VERSION ""

NS_ :

BS_:

BU_: FLC2 DACU

BO_ 2671902706 TesterFuncDiagMsg_Vic2: 8 DACU
 SG_ FuncDiagDataTester : 0|64@1+ (1,0) [0|0] ""  FLC2

BO_ 2671833681 PhysDiagRespMsg_F2_51_Vic2: 8 FLC2
 SG_ PhysDiagRespSig_F2_51 : 0|64@1+ (1,0) [0|0] ""  VCM

BO_ 2671792626 PhysDiagReqMsg_51_F2_Vic2: 8 DACU
 SG_ PhysDiagReqSig_51_F2 : 0|64@1+ (1,0) [0|0] ""  FLC2

BO_ 2671902708 IntTesterTGW2FuncDiagMsg_Vic2: 8 DACU
 SG_ FuncDiagDataIntTesterTGW2 : 0|64@1+ (1,0) [0|0] ""  FLC2

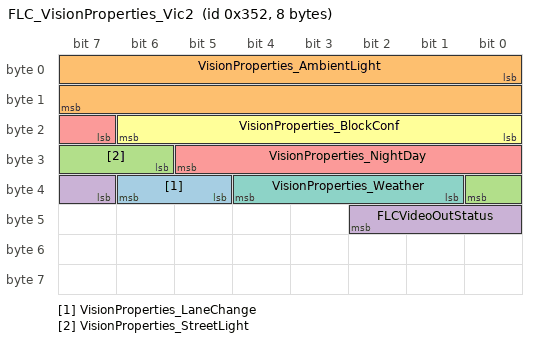
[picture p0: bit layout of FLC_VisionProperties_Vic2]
BO_ 850 FLC_VisionProperties_Vic2: 8 FLC2
 SG_ VisionProperties_LaneChange : 37|2@1+ (1,0) [0|0] ""  VCM
 SG_ VisionProperties_AmbientLight : 0|16@1+ (1,0) [0|65535] "lx"  VCM
 SG_ VisionProperties_StreetLight : 30|3@1+ (1,0) [0|0] ""  VCM
 SG_ FLCVideoOutStatus : 39|4@1+ (1,0) [0|0] ""  VCM
 SG_ VisionProperties_NightDay : 23|7@1+ (0.01,0) [0|1.27] "NotApplicable"  VCM
 SG_ VisionProperties_BlockConf : 16|7@1+ (0.01,0) [0|1.27] "NotApplicable"  VCM
 SG_ VisionProperties_Weather : 33|4@1+ (1,0) [0|0] ""  VCM

BO_ 872 FLC_TrafficSign11_Vic2: 32 FLC2
 SG_ TrafficSign11_SupplSignValue01 : 0|8@1+ (1,0) [0|255] ""  VCM
 SG_ TrafficSign11_SupplSignType02 : 94|7@1+ (1,0) [0|0] ""  VCM
 SG_ TrafficSign11_TrackStatus : 101|3@1+ (1,0) [0|0] ""  VCM
 SG_ TrafficSign11_SupplSignValue02 : 40|8@1+ (1,0) [0|255] ""  VCM
 SG_ TrafficSign11_RestDist : 139|15@1+ (1,0) [0|32767] "m"  VCM
 SG_ TrafficSign11_MainSignValue : 24|8@1+ (1,0) [0|255] ""  VCM
 SG_ TrafficSign11_SupplSignType01 : 87|7@1+ (1,0) [0|0] ""  VCM
 SG_ TrafficSign11_RestHeight : 181|7@1+ (0.1,0) [0|12.7] "m"  VCM
 SG_ TrafficSign11_SupplSign02Conf : 125|7@1+ (0.01,0) [0|1.27] ""  VCM
 SG_ TrafficSign11_MainSignConfidence : 104|7@1+ (0.01,0) [0|1.27] ""  VCM
 SG_ TrafficSign11_RestSection : 154|17@1+ (1,0) [0|131071] "m"  VCM
 SG_ TrafficSign11_RestTime1 : 213|11@1+ (1,0) [0|2047] "min"  VCM
 SG_ TrafficSign11_TimeStamp : 48|16@1+ (0.1,0) [0|6553.5] "ms"  VCM
 SG_ TrafficSign11_RestWeight : 171|10@1+ (0.1,0) [0|102.3] "NotApplicable"  VCM
 SG_ TrafficSign11_RestWidth : 188|7@1+ (0.1,0) [0|12.7] "m"  VCM
 SG_ TrafficSign11_Height : 64|5@1+ (0.2,0) [0|6.2] "m"  VCM
 SG_ TrafficSign11_MainSignType : 73|7@1+ (1,0) [0|0] ""  VCM
 SG_ TrafficSign11_ID : 32|8@1+ (1,0) [0|255] ""  VCM
 SG_ TrafficSign11_RestTime3 : 235|11@1+ (1,0) [0|2047] "min"  VCM
 SG_ TrafficSign11_SupplSignValue00 : 8|8@1+ (1,0) [0|255] ""  VCM
 SG_ TrafficSign11_RestDay : 195|7@1+ (1,0) [0|127] "NotApplicable"  VCM
 SG_ TrafficSign11_LongDist : 16|8@1+ (0.5,-20) [-20|107.5] "m"  VCM
 SG_ TrafficSign11_RestTime2 : 224|11@1+ (1,0) [0|2047] "min"  VCM
 SG_ TrafficSign11_SupplSignType00 : 80|7@1+ (1,0) [0|0] ""  VCM
 SG_ TrafficSign11_SupplSign00Conf : 111|7@1+ (0.01,0) [0|1.27] ""  VCM
 SG_ TrafficSign11_SupplSign01Conf : 118|7@1+ (0.01,0) [0|1.27] ""  VCM
 SG_ TrafficSign11_LatDist : 132|7@1+ (0.5,-31) [-31|32.5] "m"  VCM
 SG_ TrafficSign11_RestTime0 : 202|11@1+ (1,0) [0|2047] "min"  VCM
 SG_ TrafficSign11_SignStability : 72|1@1+ (1,0) [0|0] ""  VCM

BO_ 871 FLC_TrafficSign10_Vic2: 32 FLC2
 SG_ TrafficSign10_SupplSignType02 : 94|7@1+ (1,0) [0|0] ""  VCM
 SG_ TrafficSign10_SignStability : 72|1@1+ (1,0) [0|0] ""  VCM
 SG_ TrafficSign10_ID : 32|8@1+ (1,0) [0|255] ""  VCM
 SG_ TrafficSign10_SupplSignValue00 : 8|8@1+ (1,0) [0|255] ""  VCM
 SG_ TrafficSign10_RestTime2 : 224|11@1+ (1,0) [0|2047] "min"  VCM
 SG_ TrafficSign10_RestSection : 154|17@1+ (1,0) [0|131071] "m"  VCM
 SG_ TrafficSign10_SupplSign00Conf : 111|7@1+ (0.01,0) [0|1.27] ""  VCM
 SG_ TrafficSign10_MainSignType : 73|7@1+ (1,0) [0|0] ""  VCM
 SG_ TrafficSign10_RestTime3 : 235|11@1+ (1,0) [0|2047] "min"  VCM
 SG_ TrafficSign10_RestHeight : 181|7@1+ (0.1,0) [0|12.7] "m"  VCM
 SG_ TrafficSign10_RestTime1 : 213|11@1+ (1,0) [0|2047] "min"  VCM
 SG_ TrafficSign10_SupplSignType01 : 87|7@1+ (1,0) [0|0] ""  VCM
 SG_ TrafficSign10_RestWidth : 188|7@1+ (0.1,0) [0|12.7] "m"  VCM
 SG_ TrafficSign10_SupplSign02Conf : 125|7@1+ (0.01,0) [0|1.27] ""  VCM
 SG_ TrafficSign10_SupplSignValue01 : 0|8@1+ (1,0) [0|255] ""  VCM
 SG_ TrafficSign10_TimeStamp : 48|16@1+ (0.1,0) [0|6553.5] "ms"  VCM
 SG_ TrafficSign10_LongDist : 16|8@1+ (0.5,-20) [-20|107.5] "m"  VCM
 SG_ TrafficSign10_SupplSignValue02 : 40|8@1+ (1,0) [0|255] ""  VCM
 SG_ TrafficSign10_SupplSign01Conf : 118|7@1+ (0.01,0) [0|1.27] ""  VCM
 SG_ TrafficSign10_SupplSignType00 : 80|7@1+ (1,0) [0|0] ""  VCM
 SG_ TrafficSign10_Height : 64|5@1+ (0.2,0) [0|6.2] "m"  VCM
 SG_ TrafficSign10_TrackStatus : 101|3@1+ (1,0) [0|0] ""  VCM
 SG_ TrafficSign10_RestWeight : 171|10@1+ (0.1,0) [0|102.3] "NotApplicable"  VCM
 SG_ TrafficSign10_RestDay : 195|7@1+ (1,0) [0|127] "NotApplicable"  VCM
 SG_ TrafficSign10_MainSignConfidence : 104|7@1+ (0.01,0) [0|1.27] ""  VCM
 SG_ TrafficSign10_RestDist : 139|15@1+ (1,0) [0|32767] "m"  VCM
 SG_ TrafficSign10_RestTime0 : 202|11@1+ (1,0) [0|2047] "min"  VCM
 SG_ TrafficSign10_MainSignValue : 24|8@1+ (1,0) [0|255] ""  VCM
 SG_ TrafficSign10_LatDist : 132|7@1+ (0.5,-31) [-31|32.5] "m"  VCM

BO_ 870 FLC_TrafficSign09_Vic2: 32 FLC2
 SG_ TrafficSign09_MainSignValue : 24|8@1+ (1,0) [0|255] ""  VCM
 SG_ TrafficSign09_RestTime0 : 202|11@1+ (1,0) [0|2047] "min"  VCM
 SG_ TrafficSign09_LongDist : 16|8@1+ (0.5,-20) [-20|107.5] "m"  VCM
 SG_ TrafficSign09_SupplSign00Conf : 111|7@1+ (0.01,0) [0|1.27] ""  VCM
 SG_ TrafficSign09_MainSignConfidence : 104|7@1+ (0.01,0) [0|1.27] ""  VCM
 SG_ TrafficSign09_Height : 64|5@1+ (0.2,0) [0|6.2] "m"  VCM
 SG_ TrafficSign09_RestTime2 : 224|11@1+ (1,0) [0|2047] "min"  VCM
 SG_ TrafficSign09_MainSignType : 73|7@1+ (1,0) [0|0] ""  VCM
 SG_ TrafficSign09_SupplSignType02 : 94|7@1+ (1,0) [0|0] ""  VCM
 SG_ TrafficSign09_SupplSign01Conf : 118|7@1+ (0.01,0) [0|1.27] ""  VCM
 SG_ TrafficSign09_RestSection : 154|17@1+ (1,0) [0|131071] "m"  VCM
 SG_ TrafficSign09_SupplSign02Conf : 125|7@1+ (0.01,0) [0|1.27] ""  VCM
 SG_ TrafficSign09_SupplSignValue01 : 0|8@1+ (1,0) [0|255] ""  VCM
 SG_ TrafficSign09_RestWeight : 171|10@1+ (0.1,0) [0|102.3] "NotApplicable"  VCM
 SG_ TrafficSign09_LatDist : 132|7@1+ (0.5,-31) [-31|32.5] "m"  VCM
 SG_ TrafficSign09_SignStability : 72|1@1+ (1,0) [0|0] ""  VCM
 SG_ TrafficSign09_RestTime1 : 213|11@1+ (1,0) [0|2047] "min"  VCM
 SG_ TrafficSign09_SupplSignType00 : 80|7@1+ (1,0) [0|0] ""  VCM
 SG_ TrafficSign09_RestHeight : 181|7@1+ (0.1,0) [0|12.7] "m"  VCM
 SG_ TrafficSign09_RestDay : 195|7@1+ (1,0) [0|127] "NotApplicable"  VCM
 SG_ TrafficSign09_RestDist : 139|15@1+ (1,0) [0|32767] "m"  VCM
 SG_ TrafficSign09_SupplSignValue00 : 8|8@1+ (1,0) [0|255] ""  VCM
 SG_ TrafficSign09_TrackStatus : 101|3@1+ (1,0) [0|0] ""  VCM
 SG_ TrafficSign09_RestTime3 : 235|11@1+ (1,0) [0|2047] "min"  VCM
 SG_ TrafficSign09_SupplSignType01 : 87|7@1+ (1,0) [0|0] ""  VCM
 SG_ TrafficSign09_ID : 32|8@1+ (1,0) [0|255] ""  VCM
 SG_ TrafficSign09_RestWidth : 188|7@1+ (0.1,0) [0|12.7] "m"  VCM
 SG_ TrafficSign09_SupplSignValue02 : 40|8@1+ (1,0) [0|255] ""  VCM
 SG_ TrafficSign09_TimeStamp : 48|16@1+ (0.1,0) [0|6553.5] "ms"  VCM

BO_ 869 FLC_TrafficSign08_Vic2: 32 FLC2
 SG_ TrafficSign08_SupplSign00Conf : 111|7@1+ (0.01,0) [0|1.27] ""  VCM
 SG_ TrafficSign08_SignStability : 72|1@1+ (1,0) [0|0] ""  VCM
 SG_ TrafficSign08_MainSignType : 73|7@1+ (1,0) [0|0] ""  VCM
 SG_ TrafficSign08_SupplSign02Conf : 125|7@1+ (0.01,0) [0|1.27] ""  VCM
 SG_ TrafficSign08_RestHeight : 181|7@1+ (0.1,0) [0|12.7] "m"  VCM
 SG_ TrafficSign08_LatDist : 132|7@1+ (0.5,-31) [-31|32.5] "m"  VCM
 SG_ TrafficSign08_SupplSignType02 : 94|7@1+ (1,0) [0|0] ""  VCM
 SG_ TrafficSign08_SupplSignType01 : 87|7@1+ (1,0) [0|0] ""  VCM
 SG_ TrafficSign08_SupplSign01Conf : 118|7@1+ (0.01,0) [0|1.27] ""  VCM
 SG_ TrafficSign08_MainSignConfidence : 104|7@1+ (0.01,0) [0|1.27] ""  VCM
 SG_ TrafficSign08_RestSection : 154|17@1+ (1,0) [0|131071] "m"  VCM
 SG_ TrafficSign08_RestTime3 : 235|11@1+ (1,0) [0|2047] "min"  VCM
 SG_ TrafficSign08_TimeStamp : 48|16@1+ (0.1,0) [0|6553.5] "ms"  VCM
 SG_ TrafficSign08_RestDist : 139|15@1+ (1,0) [0|32767] "m"  VCM
 SG_ TrafficSign08_SupplSignType00 : 80|7@1+ (1,0) [0|0] ""  VCM
 SG_ TrafficSign08_RestTime2 : 224|11@1+ (1,0) [0|2047] "min"  VCM
 SG_ TrafficSign08_SupplSignValue02 : 40|8@1+ (1,0) [0|255] ""  VCM
 SG_ TrafficSign08_TrackStatus : 101|3@1+ (1,0) [0|0] ""  VCM
 SG_ TrafficSign08_RestWeight : 171|10@1+ (0.1,0) [0|102.3] "NotApplicable"  VCM
 SG_ TrafficSign08_SupplSignValue01 : 0|8@1+ (1,0) [0|255] ""  VCM
 SG_ TrafficSign08_RestTime0 : 202|11@1+ (1,0) [0|2047] "min"  VCM
 SG_ TrafficSign08_LongDist : 16|8@1+ (0.5,-20) [-20|107.5] "m"  VCM
 SG_ TrafficSign08_MainSignValue : 24|8@1+ (1,0) [0|255] ""  VCM
 SG_ TrafficSign08_RestWidth : 188|7@1+ (0.1,0) [0|12.7] "m"  VCM
 SG_ TrafficSign08_RestDay : 195|7@1+ (1,0) [0|127] "NotApplicable"  VCM
 SG_ TrafficSign08_ID : 32|8@1+ (1,0) [0|255] ""  VCM
 SG_ TrafficSign08_Height : 64|5@1+ (0.2,0) [0|6.2] "m"  VCM
 SG_ TrafficSign08_SupplSignValue00 : 8|8@1+ (1,0) [0|255] ""  VCM
 SG_ TrafficSign08_RestTime1 : 213|11@1+ (1,0) [0|2047] "min"  VCM

BO_ 868 FLC_TrafficSign07_Vic2: 32 FLC2
 SG_ TrafficSign07_MainSignConfidence : 104|7@1+ (0.01,0) [0|1.27] ""  VCM
 SG_ TrafficSign07_SupplSign00Conf : 111|7@1+ (0.01,0) [0|1.27] ""  VCM
 SG_ TrafficSign07_SupplSign01Conf : 118|7@1+ (0.01,0) [0|1.27] ""  VCM
 SG_ TrafficSign07_SupplSignValue00 : 8|8@1+ (1,0) [0|255] ""  VCM
 SG_ TrafficSign07_RestTime3 : 235|11@1+ (1,0) [0|2047] "min"  VCM
 SG_ TrafficSign07_SupplSign02Conf : 125|7@1+ (0.01,0) [0|1.27] ""  VCM
 SG_ TrafficSign07_ID : 32|8@1+ (1,0) [0|255] ""  VCM
 SG_ TrafficSign07_SupplSignType01 : 87|7@1+ (1,0) [0|0] ""  VCM
 SG_ TrafficSign07_TrackStatus : 101|3@1+ (1,0) [0|0] ""  VCM
 SG_ TrafficSign07_RestSection : 154|17@1+ (1,0) [0|131071] "m"  VCM
 SG_ TrafficSign07_SupplSignValue02 : 40|8@1+ (1,0) [0|255] ""  VCM
 SG_ TrafficSign07_SupplSignType00 : 80|7@1+ (1,0) [0|0] ""  VCM
 SG_ TrafficSign07_RestTime2 : 224|11@1+ (1,0) [0|2047] "min"  VCM
 SG_ TrafficSign07_Height : 64|5@1+ (0.2,0) [0|6.2] "m"  VCM
 SG_ TrafficSign07_LatDist : 132|7@1+ (0.5,-31) [-31|32.5] "m"  VCM
 SG_ TrafficSign07_SupplSignType02 : 94|7@1+ (1,0) [0|0] ""  VCM
 SG_ TrafficSign07_SignStability : 72|1@1+ (1,0) [0|0] ""  VCM
 SG_ TrafficSign07_RestDist : 139|15@1+ (1,0) [0|32767] "m"  VCM
 SG_ TrafficSign07_RestDay : 195|7@1+ (1,0) [0|127] "NotApplicable"  VCM
 SG_ TrafficSign07_RestWidth : 188|7@1+ (0.1,0) [0|12.7] "m"  VCM
 SG_ TrafficSign07_TimeStamp : 48|16@1+ (0.1,0) [0|6553.5] "ms"  VCM
 SG_ TrafficSign07_RestTime1 : 213|11@1+ (1,0) [0|2047] "min"  VCM
 SG_ TrafficSign07_RestTime0 : 202|11@1+ (1,0) [0|2047] "min"  VCM
 SG_ TrafficSign07_SupplSignValue01 : 0|8@1+ (1,0) [0|255] ""  VCM
 SG_ TrafficSign07_LongDist : 16|8@1+ (0.5,-20) [-20|107.5] "m"  VCM
 SG_ TrafficSign07_MainSignType : 73|7@1+ (1,0) [0|0] ""  VCM
 SG_ TrafficSign07_MainSignValue : 24|8@1+ (1,0) [0|255] ""  VCM
 SG_ TrafficSign07_RestWeight : 171|10@1+ (0.1,0) [0|102.3] "NotApplicable"  VCM
 SG_ TrafficSign07_RestHeight : 181|7@1+ (0.1,0) [0|12.7] "m"  VCM

BO_ 867 FLC_TrafficSign06_Vic2: 32 FLC2
 SG_ TrafficSign06_RestWeight : 171|10@1+ (0.1,0) [0|102.3] "NotApplicable"  VCM
 SG_ TrafficSign06_SupplSign01Conf : 118|7@1+ (0.01,0) [0|1.27] ""  VCM
 SG_ TrafficSign06_SupplSignValue02 : 40|8@1+ (1,0) [0|255] ""  VCM
 SG_ TrafficSign06_RestTime1 : 213|11@1+ (1,0) [0|2047] "min"  VCM
 SG_ TrafficSign06_SupplSignType02 : 94|7@1+ (1,0) [0|0] ""  VCM
 SG_ TrafficSign06_SignStability : 72|1@1+ (1,0) [0|0] ""  VCM
 SG_ TrafficSign06_SupplSign00Conf : 111|7@1+ (0.01,0) [0|1.27] ""  VCM
 SG_ TrafficSign06_MainSignValue : 24|8@1+ (1,0) [0|255] ""  VCM
 SG_ TrafficSign06_SupplSign02Conf : 125|7@1+ (0.01,0) [0|1.27] ""  VCM
 SG_ TrafficSign06_SupplSignValue01 : 0|8@1+ (1,0) [0|255] ""  VCM
 SG_ TrafficSign06_RestTime2 : 224|11@1+ (1,0) [0|2047] "min"  VCM
 SG_ TrafficSign06_Height : 64|5@1+ (0.2,0) [0|6.2] "m"  VCM
 SG_ TrafficSign06_LatDist : 132|7@1+ (0.5,-31) [-31|32.5] "m"  VCM
 SG_ TrafficSign06_MainSignType : 73|7@1+ (1,0) [0|0] ""  VCM
 SG_ TrafficSign06_LongDist : 16|8@1+ (0.5,-20) [-20|107.5] "m"  VCM
 SG_ TrafficSign06_TimeStamp : 48|16@1+ (0.1,0) [0|6553.5] "ms"  VCM
 SG_ TrafficSign06_RestDist : 139|15@1+ (1,0) [0|32767] "m"  VCM
 SG_ TrafficSign06_RestTime0 : 202|11@1+ (1,0) [0|2047] "min"  VCM
 SG_ TrafficSign06_SupplSignType01 : 87|7@1+ (1,0) [0|0] ""  VCM
 SG_ TrafficSign06_TrackStatus : 101|3@1+ (1,0) [0|0] ""  VCM
 SG_ TrafficSign06_MainSignConfidence : 104|7@1+ (0.01,0) [0|1.27] ""  VCM
 SG_ TrafficSign06_RestHeight : 181|7@1+ (0.1,0) [0|12.7] "m"  VCM
 SG_ TrafficSign06_RestSection : 154|17@1+ (1,0) [0|131071] "m"  VCM
 SG_ TrafficSign06_RestDay : 195|7@1+ (1,0) [0|127] "NotApplicable"  VCM
 SG_ TrafficSign06_SupplSignValue00 : 8|8@1+ (1,0) [0|255] ""  VCM
 SG_ TrafficSign06_ID : 32|8@1+ (1,0) [0|255] ""  VCM
 SG_ TrafficSign06_RestWidth : 188|7@1+ (0.1,0) [0|12.7] "m"  VCM
 SG_ TrafficSign06_RestTime3 : 235|11@1+ (1,0) [0|2047] "min"  VCM
 SG_ TrafficSign06_SupplSignType00 : 80|7@1+ (1,0) [0|0] ""  VCM

BO_ 866 FLC_TrafficSign05_Vic2: 32 FLC2
 SG_ TrafficSign05_SupplSignType00 : 80|7@1+ (1,0) [0|0] ""  VCM
 SG_ TrafficSign05_ID : 32|8@1+ (1,0) [0|255] ""  VCM
 SG_ TrafficSign05_SupplSignValue00 : 8|8@1+ (1,0) [0|255] ""  VCM
 SG_ TrafficSign05_MainSignConfidence : 104|7@1+ (0.01,0) [0|1.27] ""  VCM
 SG_ TrafficSign05_RestDay : 195|7@1+ (1,0) [0|127] "NotApplicable"  VCM
 SG_ TrafficSign05_MainSignType : 73|7@1+ (1,0) [0|0] ""  VCM
 SG_ TrafficSign05_SupplSignType01 : 87|7@1+ (1,0) [0|0] ""  VCM
 SG_ TrafficSign05_LongDist : 16|8@1+ (0.5,-20) [-20|107.5] "m"  VCM
 SG_ TrafficSign05_RestSection : 154|17@1+ (1,0) [0|131071] "m"  VCM
 SG_ TrafficSign05_MainSignValue : 24|8@1+ (1,0) [0|255] ""  VCM
 SG_ TrafficSign05_SupplSignValue01 : 0|8@1+ (1,0) [0|255] ""  VCM
 SG_ TrafficSign05_TimeStamp : 48|16@1+ (0.1,0) [0|6553.5] "ms"  VCM
 SG_ TrafficSign05_Height : 64|5@1+ (0.2,0) [0|6.2] "m"  VCM
 SG_ TrafficSign05_SupplSign02Conf : 125|7@1+ (0.01,0) [0|1.27] ""  VCM
 SG_ TrafficSign05_SignStability : 72|1@1+ (1,0) [0|0] ""  VCM
 SG_ TrafficSign05_SupplSignValue02 : 40|8@1+ (1,0) [0|255] ""  VCM
 SG_ TrafficSign05_TrackStatus : 101|3@1+ (1,0) [0|0] ""  VCM
 SG_ TrafficSign05_LatDist : 132|7@1+ (0.5,-31) [-31|32.5] "m"  VCM
 SG_ TrafficSign05_RestHeight : 181|7@1+ (0.1,0) [0|12.7] "m"  VCM
 SG_ TrafficSign05_RestTime1 : 213|11@1+ (1,0) [0|2047] "min"  VCM
 SG_ TrafficSign05_RestWidth : 188|7@1+ (0.1,0) [0|12.7] "m"  VCM
 SG_ TrafficSign05_RestTime3 : 235|11@1+ (1,0) [0|2047] "min"  VCM
 SG_ TrafficSign05_RestDist : 139|15@1+ (1,0) [0|32767] "m"  VCM
 SG_ TrafficSign05_RestTime2 : 224|11@1+ (1,0) [0|2047] "min"  VCM
 SG_ TrafficSign05_RestTime0 : 202|11@1+ (1,0) [0|2047] "min"  VCM
 SG_ TrafficSign05_SupplSign00Conf : 111|7@1+ (0.01,0) [0|1.27] ""  VCM
 SG_ TrafficSign05_SupplSignType02 : 94|7@1+ (1,0) [0|0] ""  VCM
 SG_ TrafficSign05_SupplSign01Conf : 118|7@1+ (0.01,0) [0|1.27] ""  VCM
 SG_ TrafficSign05_RestWeight : 171|10@1+ (0.1,0) [0|102.3] "NotApplicable"  VCM

BO_ 865 FLC_TrafficSign04_Vic2: 32 FLC2
 SG_ TrafficSign04_TrackStatus : 101|3@1+ (1,0) [0|0] ""  VCM
 SG_ TrafficSign04_MainSignType : 73|7@1+ (1,0) [0|0] ""  VCM
 SG_ TrafficSign04_SupplSignValue00 : 8|8@1+ (1,0) [0|255] ""  VCM
 SG_ TrafficSign04_RestTime1 : 213|11@1+ (1,0) [0|2047] "min"  VCM
 SG_ TrafficSign04_SupplSignValue01 : 0|8@1+ (1,0) [0|255] ""  VCM
 SG_ TrafficSign04_RestTime2 : 224|11@1+ (1,0) [0|2047] "min"  VCM
 SG_ TrafficSign04_Height : 64|5@1+ (0.2,0) [0|6.2] "m"  VCM
 SG_ TrafficSign04_SupplSign00Conf : 111|7@1+ (0.01,0) [0|1.27] ""  VCM
 SG_ TrafficSign04_SupplSign01Conf : 118|7@1+ (0.01,0) [0|1.27] ""  VCM
 SG_ TrafficSign04_SupplSign02Conf : 125|7@1+ (0.01,0) [0|1.27] ""  VCM
 SG_ TrafficSign04_SupplSignType02 : 94|7@1+ (1,0) [0|0] ""  VCM
 SG_ TrafficSign04_LongDist : 16|8@1+ (0.5,-20) [-20|107.5] "m"  VCM
 SG_ TrafficSign04_RestTime0 : 202|11@1+ (1,0) [0|2047] "min"  VCM
 SG_ TrafficSign04_RestWidth : 188|7@1+ (0.1,0) [0|12.7] "m"  VCM
 SG_ TrafficSign04_SupplSignType00 : 80|7@1+ (1,0) [0|0] ""  VCM
 SG_ TrafficSign04_RestDay : 195|7@1+ (1,0) [0|127] "NotApplicable"  VCM
 SG_ TrafficSign04_SupplSignType01 : 87|7@1+ (1,0) [0|0] ""  VCM
 SG_ TrafficSign04_MainSignConfidence : 104|7@1+ (0.01,0) [0|1.27] ""  VCM
 SG_ TrafficSign04_RestHeight : 181|7@1+ (0.1,0) [0|12.7] "m"  VCM
 SG_ TrafficSign04_MainSignValue : 24|8@1+ (1,0) [0|255] ""  VCM
 SG_ TrafficSign04_RestSection : 154|17@1+ (1,0) [0|131071] "m"  VCM
 SG_ TrafficSign04_RestDist : 139|15@1+ (1,0) [0|32767] "m"  VCM
 SG_ TrafficSign04_ID : 32|8@1+ (1,0) [0|255] ""  VCM
 SG_ TrafficSign04_RestTime3 : 235|11@1+ (1,0) [0|2047] "min"  VCM
 SG_ TrafficSign04_SignStability : 72|1@1+ (1,0) [0|0] ""  VCM
 SG_ TrafficSign04_LatDist : 132|7@1+ (0.5,-31) [-31|32.5] "m"  VCM
 SG_ TrafficSign04_TimeStamp : 48|16@1+ (0.1,0) [0|6553.5] "ms"  VCM
 SG_ TrafficSign04_SupplSignValue02 : 40|8@1+ (1,0) [0|255] ""  VCM
 SG_ TrafficSign04_RestWeight : 171|10@1+ (0.1,0) [0|102.3] "NotApplicable"  VCM

BO_ 849 FLC_TrafficSign03_Vic2: 32 FLC2
 SG_ TrafficSign03_Height : 64|5@1+ (0.2,0) [0|6.2] "m"  VCM
 SG_ TrafficSign03_ID : 32|8@1+ (1,0) [0|255] ""  VCM
 SG_ TrafficSign03_TrackStatus : 101|3@1+ (1,0) [0|0] ""  VCM
 SG_ TrafficSign03_RestHeight : 181|7@1+ (0.1,0) [0|12.7] "m"  VCM
 SG_ TrafficSign03_MainSignConfidence : 104|7@1+ (0.01,0) [0|1.27] ""  VCM
 SG_ TrafficSign03_RestDay : 195|7@1+ (1,0) [0|127] "NotApplicable"  VCM
 SG_ TrafficSign03_LongDist : 16|8@1+ (0.5,-20) [-20|107.5] "m"  VCM
 SG_ TrafficSign03_RestTime3 : 235|11@1+ (1,0) [0|2047] "min"  VCM
 SG_ TrafficSign03_SupplSignType00 : 80|7@1+ (1,0) [0|0] ""  VCM
 SG_ TrafficSign03_RestTime1 : 213|11@1+ (1,0) [0|2047] "min"  VCM
 SG_ TrafficSign03_SupplSignValue00 : 8|8@1+ (1,0) [0|255] ""  VCM
 SG_ TrafficSign03_RestTime0 : 202|11@1+ (1,0) [0|2047] "min"  VCM
 SG_ TrafficSign03_SupplSignType02 : 94|7@1+ (1,0) [0|0] ""  VCM
 SG_ TrafficSign03_RestWidth : 188|7@1+ (0.1,0) [0|12.7] "m"  VCM
 SG_ TrafficSign03_MainSignValue : 24|8@1+ (1,0) [0|255] ""  VCM
 SG_ TrafficSign03_RestTime2 : 224|11@1+ (1,0) [0|2047] "min"  VCM
 SG_ TrafficSign03_SupplSign01Conf : 118|7@1+ (0.01,0) [0|1.27] ""  VCM
 SG_ TrafficSign03_LatDist : 132|7@1+ (0.5,-31) [-31|32.5] "m"  VCM
 SG_ TrafficSign03_RestWeight : 171|10@1+ (0.1,0) [0|102.3] "NotApplicable"  VCM
 SG_ TrafficSign03_TimeStamp : 48|16@1+ (0.1,0) [0|6553.5] "ms"  VCM
 SG_ TrafficSign03_RestDist : 139|15@1+ (1,0) [0|32767] "m"  VCM
 SG_ TrafficSign03_SupplSign00Conf : 111|7@1+ (0.01,0) [0|1.27] ""  VCM
 SG_ TrafficSign03_SupplSignType01 : 87|7@1+ (1,0) [0|0] ""  VCM
 SG_ TrafficSign03_SupplSign02Conf : 125|7@1+ (0.01,0) [0|1.27] ""  VCM
 SG_ TrafficSign03_RestSection : 154|17@1+ (1,0) [0|131071] "m"  VCM
 SG_ TrafficSign03_SupplSignValue02 : 40|8@1+ (1,0) [0|255] ""  VCM
 SG_ TrafficSign03_MainSignType : 73|7@1+ (1,0) [0|0] ""  VCM
 SG_ TrafficSign03_SignStability : 72|1@1+ (1,0) [0|0] ""  VCM
 SG_ TrafficSign03_SupplSignValue01 : 0|8@1+ (1,0) [0|255] ""  VCM

BO_ 848 FLC_TrafficSign02_Vic2: 32 FLC2
 SG_ TrafficSign02_RestTime1 : 213|11@1+ (1,0) [0|2047] "min"  VCM
 SG_ TrafficSign02_RestHeight : 181|7@1+ (0.1,0) [0|12.7] "m"  VCM
 SG_ TrafficSign02_Height : 64|5@1+ (0.2,0) [0|6.2] "m"  VCM
 SG_ TrafficSign02_SignStability : 72|1@1+ (1,0) [0|0] ""  VCM
 SG_ TrafficSign02_SupplSignType00 : 80|7@1+ (1,0) [0|0] ""  VCM
 SG_ TrafficSign02_ID : 32|8@1+ (1,0) [0|255] ""  VCM
 SG_ TrafficSign02_LatDist : 132|7@1+ (0.5,-31) [-31|32.5] "m"  VCM
 SG_ TrafficSign02_MainSignType : 73|7@1+ (1,0) [0|0] ""  VCM
 SG_ TrafficSign02_SupplSignValue01 : 0|8@1+ (1,0) [0|255] ""  VCM
 SG_ TrafficSign02_SupplSign00Conf : 111|7@1+ (0.01,0) [0|1.27] ""  VCM
 SG_ TrafficSign02_SupplSignType01 : 87|7@1+ (1,0) [0|0] ""  VCM
 SG_ TrafficSign02_RestTime2 : 224|11@1+ (1,0) [0|2047] "min"  VCM
 SG_ TrafficSign02_MainSignConfidence : 104|7@1+ (0.01,0) [0|1.27] ""  VCM
 SG_ TrafficSign02_SupplSignValue02 : 40|8@1+ (1,0) [0|255] ""  VCM
 SG_ TrafficSign02_TimeStamp : 48|16@1+ (0.1,0) [0|6553.5] "ms"  VCM
 SG_ TrafficSign02_RestSection : 154|17@1+ (1,0) [0|131071] "m"  VCM
 SG_ TrafficSign02_RestDist : 139|15@1+ (1,0) [0|32767] "m"  VCM
 SG_ TrafficSign02_RestDay : 195|7@1+ (1,0) [0|127] "NotApplicable"  VCM
 SG_ TrafficSign02_SupplSign02Conf : 125|7@1+ (0.01,0) [0|1.27] ""  VCM
 SG_ TrafficSign02_SupplSign01Conf : 118|7@1+ (0.01,0) [0|1.27] ""  VCM
 SG_ TrafficSign02_LongDist : 16|8@1+ (0.5,-20) [-20|107.5] "m"  VCM
 SG_ TrafficSign02_MainSignValue : 24|8@1+ (1,0) [0|255] ""  VCM
 SG_ TrafficSign02_TrackStatus : 101|3@1+ (1,0) [0|0] ""  VCM
 SG_ TrafficSign02_SupplSignType02 : 94|7@1+ (1,0) [0|0] ""  VCM
 SG_ TrafficSign02_RestWeight : 171|10@1+ (0.1,0) [0|102.3] "NotApplicable"  VCM
 SG_ TrafficSign02_RestTime0 : 202|11@1+ (1,0) [0|2047] "min"  VCM
 SG_ TrafficSign02_SupplSignValue00 : 8|8@1+ (1,0) [0|255] ""  VCM
 SG_ TrafficSign02_RestWidth : 188|7@1+ (0.1,0) [0|12.7] "m"  VCM
 SG_ TrafficSign02_RestTime3 : 235|11@1+ (1,0) [0|2047] "min"  VCM

BO_ 841 FLC_TrafficSign01_Vic2: 32 FLC2
 SG_ TrafficSign01_SupplSign02Conf : 125|7@1+ (0.01,0) [0|1.27] ""  VCM
 SG_ TrafficSign01_RestTime0 : 202|11@1+ (1,0) [0|2047] "min"  VCM
 SG_ TrafficSign01_RestTime1 : 213|11@1+ (1,0) [0|2047] "min"  VCM
 SG_ TrafficSign01_RestTime3 : 235|11@1+ (1,0) [0|2047] "min"  VCM
 SG_ TrafficSign01_RestDay : 195|7@1+ (1,0) [0|127] "NotApplicable"  VCM
 SG_ TrafficSign01_ID : 32|8@1+ (1,0) [0|255] ""  VCM
 SG_ TrafficSign01_MainSignValue : 24|8@1+ (1,0) [0|255] ""  VCM
 SG_ TrafficSign01_MainSignType : 73|7@1+ (1,0) [0|0] ""  VCM
 SG_ TrafficSign01_LatDist : 132|7@1+ (0.5,-31) [-31|32.5] "m"  VCM
 SG_ TrafficSign01_RestWidth : 188|7@1+ (0.1,0) [0|12.7] "m"  VCM
 SG_ TrafficSign01_RestWeight : 171|10@1+ (0.1,0) [0|102.3] "NotApplicable"  VCM
 SG_ TrafficSign01_SupplSignType01 : 87|7@1+ (1,0) [0|0] ""  VCM
 SG_ TrafficSign01_SupplSignValue02 : 40|8@1+ (1,0) [0|255] ""  VCM
 SG_ TrafficSign01_SupplSignValue00 : 8|8@1+ (1,0) [0|255] ""  VCM
 SG_ TrafficSign01_TimeStamp : 48|16@1+ (0.1,0) [0|6553.5] "ms"  VCM
 SG_ TrafficSign01_SignStability : 72|1@1+ (1,0) [0|0] ""  VCM
 SG_ TrafficSign01_RestTime2 : 224|11@1+ (1,0) [0|2047] "min"  VCM
 SG_ TrafficSign01_SupplSign00Conf : 111|7@1+ (0.01,0) [0|1.27] ""  VCM
 SG_ TrafficSign01_SupplSignType02 : 94|7@1+ (1,0) [0|0] ""  VCM
 SG_ TrafficSign01_TrackStatus : 101|3@1+ (1,0) [0|0] ""  VCM
 SG_ TrafficSign01_SupplSign01Conf : 118|7@1+ (0.01,0) [0|1.27] ""  VCM
 SG_ TrafficSign01_LongDist : 16|8@1+ (0.5,-20) [-20|107.5] "m"  VCM
 SG_ TrafficSign01_Height : 64|5@1+ (0.2,0) [0|6.2] "m"  VCM
 SG_ TrafficSign01_SupplSignType00 : 80|7@1+ (1,0) [0|0] ""  VCM
 SG_ TrafficSign01_RestSection : 154|17@1+ (1,0) [0|131071] "m"  VCM
 SG_ TrafficSign01_MainSignConfidence : 104|7@1+ (0.01,0) [0|1.27] ""  VCM
 SG_ TrafficSign01_RestDist : 139|15@1+ (1,0) [0|32767] "m"  VCM
 SG_ TrafficSign01_RestHeight : 181|7@1+ (0.1,0) [0|12.7] "m"  VCM
 SG_ TrafficSign01_SupplSignValue01 : 0|8@1+ (1,0) [0|255] ""  VCM

BO_ 840 FLC_TrafficSign00_Vic2: 32 FLC2
 SG_ TrafficSign00_RestWidth : 188|7@1+ (0.1,0) [0|12.7] "m"  VCM
 SG_ TrafficSign00_RestTime3 : 235|11@1+ (1,0) [0|2047] "min"  VCM
 SG_ TrafficSign00_RestSection : 154|17@1+ (1,0) [0|131071] "m"  VCM
 SG_ TrafficSign00_SupplSignValue01 : 0|8@1+ (1,0) [0|255] ""  VCM
 SG_ TrafficSign00_SupplSignValue00 : 8|8@1+ (1,0) [0|255] ""  VCM
 SG_ TrafficSign00_SupplSign02Conf : 125|7@1+ (0.01,0) [0|1.27] ""  VCM
 SG_ TrafficSign00_ID : 32|8@1+ (1,0) [0|255] ""  VCM
 SG_ TrafficSign00_SupplSign01Conf : 118|7@1+ (0.01,0) [0|1.27] ""  VCM
 SG_ TrafficSign00_SupplSignType01 : 87|7@1+ (1,0) [0|0] ""  VCM
 SG_ TrafficSign00_SupplSignType00 : 80|7@1+ (1,0) [0|0] ""  VCM
 SG_ TrafficSign00_LongDist : 16|8@1+ (0.5,-20) [-20|107.5] "m"  VCM
 SG_ TrafficSign00_RestDay : 195|7@1+ (1,0) [0|127] "NotApplicable"  VCM
 SG_ TrafficSign00_MainSignConfidence : 104|7@1+ (0.01,0) [0|1.27] ""  VCM
 SG_ TrafficSign00_MainSignValue : 24|8@1+ (1,0) [0|255] ""  VCM
 SG_ TrafficSign00_Height : 64|5@1+ (0.2,0) [0|6.2] "m"  VCM
 SG_ TrafficSign00_SupplSignType02 : 94|7@1+ (1,0) [0|0] ""  VCM
 SG_ TrafficSign00_RestTime1 : 213|11@1+ (1,0) [0|2047] "min"  VCM
 SG_ TrafficSign00_RestHeight : 181|7@1+ (0.1,0) [0|12.7] "m"  VCM
 SG_ TrafficSign00_RestTime2 : 224|11@1+ (1,0) [0|2047] "min"  VCM
 SG_ TrafficSign00_RestTime0 : 202|11@1+ (1,0) [0|2047] "min"  VCM
 SG_ TrafficSign00_TrackStatus : 101|3@1+ (1,0) [0|0] ""  VCM
 SG_ TrafficSign00_RestDist : 139|15@1+ (1,0) [0|32767] "m"  VCM
 SG_ TrafficSign00_MainSignType : 73|7@1+ (1,0) [0|0] ""  VCM
 SG_ TrafficSign00_SignStability : 72|1@1+ (1,0) [0|0] ""  VCM
 SG_ TrafficSign00_SupplSignValue02 : 40|8@1+ (1,0) [0|255] ""  VCM
 SG_ TrafficSign00_LatDist : 132|7@1+ (0.5,-31) [-31|32.5] "m"  VCM
 SG_ TrafficSign00_TimeStamp : 48|16@1+ (0.1,0) [0|6553.5] "ms"  VCM
 SG_ TrafficSign00_SupplSign00Conf : 111|7@1+ (0.01,0) [0|1.27] ""  VCM
 SG_ TrafficSign00_RestWeight : 171|10@1+ (0.1,0) [0|102.3] "NotApplicable"  VCM

BO_ 858 FLC_EgoAssumptiont_Vic2: 12 FLC2
 SG_ FLCEgoAssumption_DynRoll : 0|8@1+ (0.0013,-0.12) [-0.12|0.2115] "rad"  VCM
 SG_ FLCEgoAssumption_EgoLongAcc : 56|16@1+ (0.00048828125,-15.6875) [-15.6875|16.31201171875] "m_per_s_squared"  VCM
 SG_ FLCEgoAssumption_CalibPitch : 16|8@1+ (0.0013,-0.12) [-0.12|0.2115] "rad"  VCM
 SG_ FLCEgoAssumption_EgoLongVel : 72|16@1+ (0.00108507,0) [0|71.11006245] "m_per_s"  VCM
 SG_ FLCEgoAssumption_CalibRoll : 48|8@1+ (0.0013,-0.12) [-0.12|0.2115] "rad"  VCM
 SG_ FLCEgoAssumption_TimeStamp : 32|16@1+ (0.1,0) [0|6553.5] "ms"  VCM
 SG_ FLCEgoAssumption_CalibYaw : 24|8@1+ (0.0013,-0.12) [-0.12|0.2115] "rad"  VCM
 SG_ FLCEgoAssumption_DynPitch : 8|8@1+ (0.0013,-0.12) [-0.12|0.2115] "rad"  VCM

CM_ "COM_MATRIX_T2_1.27.0";
CM_ BU_ FLC2 "Forward Looking Camera";
CM_ BU_ DACU "Driver Assistance Control Unit";
BA_DEF_ BO_  "GenMsgStartDelayTime" INT 0 0;
BA_DEF_ BO_  "GenMsgDelayTime" INT 0 0;
BA_DEF_ BO_  "GenMsgCycleTime" INT 0 0;
BA_DEF_ BO_  "GenMsgSendType" ENUM  "Cyclic","NotUsed","NotUsed","NotUsed","NotUsed","NotUsed","NotUsed","IfActive","NoMsgSendType","NotUsed";
BA_DEF_ SG_  "GenSigStartValue" INT 0 0;
BA_DEF_ SG_  "GenSigCycleTimeActive" INT 0 0;
BA_DEF_ SG_  "GenSigCycleTime" INT 0 0;
BA_DEF_ SG_  "GenSigSendType" ENUM  "Cyclic","OnWrite","OnWriteWithRepetition","OnChange","OnChangeWithRepetition","IfActive","IfActiveWithRepetition","NoSigSendType","NotUsed","NotUsed","NotUsed","NotUsed","NotUsed";
BA_DEF_  "Baudrate" INT 0 1000000;
BA_DEF_  "NmType" STRING ;
BA_DEF_  "Manufacturer" STRING ;
BA_DEF_  "VersionYear" INT 0 99;
BA_DEF_  "VersionNumber" INT 0 99;
BA_DEF_  "VersionMonth" INT 1 12;
BA_DEF_  "VersionDay" INT 1 31;
BA_DEF_ BO_  "VFrameFormat" ENUM  "StandardCAN","ExtendedCAN","reserved","J1939PG","reserved","reserved","reserved","reserved","reserved","reserved","reserved","reserved","reserved","reserved","StandardCAN_FD","ExtendedCAN_FD";
BA_DEF_ BU_  "TpOwnSystemEcuNumber" HEX 0 255;
BA_DEF_ SG_  "SigType" ENUM  "Default","Range","RangeSigned","ASCII","Discrete","Control","ReferencePGN","DTC","StringDelimiter","StringLength","StringLengthControl";
BA_DEF_ SG_  "SeToolVersion_SIGNAL" STRING ;
BA_DEF_ SG_  "SeToolUniqueID_SIGNAL" STRING ;
BA_DEF_ SG_  "SeToolName_SIGNAL" STRING ;
BA_DEF_ SG_  "SeToolItemID_SIGNAL" STRING ;
BA_DEF_ SG_  "SeToolAncestorID_SIGNAL" STRING ;
BA_DEF_  "ProtocolType" STRING ;
BA_DEF_ BU_  "NmStationAddress" INT 0 255;
BA_DEF_  "NmAsrWaitBusSleepTime" INT 0 65535;
BA_DEF_  "NmAsrTimeoutTime" INT 0 65535;
BA_DEF_  "NmAsrRepeatMessageTime" INT 0 65535;
BA_DEF_ BU_  "NmAsrNodeIdentifier" HEX 0 253;
BA_DEF_ BU_  "NmAsrNode" ENUM  "No","Yes";
BA_DEF_  "NmAsrMessageCount" INT 1 256;
BA_DEF_  "NmAsrCanMsgCycleTime" INT 0 65535;
BA_DEF_  "NmAsrBaseAddress" HEX 0 536870911;
BA_DEF_ SG_  "NeedsUpdateBit" ENUM  "No","Yes";
BA_DEF_ SG_  "GenSigILSupport" ENUM  "Yes","No";
BA_DEF_ BO_  "GenMsgILSupport" ENUM  "No","Yes";
BA_DEF_ SG_  "E2EProfile" STRING ;
BA_DEF_  "E2EP05WindowSize" INT 0 65535;
BA_DEF_  "E2EP05ProfileName" STRING ;
BA_DEF_  "E2EP05MinOkStateValid" INT 0 65535;
BA_DEF_  "E2EP05MinOkStateInvalid" INT 0 65535;
BA_DEF_  "E2EP05MinOkStateInit" INT 0 65535;
BA_DEF_  "E2EP05MaxErrorStateValid" INT 0 65535;
BA_DEF_  "E2EP05MaxErrorStateInvalid" INT 0 65535;
BA_DEF_  "E2EP05MaxErrorStateInit" INT 0 65535;
BA_DEF_  "E2EP05MaxDeltaCounter" INT 0 65535;
BA_DEF_  "E2EP01WindowSize" INT 0 65535;
BA_DEF_  "E2EP01SyncCounterInit" INT 0 65535;
BA_DEF_  "E2EP01ProfileName" STRING ;
BA_DEF_  "E2EP01MinOkStateValid" INT 0 65535;
BA_DEF_  "E2EP01MinOkStateInvalid" INT 0 65535;
BA_DEF_  "E2EP01MinOkStateInit" INT 0 65535;
BA_DEF_  "E2EP01MaxNoNewOrRepeatedData" INT 0 65535;
BA_DEF_  "E2EP01MaxErrorStateValid" INT 0 65535;
BA_DEF_  "E2EP01MaxErrorStateInvalid" INT 0 65535;
BA_DEF_  "E2EP01MaxErrorStateInit" INT 0 65535;
BA_DEF_  "E2EP01MaxDeltaCounter" INT 0 65535;
BA_DEF_  "E2EP01DataIdMode" ENUM  "all16Bit","alternating8Bit","lower12Bit","lower8Bit";
BA_DEF_  "E2EP01CounterOffset" INT 0 65535;
BA_DEF_ SG_  "E2EDataLength" INT 0 65535;
BA_DEF_ SG_  "E2EDataId" INT 0 65535;
BA_DEF_ BO_  "DiagUUDTResponse" ENUM  "No","Yes";
BA_DEF_ BO_  "DiagState" ENUM  "No","Yes";
BA_DEF_ BO_  "DiagResponse" ENUM  "No","Yes";
BA_DEF_ BO_  "DiagRequest" ENUM  "No","Yes";
BA_DEF_ BO_  "DiagConnection" HEX 0 65535;
BA_DEF_  "DBName" STRING ;
BA_DEF_ BO_  "CanTpFcFrameId" HEX 0 2147483647;
BA_DEF_ BO_  "CanTpBs" INT 0 255;
BA_DEF_ BO_  "CANFD_BRS" ENUM  "0","1";
BA_DEF_  "BusType" STRING ;
BA_DEF_  "BaudrateCANFD" INT 0 5000000;
BA_DEF_REL_ BU_SG_REL_  "GenSigTimeoutTime" INT 0 65535;
BA_DEF_REL_ BU_SG_REL_  "GenSigFirstTimeoutTime" INT 0 65535;
BA_DEF_DEF_  "GenMsgStartDelayTime" 0;
BA_DEF_DEF_  "GenMsgDelayTime" 0;
BA_DEF_DEF_  "GenMsgCycleTime" 0;
BA_DEF_DEF_  "GenMsgSendType" "Cyclic";
BA_DEF_DEF_  "GenSigStartValue" 0;
BA_DEF_DEF_  "GenSigCycleTimeActive" 0;
BA_DEF_DEF_  "GenSigCycleTime" 0;
BA_DEF_DEF_  "GenSigSendType" "Cyclic";
BA_DEF_DEF_  "Baudrate" 500000;
BA_DEF_DEF_  "NmType" "";
BA_DEF_DEF_  "Manufacturer" "VOLVO_AB";
BA_DEF_DEF_  "VersionYear" 0;
BA_DEF_DEF_  "VersionNumber" 0;
BA_DEF_DEF_  "VersionMonth" 1;
BA_DEF_DEF_  "VersionDay" 1;
BA_DEF_DEF_  "VFrameFormat" "ExtendedCAN";
BA_DEF_DEF_  "TpOwnSystemEcuNumber" 0;
BA_DEF_DEF_  "SigType" "Default";
BA_DEF_DEF_  "SeToolVersion_SIGNAL" "";
BA_DEF_DEF_  "SeToolUniqueID_SIGNAL" "";
BA_DEF_DEF_  "SeToolName_SIGNAL" "";
BA_DEF_DEF_  "SeToolItemID_SIGNAL" "";
BA_DEF_DEF_  "SeToolAncestorID_SIGNAL" "";
BA_DEF_DEF_  "ProtocolType" "";
BA_DEF_DEF_  "NmStationAddress" 254;
BA_DEF_DEF_  "NmAsrWaitBusSleepTime" 750;
BA_DEF_DEF_  "NmAsrTimeoutTime" 5000;
BA_DEF_DEF_  "NmAsrRepeatMessageTime" 300;
BA_DEF_DEF_  "NmAsrNodeIdentifier" 0;
BA_DEF_DEF_  "NmAsrNode" "Yes";
BA_DEF_DEF_  "NmAsrMessageCount" 256;
BA_DEF_DEF_  "NmAsrCanMsgCycleTime" 200;
BA_DEF_DEF_  "NmAsrBaseAddress" 486506496;
BA_DEF_DEF_  "NeedsUpdateBit" "No";
BA_DEF_DEF_  "GenSigILSupport" "Yes";
BA_DEF_DEF_  "GenMsgILSupport" "Yes";
BA_DEF_DEF_  "E2EProfile" "none";
BA_DEF_DEF_  "E2EP05WindowSize" 5;
BA_DEF_DEF_  "E2EP05ProfileName" "PROFILE_05";
BA_DEF_DEF_  "E2EP05MinOkStateValid" 1;
BA_DEF_DEF_  "E2EP05MinOkStateInvalid" 3;
BA_DEF_DEF_  "E2EP05MinOkStateInit" 1;
BA_DEF_DEF_  "E2EP05MaxErrorStateValid" 3;
BA_DEF_DEF_  "E2EP05MaxErrorStateInvalid" 1;
BA_DEF_DEF_  "E2EP05MaxErrorStateInit" 2;
BA_DEF_DEF_  "E2EP05MaxDeltaCounter" 1;
BA_DEF_DEF_  "E2EP01WindowSize" 5;
BA_DEF_DEF_  "E2EP01SyncCounterInit" 1;
BA_DEF_DEF_  "E2EP01ProfileName" "PROFILE_01";
BA_DEF_DEF_  "E2EP01MinOkStateValid" 1;
BA_DEF_DEF_  "E2EP01MinOkStateInvalid" 3;
BA_DEF_DEF_  "E2EP01MinOkStateInit" 1;
BA_DEF_DEF_  "E2EP01MaxNoNewOrRepeatedData" 5;
BA_DEF_DEF_  "E2EP01MaxErrorStateValid" 3;
BA_DEF_DEF_  "E2EP01MaxErrorStateInvalid" 1;
BA_DEF_DEF_  "E2EP01MaxErrorStateInit" 2;
BA_DEF_DEF_  "E2EP01MaxDeltaCounter" 1;
BA_DEF_DEF_  "E2EP01DataIdMode" "all16Bit";
BA_DEF_DEF_  "E2EP01CounterOffset" 8;
BA_DEF_DEF_  "E2EDataLength" 0;
BA_DEF_DEF_  "E2EDataId" 0;
BA_DEF_DEF_  "DiagUUDTResponse" "No";
BA_DEF_DEF_  "DiagState" "No";
BA_DEF_DEF_  "DiagResponse" "No";
BA_DEF_DEF_  "DiagRequest" "No";
BA_DEF_DEF_  "DiagConnection" 0;
BA_DEF_DEF_  "DBName" "";
BA_DEF_DEF_  "CanTpFcFrameId" 2147483647;
BA_DEF_DEF_  "CanTpBs" 255;
BA_DEF_DEF_  "CANFD_BRS" "0";
BA_DEF_DEF_  "BusType" "";
BA_DEF_DEF_  "BaudrateCANFD" 0;
BA_DEF_DEF_REL_ "GenSigTimeoutTime" 0;
BA_DEF_DEF_REL_ "GenSigFirstTimeoutTime" 0;
BA_ "BusType" "CAN FD";
BA_ "BaudrateCANFD" 2000000;
BA_ "ProtocolType" "CAN";
BA_ "VersionDay" 12;
BA_ "VersionMonth" 5;
BA_ "VersionNumber" 1;
BA_ "VersionYear" 22;
BA_ "DBName" "VicinityNet2";
BA_ "TpOwnSystemEcuNumber" BU_ FLC2 81;
BA_ "NmAsrNode" BU_ FLC2 0;
BA_ "NmAsrNodeIdentifier" BU_ FLC2 81;
BA_ "TpOwnSystemEcuNumber" BU_ DACU 80;
BA_ "NmAsrNode" BU_ DACU 0;
BA_ "NmAsrNodeIdentifier" BU_ DACU 80;
BA_ "DiagConnection" BO_ 2671902706 62033;
BA_ "DiagState" BO_ 2671902706 1;
BA_ "GenMsgILSupport" BO_ 2671902706 0;
BA_ "GenMsgSendType" BO_ 2671902706 8;
BA_ "DiagConnection" BO_ 2671833681 62033;
BA_ "DiagResponse" BO_ 2671833681 1;
BA_ "GenMsgILSupport" BO_ 2671833681 0;
BA_ "GenMsgSendType" BO_ 2671833681 8;
BA_ "DiagConnection" BO_ 2671792626 62033;
BA_ "DiagRequest" BO_ 2671792626 1;
BA_ "GenMsgILSupport" BO_ 2671792626 0;
BA_ "GenMsgSendType" BO_ 2671792626 8;
BA_ "DiagConnection" BO_ 2671902708 62545;
BA_ "DiagState" BO_ 2671902708 1;
BA_ "GenMsgILSupport" BO_ 2671902708 0;
BA_ "GenMsgSendType" BO_ 2671902708 8;
BA_ "CANFD_BRS" BO_ 850 1;
BA_ "GenMsgCycleTime" BO_ 850 100;
BA_ "VFrameFormat" BO_ 850 14;
BA_ "CANFD_BRS" BO_ 872 1;
BA_ "GenMsgSendType" BO_ 872 8;
BA_ "VFrameFormat" BO_ 872 14;
BA_ "CANFD_BRS" BO_ 871 1;
BA_ "GenMsgSendType" BO_ 871 8;
BA_ "VFrameFormat" BO_ 871 14;
BA_ "CANFD_BRS" BO_ 870 1;
BA_ "GenMsgSendType" BO_ 870 8;
BA_ "VFrameFormat" BO_ 870 14;
BA_ "CANFD_BRS" BO_ 869 1;
BA_ "GenMsgSendType" BO_ 869 8;
BA_ "VFrameFormat" BO_ 869 14;
BA_ "CANFD_BRS" BO_ 868 1;
BA_ "GenMsgSendType" BO_ 868 8;
BA_ "VFrameFormat" BO_ 868 14;
BA_ "CANFD_BRS" BO_ 867 1;
BA_ "GenMsgSendType" BO_ 867 8;
BA_ "VFrameFormat" BO_ 867 14;
BA_ "CANFD_BRS" BO_ 866 1;
BA_ "GenMsgSendType" BO_ 866 8;
BA_ "VFrameFormat" BO_ 866 14;
BA_ "CANFD_BRS" BO_ 865 1;
BA_ "GenMsgSendType" BO_ 865 8;
BA_ "VFrameFormat" BO_ 865 14;
BA_ "CANFD_BRS" BO_ 849 1;
BA_ "GenMsgSendType" BO_ 849 8;
BA_ "VFrameFormat" BO_ 849 14;
BA_ "CANFD_BRS" BO_ 848 1;
BA_ "GenMsgSendType" BO_ 848 8;
BA_ "VFrameFormat" BO_ 848 14;
BA_ "CANFD_BRS" BO_ 841 1;
BA_ "GenMsgSendType" BO_ 841 8;
BA_ "VFrameFormat" BO_ 841 14;
BA_ "CANFD_BRS" BO_ 840 1;
BA_ "GenMsgSendType" BO_ 840 8;
BA_ "VFrameFormat" BO_ 840 14;
BA_ "CANFD_BRS" BO_ 858 1;
BA_ "GenMsgSendType" BO_ 858 8;
BA_ "VFrameFormat" BO_ 858 14;
BA_ "GenSigSendType" SG_ 2671902706 FuncDiagDataTester 7;
BA_ "GenSigSendType" SG_ 2671833681 PhysDiagRespSig_F2_51 7;
BA_ "GenSigSendType" SG_ 2671792626 PhysDiagReqSig_51_F2 7;
BA_ "GenSigSendType" SG_ 2671902708 FuncDiagDataIntTesterTGW2 7;
BA_ "GenSigSendType" SG_ 850 VisionProperties_LaneChange 1;
BA_ "GenSigStartValue" SG_ 850 VisionProperties_LaneChange 3;
BA_ "GenSigSendType" SG_ 850 VisionProperties_AmbientLight 1;
BA_ "GenSigStartValue" SG_ 850 VisionProperties_AmbientLight 65535;
BA_ "GenSigSendType" SG_ 850 VisionProperties_StreetLight 1;
BA_ "GenSigStartValue" SG_ 850 VisionProperties_StreetLight 7;
BA_ "GenSigCycleTime" SG_ 850 FLCVideoOutStatus 100;
BA_ "GenSigCycleTimeActive" SG_ 850 FLCVideoOutStatus 100;
BA_ "GenSigStartValue" SG_ 850 FLCVideoOutStatus 15;
BA_ "GenSigSendType" SG_ 850 VisionProperties_NightDay 1;
BA_ "GenSigStartValue" SG_ 850 VisionProperties_NightDay 127;
BA_ "GenSigSendType" SG_ 850 VisionProperties_BlockConf 1;
BA_ "GenSigStartValue" SG_ 850 VisionProperties_BlockConf 127;
BA_ "GenSigSendType" SG_ 850 VisionProperties_Weather 1;
BA_ "GenSigStartValue" SG_ 850 VisionProperties_Weather 15;
BA_ "GenSigSendType" SG_ 872 TrafficSign11_SupplSignValue01 1;
BA_ "GenSigStartValue" SG_ 872 TrafficSign11_SupplSignValue01 255;
BA_ "GenSigSendType" SG_ 872 TrafficSign11_SupplSignType02 1;
BA_ "GenSigStartValue" SG_ 872 TrafficSign11_SupplSignType02 127;
BA_ "GenSigSendType" SG_ 872 TrafficSign11_TrackStatus 1;
BA_ "GenSigStartValue" SG_ 872 TrafficSign11_TrackStatus 7;
BA_ "GenSigSendType" SG_ 872 TrafficSign11_SupplSignValue02 1;
BA_ "GenSigStartValue" SG_ 872 TrafficSign11_SupplSignValue02 255;
BA_ "GenSigSendType" SG_ 872 TrafficSign11_RestDist 1;
BA_ "GenSigStartValue" SG_ 872 TrafficSign11_RestDist 32767;
BA_ "GenSigSendType" SG_ 872 TrafficSign11_MainSignValue 1;
BA_ "GenSigStartValue" SG_ 872 TrafficSign11_MainSignValue 255;
BA_ "GenSigSendType" SG_ 872 TrafficSign11_SupplSignType01 1;
BA_ "GenSigStartValue" SG_ 872 TrafficSign11_SupplSignType01 127;
BA_ "GenSigSendType" SG_ 872 TrafficSign11_RestHeight 1;
BA_ "GenSigStartValue" SG_ 872 TrafficSign11_RestHeight 127;
BA_ "GenSigSendType" SG_ 872 TrafficSign11_SupplSign02Conf 1;
BA_ "GenSigStartValue" SG_ 872 TrafficSign11_SupplSign02Conf 127;
BA_ "GenSigSendType" SG_ 872 TrafficSign11_MainSignConfidence 1;
BA_ "GenSigStartValue" SG_ 872 TrafficSign11_MainSignConfidence 127;
BA_ "GenSigSendType" SG_ 872 TrafficSign11_RestSection 1;
BA_ "GenSigStartValue" SG_ 872 TrafficSign11_RestSection 131071;
BA_ "GenSigSendType" SG_ 872 TrafficSign11_RestTime1 1;
BA_ "GenSigStartValue" SG_ 872 TrafficSign11_RestTime1 2047;
BA_ "GenSigSendType" SG_ 872 TrafficSign11_TimeStamp 1;
BA_ "GenSigStartValue" SG_ 872 TrafficSign11_TimeStamp 65535;
BA_ "GenSigSendType" SG_ 872 TrafficSign11_RestWeight 1;
BA_ "GenSigStartValue" SG_ 872 TrafficSign11_RestWeight 1023;
BA_ "GenSigSendType" SG_ 872 TrafficSign11_RestWidth 1;
BA_ "GenSigStartValue" SG_ 872 TrafficSign11_RestWidth 127;
BA_ "GenSigSendType" SG_ 872 TrafficSign11_Height 1;
BA_ "GenSigStartValue" SG_ 872 TrafficSign11_Height 31;
BA_ "GenSigSendType" SG_ 872 TrafficSign11_MainSignType 1;
BA_ "GenSigStartValue" SG_ 872 TrafficSign11_MainSignType 127;
BA_ "GenSigSendType" SG_ 872 TrafficSign11_ID 1;
BA_ "GenSigStartValue" SG_ 872 TrafficSign11_ID 255;
BA_ "GenSigSendType" SG_ 872 TrafficSign11_RestTime3 1;
BA_ "GenSigStartValue" SG_ 872 TrafficSign11_RestTime3 2047;
BA_ "GenSigSendType" SG_ 872 TrafficSign11_SupplSignValue00 1;
BA_ "GenSigStartValue" SG_ 872 TrafficSign11_SupplSignValue00 255;
BA_ "GenSigSendType" SG_ 872 TrafficSign11_RestDay 1;
BA_ "GenSigStartValue" SG_ 872 TrafficSign11_RestDay 127;
BA_ "GenSigSendType" SG_ 872 TrafficSign11_LongDist 1;
BA_ "GenSigStartValue" SG_ 872 TrafficSign11_LongDist 255;
BA_ "GenSigSendType" SG_ 872 TrafficSign11_RestTime2 1;
BA_ "GenSigStartValue" SG_ 872 TrafficSign11_RestTime2 2047;
BA_ "GenSigSendType" SG_ 872 TrafficSign11_SupplSignType00 1;
BA_ "GenSigStartValue" SG_ 872 TrafficSign11_SupplSignType00 127;
BA_ "GenSigSendType" SG_ 872 TrafficSign11_SupplSign00Conf 1;
BA_ "GenSigStartValue" SG_ 872 TrafficSign11_SupplSign00Conf 127;
BA_ "GenSigSendType" SG_ 872 TrafficSign11_SupplSign01Conf 1;
BA_ "GenSigStartValue" SG_ 872 TrafficSign11_SupplSign01Conf 127;
BA_ "GenSigSendType" SG_ 872 TrafficSign11_LatDist 1;
BA_ "GenSigStartValue" SG_ 872 TrafficSign11_LatDist 127;
BA_ "GenSigSendType" SG_ 872 TrafficSign11_RestTime0 1;
BA_ "GenSigStartValue" SG_ 872 TrafficSign11_RestTime0 2047;
BA_ "GenSigSendType" SG_ 872 TrafficSign11_SignStability 1;
BA_ "GenSigSendType" SG_ 871 TrafficSign10_SupplSignType02 1;
BA_ "GenSigStartValue" SG_ 871 TrafficSign10_SupplSignType02 127;
BA_ "GenSigSendType" SG_ 871 TrafficSign10_SignStability 1;
BA_ "GenSigSendType" SG_ 871 TrafficSign10_ID 1;
BA_ "GenSigStartValue" SG_ 871 TrafficSign10_ID 255;
BA_ "GenSigSendType" SG_ 871 TrafficSign10_SupplSignValue00 1;
BA_ "GenSigStartValue" SG_ 871 TrafficSign10_SupplSignValue00 255;
BA_ "GenSigSendType" SG_ 871 TrafficSign10_RestTime2 1;
BA_ "GenSigStartValue" SG_ 871 TrafficSign10_RestTime2 2047;
BA_ "GenSigSendType" SG_ 871 TrafficSign10_RestSection 1;
BA_ "GenSigStartValue" SG_ 871 TrafficSign10_RestSection 131071;
BA_ "GenSigSendType" SG_ 871 TrafficSign10_SupplSign00Conf 1;
BA_ "GenSigStartValue" SG_ 871 TrafficSign10_SupplSign00Conf 127;
BA_ "GenSigSendType" SG_ 871 TrafficSign10_MainSignType 1;
BA_ "GenSigStartValue" SG_ 871 TrafficSign10_MainSignType 127;
BA_ "GenSigSendType" SG_ 871 TrafficSign10_RestTime3 1;
BA_ "GenSigStartValue" SG_ 871 TrafficSign10_RestTime3 2047;
BA_ "GenSigSendType" SG_ 871 TrafficSign10_RestHeight 1;
BA_ "GenSigStartValue" SG_ 871 TrafficSign10_RestHeight 127;
BA_ "GenSigSendType" SG_ 871 TrafficSign10_RestTime1 1;
BA_ "GenSigStartValue" SG_ 871 TrafficSign10_RestTime1 2047;
BA_ "GenSigSendType" SG_ 871 TrafficSign10_SupplSignType01 1;
BA_ "GenSigStartValue" SG_ 871 TrafficSign10_SupplSignType01 127;
BA_ "GenSigSendType" SG_ 871 TrafficSign10_RestWidth 1;
BA_ "GenSigStartValue" SG_ 871 TrafficSign10_RestWidth 127;
BA_ "GenSigSendType" SG_ 871 TrafficSign10_SupplSign02Conf 1;
BA_ "GenSigStartValue" SG_ 871 TrafficSign10_SupplSign02Conf 127;
BA_ "GenSigSendType" SG_ 871 TrafficSign10_SupplSignValue01 1;
BA_ "GenSigStartValue" SG_ 871 TrafficSign10_SupplSignValue01 255;
BA_ "GenSigSendType" SG_ 871 TrafficSign10_TimeStamp 1;
BA_ "GenSigStartValue" SG_ 871 TrafficSign10_TimeStamp 65535;
BA_ "GenSigSendType" SG_ 871 TrafficSign10_LongDist 1;
BA_ "GenSigStartValue" SG_ 871 TrafficSign10_LongDist 255;
BA_ "GenSigSendType" SG_ 871 TrafficSign10_SupplSignValue02 1;
BA_ "GenSigStartValue" SG_ 871 TrafficSign10_SupplSignValue02 255;
BA_ "GenSigSendType" SG_ 871 TrafficSign10_SupplSign01Conf 1;
BA_ "GenSigStartValue" SG_ 871 TrafficSign10_SupplSign01Conf 127;
BA_ "GenSigSendType" SG_ 871 TrafficSign10_SupplSignType00 1;
BA_ "GenSigStartValue" SG_ 871 TrafficSign10_SupplSignType00 127;
BA_ "GenSigSendType" SG_ 871 TrafficSign10_Height 1;
BA_ "GenSigStartValue" SG_ 871 TrafficSign10_Height 31;
BA_ "GenSigSendType" SG_ 871 TrafficSign10_TrackStatus 1;
BA_ "GenSigStartValue" SG_ 871 TrafficSign10_TrackStatus 7;
BA_ "GenSigSendType" SG_ 871 TrafficSign10_RestWeight 1;
BA_ "GenSigStartValue" SG_ 871 TrafficSign10_RestWeight 1023;
BA_ "GenSigSendType" SG_ 871 TrafficSign10_RestDay 1;
BA_ "GenSigStartValue" SG_ 871 TrafficSign10_RestDay 127;
BA_ "GenSigSendType" SG_ 871 TrafficSign10_MainSignConfidence 1;
BA_ "GenSigStartValue" SG_ 871 TrafficSign10_MainSignConfidence 127;
BA_ "GenSigSendType" SG_ 871 TrafficSign10_RestDist 1;
BA_ "GenSigStartValue" SG_ 871 TrafficSign10_RestDist 32767;
BA_ "GenSigSendType" SG_ 871 TrafficSign10_RestTime0 1;
BA_ "GenSigStartValue" SG_ 871 TrafficSign10_RestTime0 2047;
BA_ "GenSigSendType" SG_ 871 TrafficSign10_MainSignValue 1;
BA_ "GenSigStartValue" SG_ 871 TrafficSign10_MainSignValue 255;
BA_ "GenSigSendType" SG_ 871 TrafficSign10_LatDist 1;
BA_ "GenSigStartValue" SG_ 871 TrafficSign10_LatDist 127;
BA_ "GenSigSendType" SG_ 870 TrafficSign09_MainSignValue 1;
BA_ "GenSigStartValue" SG_ 870 TrafficSign09_MainSignValue 255;
BA_ "GenSigSendType" SG_ 870 TrafficSign09_RestTime0 1;
BA_ "GenSigStartValue" SG_ 870 TrafficSign09_RestTime0 2047;
BA_ "GenSigSendType" SG_ 870 TrafficSign09_LongDist 1;
BA_ "GenSigStartValue" SG_ 870 TrafficSign09_LongDist 255;
BA_ "GenSigSendType" SG_ 870 TrafficSign09_SupplSign00Conf 1;
BA_ "GenSigStartValue" SG_ 870 TrafficSign09_SupplSign00Conf 127;
BA_ "GenSigSendType" SG_ 870 TrafficSign09_MainSignConfidence 1;
BA_ "GenSigStartValue" SG_ 870 TrafficSign09_MainSignConfidence 127;
BA_ "GenSigSendType" SG_ 870 TrafficSign09_Height 1;
BA_ "GenSigStartValue" SG_ 870 TrafficSign09_Height 31;
BA_ "GenSigSendType" SG_ 870 TrafficSign09_RestTime2 1;
BA_ "GenSigStartValue" SG_ 870 TrafficSign09_RestTime2 2047;
BA_ "GenSigSendType" SG_ 870 TrafficSign09_MainSignType 1;
BA_ "GenSigStartValue" SG_ 870 TrafficSign09_MainSignType 127;
BA_ "GenSigSendType" SG_ 870 TrafficSign09_SupplSignType02 1;
BA_ "GenSigStartValue" SG_ 870 TrafficSign09_SupplSignType02 127;
BA_ "GenSigSendType" SG_ 870 TrafficSign09_SupplSign01Conf 1;
BA_ "GenSigStartValue" SG_ 870 TrafficSign09_SupplSign01Conf 127;
BA_ "GenSigSendType" SG_ 870 TrafficSign09_RestSection 1;
BA_ "GenSigStartValue" SG_ 870 TrafficSign09_RestSection 131071;
BA_ "GenSigSendType" SG_ 870 TrafficSign09_SupplSign02Conf 1;
BA_ "GenSigStartValue" SG_ 870 TrafficSign09_SupplSign02Conf 127;
BA_ "GenSigSendType" SG_ 870 TrafficSign09_SupplSignValue01 1;
BA_ "GenSigStartValue" SG_ 870 TrafficSign09_SupplSignValue01 255;
BA_ "GenSigSendType" SG_ 870 TrafficSign09_RestWeight 1;
BA_ "GenSigStartValue" SG_ 870 TrafficSign09_RestWeight 1023;
BA_ "GenSigSendType" SG_ 870 TrafficSign09_LatDist 1;
BA_ "GenSigStartValue" SG_ 870 TrafficSign09_LatDist 127;
BA_ "GenSigSendType" SG_ 870 TrafficSign09_SignStability 1;
BA_ "GenSigSendType" SG_ 870 TrafficSign09_RestTime1 1;
BA_ "GenSigStartValue" SG_ 870 TrafficSign09_RestTime1 2047;
BA_ "GenSigSendType" SG_ 870 TrafficSign09_SupplSignType00 1;
BA_ "GenSigStartValue" SG_ 870 TrafficSign09_SupplSignType00 127;
BA_ "GenSigSendType" SG_ 870 TrafficSign09_RestHeight 1;
BA_ "GenSigStartValue" SG_ 870 TrafficSign09_RestHeight 127;
BA_ "GenSigSendType" SG_ 870 TrafficSign09_RestDay 1;
BA_ "GenSigStartValue" SG_ 870 TrafficSign09_RestDay 127;
BA_ "GenSigSendType" SG_ 870 TrafficSign09_RestDist 1;
BA_ "GenSigStartValue" SG_ 870 TrafficSign09_RestDist 32767;
BA_ "GenSigSendType" SG_ 870 TrafficSign09_SupplSignValue00 1;
BA_ "GenSigStartValue" SG_ 870 TrafficSign09_SupplSignValue00 255;
BA_ "GenSigSendType" SG_ 870 TrafficSign09_TrackStatus 1;
BA_ "GenSigStartValue" SG_ 870 TrafficSign09_TrackStatus 7;
BA_ "GenSigSendType" SG_ 870 TrafficSign09_RestTime3 1;
BA_ "GenSigStartValue" SG_ 870 TrafficSign09_RestTime3 2047;
BA_ "GenSigSendType" SG_ 870 TrafficSign09_SupplSignType01 1;
BA_ "GenSigStartValue" SG_ 870 TrafficSign09_SupplSignType01 127;
BA_ "GenSigSendType" SG_ 870 TrafficSign09_ID 1;
BA_ "GenSigStartValue" SG_ 870 TrafficSign09_ID 255;
BA_ "GenSigSendType" SG_ 870 TrafficSign09_RestWidth 1;
BA_ "GenSigStartValue" SG_ 870 TrafficSign09_RestWidth 127;
BA_ "GenSigSendType" SG_ 870 TrafficSign09_SupplSignValue02 1;
BA_ "GenSigStartValue" SG_ 870 TrafficSign09_SupplSignValue02 255;
BA_ "GenSigSendType" SG_ 870 TrafficSign09_TimeStamp 1;
BA_ "GenSigStartValue" SG_ 870 TrafficSign09_TimeStamp 65535;
BA_ "GenSigSendType" SG_ 869 TrafficSign08_SupplSign00Conf 1;
BA_ "GenSigStartValue" SG_ 869 TrafficSign08_SupplSign00Conf 127;
BA_ "GenSigSendType" SG_ 869 TrafficSign08_SignStability 1;
BA_ "GenSigSendType" SG_ 869 TrafficSign08_MainSignType 1;
BA_ "GenSigStartValue" SG_ 869 TrafficSign08_MainSignType 127;
BA_ "GenSigSendType" SG_ 869 TrafficSign08_SupplSign02Conf 1;
BA_ "GenSigStartValue" SG_ 869 TrafficSign08_SupplSign02Conf 127;
BA_ "GenSigSendType" SG_ 869 TrafficSign08_RestHeight 1;
BA_ "GenSigStartValue" SG_ 869 TrafficSign08_RestHeight 127;
BA_ "GenSigSendType" SG_ 869 TrafficSign08_LatDist 1;
BA_ "GenSigStartValue" SG_ 869 TrafficSign08_LatDist 127;
BA_ "GenSigSendType" SG_ 869 TrafficSign08_SupplSignType02 1;
BA_ "GenSigStartValue" SG_ 869 TrafficSign08_SupplSignType02 127;
BA_ "GenSigSendType" SG_ 869 TrafficSign08_SupplSignType01 1;
BA_ "GenSigStartValue" SG_ 869 TrafficSign08_SupplSignType01 127;
BA_ "GenSigSendType" SG_ 869 TrafficSign08_SupplSign01Conf 1;
BA_ "GenSigStartValue" SG_ 869 TrafficSign08_SupplSign01Conf 127;
BA_ "GenSigSendType" SG_ 869 TrafficSign08_MainSignConfidence 1;
BA_ "GenSigStartValue" SG_ 869 TrafficSign08_MainSignConfidence 127;
BA_ "GenSigSendType" SG_ 869 TrafficSign08_RestSection 1;
BA_ "GenSigStartValue" SG_ 869 TrafficSign08_RestSection 131071;
BA_ "GenSigSendType" SG_ 869 TrafficSign08_RestTime3 1;
BA_ "GenSigStartValue" SG_ 869 TrafficSign08_RestTime3 2047;
BA_ "GenSigSendType" SG_ 869 TrafficSign08_TimeStamp 1;
BA_ "GenSigStartValue" SG_ 869 TrafficSign08_TimeStamp 65535;
BA_ "GenSigSendType" SG_ 869 TrafficSign08_RestDist 1;
BA_ "GenSigStartValue" SG_ 869 TrafficSign08_RestDist 32767;
BA_ "GenSigSendType" SG_ 869 TrafficSign08_SupplSignType00 1;
BA_ "GenSigStartValue" SG_ 869 TrafficSign08_SupplSignType00 127;
BA_ "GenSigSendType" SG_ 869 TrafficSign08_RestTime2 1;
BA_ "GenSigStartValue" SG_ 869 TrafficSign08_RestTime2 2047;
BA_ "GenSigSendType" SG_ 869 TrafficSign08_SupplSignValue02 1;
BA_ "GenSigStartValue" SG_ 869 TrafficSign08_SupplSignValue02 255;
BA_ "GenSigSendType" SG_ 869 TrafficSign08_TrackStatus 1;
BA_ "GenSigStartValue" SG_ 869 TrafficSign08_TrackStatus 7;
BA_ "GenSigSendType" SG_ 869 TrafficSign08_RestWeight 1;
BA_ "GenSigStartValue" SG_ 869 TrafficSign08_RestWeight 1023;
BA_ "GenSigSendType" SG_ 869 TrafficSign08_SupplSignValue01 1;
BA_ "GenSigStartValue" SG_ 869 TrafficSign08_SupplSignValue01 255;
BA_ "GenSigSendType" SG_ 869 TrafficSign08_RestTime0 1;
BA_ "GenSigStartValue" SG_ 869 TrafficSign08_RestTime0 2047;
BA_ "GenSigSendType" SG_ 869 TrafficSign08_LongDist 1;
BA_ "GenSigStartValue" SG_ 869 TrafficSign08_LongDist 255;
BA_ "GenSigSendType" SG_ 869 TrafficSign08_MainSignValue 1;
BA_ "GenSigStartValue" SG_ 869 TrafficSign08_MainSignValue 255;
BA_ "GenSigSendType" SG_ 869 TrafficSign08_RestWidth 1;
BA_ "GenSigStartValue" SG_ 869 TrafficSign08_RestWidth 127;
BA_ "GenSigSendType" SG_ 869 TrafficSign08_RestDay 1;
BA_ "GenSigStartValue" SG_ 869 TrafficSign08_RestDay 127;
BA_ "GenSigSendType" SG_ 869 TrafficSign08_ID 1;
BA_ "GenSigStartValue" SG_ 869 TrafficSign08_ID 255;
BA_ "GenSigSendType" SG_ 869 TrafficSign08_Height 1;
BA_ "GenSigStartValue" SG_ 869 TrafficSign08_Height 31;
BA_ "GenSigSendType" SG_ 869 TrafficSign08_SupplSignValue00 1;
BA_ "GenSigStartValue" SG_ 869 TrafficSign08_SupplSignValue00 255;
BA_ "GenSigSendType" SG_ 869 TrafficSign08_RestTime1 1;
BA_ "GenSigStartValue" SG_ 869 TrafficSign08_RestTime1 2047;
BA_ "GenSigSendType" SG_ 868 TrafficSign07_MainSignConfidence 1;
BA_ "GenSigStartValue" SG_ 868 TrafficSign07_MainSignConfidence 127;
BA_ "GenSigSendType" SG_ 868 TrafficSign07_SupplSign00Conf 1;
BA_ "GenSigStartValue" SG_ 868 TrafficSign07_SupplSign00Conf 127;
BA_ "GenSigSendType" SG_ 868 TrafficSign07_SupplSign01Conf 1;
BA_ "GenSigStartValue" SG_ 868 TrafficSign07_SupplSign01Conf 127;
BA_ "GenSigSendType" SG_ 868 TrafficSign07_SupplSignValue00 1;
BA_ "GenSigStartValue" SG_ 868 TrafficSign07_SupplSignValue00 255;
BA_ "GenSigSendType" SG_ 868 TrafficSign07_RestTime3 1;
BA_ "GenSigStartValue" SG_ 868 TrafficSign07_RestTime3 2047;
BA_ "GenSigSendType" SG_ 868 TrafficSign07_SupplSign02Conf 1;
BA_ "GenSigStartValue" SG_ 868 TrafficSign07_SupplSign02Conf 127;
BA_ "GenSigSendType" SG_ 868 TrafficSign07_ID 1;
BA_ "GenSigStartValue" SG_ 868 TrafficSign07_ID 255;
BA_ "GenSigSendType" SG_ 868 TrafficSign07_SupplSignType01 1;
BA_ "GenSigStartValue" SG_ 868 TrafficSign07_SupplSignType01 127;
BA_ "GenSigSendType" SG_ 868 TrafficSign07_TrackStatus 1;
BA_ "GenSigStartValue" SG_ 868 TrafficSign07_TrackStatus 7;
BA_ "GenSigSendType" SG_ 868 TrafficSign07_RestSection 1;
BA_ "GenSigStartValue" SG_ 868 TrafficSign07_RestSection 131071;
BA_ "GenSigSendType" SG_ 868 TrafficSign07_SupplSignValue02 1;
BA_ "GenSigStartValue" SG_ 868 TrafficSign07_SupplSignValue02 255;
BA_ "GenSigSendType" SG_ 868 TrafficSign07_SupplSignType00 1;
BA_ "GenSigStartValue" SG_ 868 TrafficSign07_SupplSignType00 127;
BA_ "GenSigSendType" SG_ 868 TrafficSign07_RestTime2 1;
BA_ "GenSigStartValue" SG_ 868 TrafficSign07_RestTime2 2047;
BA_ "GenSigSendType" SG_ 868 TrafficSign07_Height 1;
BA_ "GenSigStartValue" SG_ 868 TrafficSign07_Height 31;
BA_ "GenSigSendType" SG_ 868 TrafficSign07_LatDist 1;
BA_ "GenSigStartValue" SG_ 868 TrafficSign07_LatDist 127;
BA_ "GenSigSendType" SG_ 868 TrafficSign07_SupplSignType02 1;
BA_ "GenSigStartValue" SG_ 868 TrafficSign07_SupplSignType02 127;
BA_ "GenSigSendType" SG_ 868 TrafficSign07_SignStability 1;
BA_ "GenSigSendType" SG_ 868 TrafficSign07_RestDist 1;
BA_ "GenSigStartValue" SG_ 868 TrafficSign07_RestDist 32767;
BA_ "GenSigSendType" SG_ 868 TrafficSign07_RestDay 1;
BA_ "GenSigStartValue" SG_ 868 TrafficSign07_RestDay 127;
BA_ "GenSigSendType" SG_ 868 TrafficSign07_RestWidth 1;
BA_ "GenSigStartValue" SG_ 868 TrafficSign07_RestWidth 127;
BA_ "GenSigSendType" SG_ 868 TrafficSign07_TimeStamp 1;
BA_ "GenSigStartValue" SG_ 868 TrafficSign07_TimeStamp 65535;
BA_ "GenSigSendType" SG_ 868 TrafficSign07_RestTime1 1;
BA_ "GenSigStartValue" SG_ 868 TrafficSign07_RestTime1 2047;
BA_ "GenSigSendType" SG_ 868 TrafficSign07_RestTime0 1;
BA_ "GenSigStartValue" SG_ 868 TrafficSign07_RestTime0 2047;
BA_ "GenSigSendType" SG_ 868 TrafficSign07_SupplSignValue01 1;
BA_ "GenSigStartValue" SG_ 868 TrafficSign07_SupplSignValue01 255;
BA_ "GenSigSendType" SG_ 868 TrafficSign07_LongDist 1;
BA_ "GenSigStartValue" SG_ 868 TrafficSign07_LongDist 255;
BA_ "GenSigSendType" SG_ 868 TrafficSign07_MainSignType 1;
BA_ "GenSigStartValue" SG_ 868 TrafficSign07_MainSignType 127;
BA_ "GenSigSendType" SG_ 868 TrafficSign07_MainSignValue 1;
BA_ "GenSigStartValue" SG_ 868 TrafficSign07_MainSignValue 255;
BA_ "GenSigSendType" SG_ 868 TrafficSign07_RestWeight 1;
BA_ "GenSigStartValue" SG_ 868 TrafficSign07_RestWeight 1023;
BA_ "GenSigSendType" SG_ 868 TrafficSign07_RestHeight 1;
BA_ "GenSigStartValue" SG_ 868 TrafficSign07_RestHeight 127;
BA_ "GenSigSendType" SG_ 867 TrafficSign06_RestWeight 1;
BA_ "GenSigStartValue" SG_ 867 TrafficSign06_RestWeight 1023;
BA_ "GenSigSendType" SG_ 867 TrafficSign06_SupplSign01Conf 1;
BA_ "GenSigStartValue" SG_ 867 TrafficSign06_SupplSign01Conf 127;
BA_ "GenSigSendType" SG_ 867 TrafficSign06_SupplSignValue02 1;
BA_ "GenSigStartValue" SG_ 867 TrafficSign06_SupplSignValue02 255;
BA_ "GenSigSendType" SG_ 867 TrafficSign06_RestTime1 1;
BA_ "GenSigStartValue" SG_ 867 TrafficSign06_RestTime1 2047;
BA_ "GenSigSendType" SG_ 867 TrafficSign06_SupplSignType02 1;
BA_ "GenSigStartValue" SG_ 867 TrafficSign06_SupplSignType02 127;
BA_ "GenSigSendType" SG_ 867 TrafficSign06_SignStability 1;
BA_ "GenSigSendType" SG_ 867 TrafficSign06_SupplSign00Conf 1;
BA_ "GenSigStartValue" SG_ 867 TrafficSign06_SupplSign00Conf 127;
BA_ "GenSigSendType" SG_ 867 TrafficSign06_MainSignValue 1;
BA_ "GenSigStartValue" SG_ 867 TrafficSign06_MainSignValue 255;
BA_ "GenSigSendType" SG_ 867 TrafficSign06_SupplSign02Conf 1;
BA_ "GenSigStartValue" SG_ 867 TrafficSign06_SupplSign02Conf 127;
BA_ "GenSigSendType" SG_ 867 TrafficSign06_SupplSignValue01 1;
BA_ "GenSigStartValue" SG_ 867 TrafficSign06_SupplSignValue01 255;
BA_ "GenSigSendType" SG_ 867 TrafficSign06_RestTime2 1;
BA_ "GenSigStartValue" SG_ 867 TrafficSign06_RestTime2 2047;
BA_ "GenSigSendType" SG_ 867 TrafficSign06_Height 1;
BA_ "GenSigStartValue" SG_ 867 TrafficSign06_Height 31;
BA_ "GenSigSendType" SG_ 867 TrafficSign06_LatDist 1;
BA_ "GenSigStartValue" SG_ 867 TrafficSign06_LatDist 127;
BA_ "GenSigSendType" SG_ 867 TrafficSign06_MainSignType 1;
BA_ "GenSigStartValue" SG_ 867 TrafficSign06_MainSignType 127;
BA_ "GenSigSendType" SG_ 867 TrafficSign06_LongDist 1;
BA_ "GenSigStartValue" SG_ 867 TrafficSign06_LongDist 255;
BA_ "GenSigSendType" SG_ 867 TrafficSign06_TimeStamp 1;
BA_ "GenSigStartValue" SG_ 867 TrafficSign06_TimeStamp 65535;
BA_ "GenSigSendType" SG_ 867 TrafficSign06_RestDist 1;
BA_ "GenSigStartValue" SG_ 867 TrafficSign06_RestDist 32767;
BA_ "GenSigSendType" SG_ 867 TrafficSign06_RestTime0 1;
BA_ "GenSigStartValue" SG_ 867 TrafficSign06_RestTime0 2047;
BA_ "GenSigSendType" SG_ 867 TrafficSign06_SupplSignType01 1;
BA_ "GenSigStartValue" SG_ 867 TrafficSign06_SupplSignType01 127;
BA_ "GenSigSendType" SG_ 867 TrafficSign06_TrackStatus 1;
BA_ "GenSigStartValue" SG_ 867 TrafficSign06_TrackStatus 7;
BA_ "GenSigSendType" SG_ 867 TrafficSign06_MainSignConfidence 1;
BA_ "GenSigStartValue" SG_ 867 TrafficSign06_MainSignConfidence 127;
BA_ "GenSigSendType" SG_ 867 TrafficSign06_RestHeight 1;
BA_ "GenSigStartValue" SG_ 867 TrafficSign06_RestHeight 127;
BA_ "GenSigSendType" SG_ 867 TrafficSign06_RestSection 1;
BA_ "GenSigStartValue" SG_ 867 TrafficSign06_RestSection 131071;
BA_ "GenSigSendType" SG_ 867 TrafficSign06_RestDay 1;
BA_ "GenSigStartValue" SG_ 867 TrafficSign06_RestDay 127;
BA_ "GenSigSendType" SG_ 867 TrafficSign06_SupplSignValue00 1;
BA_ "GenSigStartValue" SG_ 867 TrafficSign06_SupplSignValue00 255;
BA_ "GenSigSendType" SG_ 867 TrafficSign06_ID 1;
BA_ "GenSigStartValue" SG_ 867 TrafficSign06_ID 255;
BA_ "GenSigSendType" SG_ 867 TrafficSign06_RestWidth 1;
BA_ "GenSigStartValue" SG_ 867 TrafficSign06_RestWidth 127;
BA_ "GenSigSendType" SG_ 867 TrafficSign06_RestTime3 1;
BA_ "GenSigStartValue" SG_ 867 TrafficSign06_RestTime3 2047;
BA_ "GenSigSendType" SG_ 867 TrafficSign06_SupplSignType00 1;
BA_ "GenSigStartValue" SG_ 867 TrafficSign06_SupplSignType00 127;
BA_ "GenSigSendType" SG_ 866 TrafficSign05_SupplSignType00 1;
BA_ "GenSigStartValue" SG_ 866 TrafficSign05_SupplSignType00 127;
BA_ "GenSigSendType" SG_ 866 TrafficSign05_ID 1;
BA_ "GenSigStartValue" SG_ 866 TrafficSign05_ID 255;
BA_ "GenSigSendType" SG_ 866 TrafficSign05_SupplSignValue00 1;
BA_ "GenSigStartValue" SG_ 866 TrafficSign05_SupplSignValue00 255;
BA_ "GenSigSendType" SG_ 866 TrafficSign05_MainSignConfidence 1;
BA_ "GenSigStartValue" SG_ 866 TrafficSign05_MainSignConfidence 127;
BA_ "GenSigSendType" SG_ 866 TrafficSign05_RestDay 1;
BA_ "GenSigStartValue" SG_ 866 TrafficSign05_RestDay 127;
BA_ "GenSigSendType" SG_ 866 TrafficSign05_MainSignType 1;
BA_ "GenSigStartValue" SG_ 866 TrafficSign05_MainSignType 127;
BA_ "GenSigSendType" SG_ 866 TrafficSign05_SupplSignType01 1;
BA_ "GenSigStartValue" SG_ 866 TrafficSign05_SupplSignType01 127;
BA_ "GenSigSendType" SG_ 866 TrafficSign05_LongDist 1;
BA_ "GenSigStartValue" SG_ 866 TrafficSign05_LongDist 255;
BA_ "GenSigSendType" SG_ 866 TrafficSign05_RestSection 1;
BA_ "GenSigStartValue" SG_ 866 TrafficSign05_RestSection 131071;
BA_ "GenSigSendType" SG_ 866 TrafficSign05_MainSignValue 1;
BA_ "GenSigStartValue" SG_ 866 TrafficSign05_MainSignValue 255;
BA_ "GenSigSendType" SG_ 866 TrafficSign05_SupplSignValue01 1;
BA_ "GenSigStartValue" SG_ 866 TrafficSign05_SupplSignValue01 255;
BA_ "GenSigSendType" SG_ 866 TrafficSign05_TimeStamp 1;
BA_ "GenSigStartValue" SG_ 866 TrafficSign05_TimeStamp 65535;
BA_ "GenSigSendType" SG_ 866 TrafficSign05_Height 1;
BA_ "GenSigStartValue" SG_ 866 TrafficSign05_Height 31;
BA_ "GenSigSendType" SG_ 866 TrafficSign05_SupplSign02Conf 1;
BA_ "GenSigStartValue" SG_ 866 TrafficSign05_SupplSign02Conf 127;
BA_ "GenSigSendType" SG_ 866 TrafficSign05_SignStability 1;
BA_ "GenSigSendType" SG_ 866 TrafficSign05_SupplSignValue02 1;
BA_ "GenSigStartValue" SG_ 866 TrafficSign05_SupplSignValue02 255;
BA_ "GenSigSendType" SG_ 866 TrafficSign05_TrackStatus 1;
BA_ "GenSigStartValue" SG_ 866 TrafficSign05_TrackStatus 7;
BA_ "GenSigSendType" SG_ 866 TrafficSign05_LatDist 1;
BA_ "GenSigStartValue" SG_ 866 TrafficSign05_LatDist 127;
BA_ "GenSigSendType" SG_ 866 TrafficSign05_RestHeight 1;
BA_ "GenSigStartValue" SG_ 866 TrafficSign05_RestHeight 127;
BA_ "GenSigSendType" SG_ 866 TrafficSign05_RestTime1 1;
BA_ "GenSigStartValue" SG_ 866 TrafficSign05_RestTime1 2047;
BA_ "GenSigSendType" SG_ 866 TrafficSign05_RestWidth 1;
BA_ "GenSigStartValue" SG_ 866 TrafficSign05_RestWidth 127;
BA_ "GenSigSendType" SG_ 866 TrafficSign05_RestTime3 1;
BA_ "GenSigStartValue" SG_ 866 TrafficSign05_RestTime3 2047;
BA_ "GenSigSendType" SG_ 866 TrafficSign05_RestDist 1;
BA_ "GenSigStartValue" SG_ 866 TrafficSign05_RestDist 32767;
BA_ "GenSigSendType" SG_ 866 TrafficSign05_RestTime2 1;
BA_ "GenSigStartValue" SG_ 866 TrafficSign05_RestTime2 2047;
BA_ "GenSigSendType" SG_ 866 TrafficSign05_RestTime0 1;
BA_ "GenSigStartValue" SG_ 866 TrafficSign05_RestTime0 2047;
BA_ "GenSigSendType" SG_ 866 TrafficSign05_SupplSign00Conf 1;
BA_ "GenSigStartValue" SG_ 866 TrafficSign05_SupplSign00Conf 127;
BA_ "GenSigSendType" SG_ 866 TrafficSign05_SupplSignType02 1;
BA_ "GenSigStartValue" SG_ 866 TrafficSign05_SupplSignType02 127;
BA_ "GenSigSendType" SG_ 866 TrafficSign05_SupplSign01Conf 1;
BA_ "GenSigStartValue" SG_ 866 TrafficSign05_SupplSign01Conf 127;
BA_ "GenSigSendType" SG_ 866 TrafficSign05_RestWeight 1;
BA_ "GenSigStartValue" SG_ 866 TrafficSign05_RestWeight 1023;
BA_ "GenSigSendType" SG_ 865 TrafficSign04_TrackStatus 1;
BA_ "GenSigStartValue" SG_ 865 TrafficSign04_TrackStatus 7;
BA_ "GenSigSendType" SG_ 865 TrafficSign04_MainSignType 1;
BA_ "GenSigStartValue" SG_ 865 TrafficSign04_MainSignType 127;
BA_ "GenSigSendType" SG_ 865 TrafficSign04_SupplSignValue00 1;
BA_ "GenSigStartValue" SG_ 865 TrafficSign04_SupplSignValue00 255;
BA_ "GenSigSendType" SG_ 865 TrafficSign04_RestTime1 1;
BA_ "GenSigStartValue" SG_ 865 TrafficSign04_RestTime1 2047;
BA_ "GenSigSendType" SG_ 865 TrafficSign04_SupplSignValue01 1;
BA_ "GenSigStartValue" SG_ 865 TrafficSign04_SupplSignValue01 255;
BA_ "GenSigSendType" SG_ 865 TrafficSign04_RestTime2 1;
BA_ "GenSigStartValue" SG_ 865 TrafficSign04_RestTime2 2047;
BA_ "GenSigSendType" SG_ 865 TrafficSign04_Height 1;
BA_ "GenSigStartValue" SG_ 865 TrafficSign04_Height 31;
BA_ "GenSigSendType" SG_ 865 TrafficSign04_SupplSign00Conf 1;
BA_ "GenSigStartValue" SG_ 865 TrafficSign04_SupplSign00Conf 127;
BA_ "GenSigSendType" SG_ 865 TrafficSign04_SupplSign01Conf 1;
BA_ "GenSigStartValue" SG_ 865 TrafficSign04_SupplSign01Conf 127;
BA_ "GenSigSendType" SG_ 865 TrafficSign04_SupplSign02Conf 1;
BA_ "GenSigStartValue" SG_ 865 TrafficSign04_SupplSign02Conf 127;
BA_ "GenSigSendType" SG_ 865 TrafficSign04_SupplSignType02 1;
BA_ "GenSigStartValue" SG_ 865 TrafficSign04_SupplSignType02 127;
BA_ "GenSigSendType" SG_ 865 TrafficSign04_LongDist 1;
BA_ "GenSigStartValue" SG_ 865 TrafficSign04_LongDist 255;
BA_ "GenSigSendType" SG_ 865 TrafficSign04_RestTime0 1;
BA_ "GenSigStartValue" SG_ 865 TrafficSign04_RestTime0 2047;
BA_ "GenSigSendType" SG_ 865 TrafficSign04_RestWidth 1;
BA_ "GenSigStartValue" SG_ 865 TrafficSign04_RestWidth 127;
BA_ "GenSigSendType" SG_ 865 TrafficSign04_SupplSignType00 1;
BA_ "GenSigStartValue" SG_ 865 TrafficSign04_SupplSignType00 127;
BA_ "GenSigSendType" SG_ 865 TrafficSign04_RestDay 1;
BA_ "GenSigStartValue" SG_ 865 TrafficSign04_RestDay 127;
BA_ "GenSigSendType" SG_ 865 TrafficSign04_SupplSignType01 1;
BA_ "GenSigStartValue" SG_ 865 TrafficSign04_SupplSignType01 127;
BA_ "GenSigSendType" SG_ 865 TrafficSign04_MainSignConfidence 1;
BA_ "GenSigStartValue" SG_ 865 TrafficSign04_MainSignConfidence 127;
BA_ "GenSigSendType" SG_ 865 TrafficSign04_RestHeight 1;
BA_ "GenSigStartValue" SG_ 865 TrafficSign04_RestHeight 127;
BA_ "GenSigSendType" SG_ 865 TrafficSign04_MainSignValue 1;
BA_ "GenSigStartValue" SG_ 865 TrafficSign04_MainSignValue 255;
BA_ "GenSigSendType" SG_ 865 TrafficSign04_RestSection 1;
BA_ "GenSigStartValue" SG_ 865 TrafficSign04_RestSection 131071;
BA_ "GenSigSendType" SG_ 865 TrafficSign04_RestDist 1;
BA_ "GenSigStartValue" SG_ 865 TrafficSign04_RestDist 32767;
BA_ "GenSigSendType" SG_ 865 TrafficSign04_ID 1;
BA_ "GenSigStartValue" SG_ 865 TrafficSign04_ID 255;
BA_ "GenSigSendType" SG_ 865 TrafficSign04_RestTime3 1;
BA_ "GenSigStartValue" SG_ 865 TrafficSign04_RestTime3 2047;
BA_ "GenSigSendType" SG_ 865 TrafficSign04_SignStability 1;
BA_ "GenSigSendType" SG_ 865 TrafficSign04_LatDist 1;
BA_ "GenSigStartValue" SG_ 865 TrafficSign04_LatDist 127;
BA_ "GenSigSendType" SG_ 865 TrafficSign04_TimeStamp 1;
BA_ "GenSigStartValue" SG_ 865 TrafficSign04_TimeStamp 65535;
BA_ "GenSigSendType" SG_ 865 TrafficSign04_SupplSignValue02 1;
BA_ "GenSigStartValue" SG_ 865 TrafficSign04_SupplSignValue02 255;
BA_ "GenSigSendType" SG_ 865 TrafficSign04_RestWeight 1;
BA_ "GenSigStartValue" SG_ 865 TrafficSign04_RestWeight 1023;
BA_ "GenSigSendType" SG_ 849 TrafficSign03_Height 1;
BA_ "GenSigStartValue" SG_ 849 TrafficSign03_Height 31;
BA_ "GenSigSendType" SG_ 849 TrafficSign03_ID 1;
BA_ "GenSigStartValue" SG_ 849 TrafficSign03_ID 255;
BA_ "GenSigSendType" SG_ 849 TrafficSign03_TrackStatus 1;
BA_ "GenSigStartValue" SG_ 849 TrafficSign03_TrackStatus 7;
BA_ "GenSigSendType" SG_ 849 TrafficSign03_RestHeight 1;
BA_ "GenSigStartValue" SG_ 849 TrafficSign03_RestHeight 127;
BA_ "GenSigSendType" SG_ 849 TrafficSign03_MainSignConfidence 1;
BA_ "GenSigStartValue" SG_ 849 TrafficSign03_MainSignConfidence 127;
BA_ "GenSigSendType" SG_ 849 TrafficSign03_RestDay 1;
BA_ "GenSigStartValue" SG_ 849 TrafficSign03_RestDay 127;
BA_ "GenSigSendType" SG_ 849 TrafficSign03_LongDist 1;
BA_ "GenSigStartValue" SG_ 849 TrafficSign03_LongDist 255;
BA_ "GenSigSendType" SG_ 849 TrafficSign03_RestTime3 1;
BA_ "GenSigStartValue" SG_ 849 TrafficSign03_RestTime3 2047;
BA_ "GenSigSendType" SG_ 849 TrafficSign03_SupplSignType00 1;
BA_ "GenSigStartValue" SG_ 849 TrafficSign03_SupplSignType00 127;
BA_ "GenSigSendType" SG_ 849 TrafficSign03_RestTime1 1;
BA_ "GenSigStartValue" SG_ 849 TrafficSign03_RestTime1 2047;
BA_ "GenSigSendType" SG_ 849 TrafficSign03_SupplSignValue00 1;
BA_ "GenSigStartValue" SG_ 849 TrafficSign03_SupplSignValue00 255;
BA_ "GenSigSendType" SG_ 849 TrafficSign03_RestTime0 1;
BA_ "GenSigStartValue" SG_ 849 TrafficSign03_RestTime0 2047;
BA_ "GenSigSendType" SG_ 849 TrafficSign03_SupplSignType02 1;
BA_ "GenSigStartValue" SG_ 849 TrafficSign03_SupplSignType02 127;
BA_ "GenSigSendType" SG_ 849 TrafficSign03_RestWidth 1;
BA_ "GenSigStartValue" SG_ 849 TrafficSign03_RestWidth 127;
BA_ "GenSigSendType" SG_ 849 TrafficSign03_MainSignValue 1;
BA_ "GenSigStartValue" SG_ 849 TrafficSign03_MainSignValue 255;
BA_ "GenSigSendType" SG_ 849 TrafficSign03_RestTime2 1;
BA_ "GenSigStartValue" SG_ 849 TrafficSign03_RestTime2 2047;
BA_ "GenSigSendType" SG_ 849 TrafficSign03_SupplSign01Conf 1;
BA_ "GenSigStartValue" SG_ 849 TrafficSign03_SupplSign01Conf 127;
BA_ "GenSigSendType" SG_ 849 TrafficSign03_LatDist 1;
BA_ "GenSigStartValue" SG_ 849 TrafficSign03_LatDist 127;
BA_ "GenSigSendType" SG_ 849 TrafficSign03_RestWeight 1;
BA_ "GenSigStartValue" SG_ 849 TrafficSign03_RestWeight 1023;
BA_ "GenSigSendType" SG_ 849 TrafficSign03_TimeStamp 1;
BA_ "GenSigStartValue" SG_ 849 TrafficSign03_TimeStamp 65535;
BA_ "GenSigSendType" SG_ 849 TrafficSign03_RestDist 1;
BA_ "GenSigStartValue" SG_ 849 TrafficSign03_RestDist 32767;
BA_ "GenSigSendType" SG_ 849 TrafficSign03_SupplSign00Conf 1;
BA_ "GenSigStartValue" SG_ 849 TrafficSign03_SupplSign00Conf 127;
BA_ "GenSigSendType" SG_ 849 TrafficSign03_SupplSignType01 1;
BA_ "GenSigStartValue" SG_ 849 TrafficSign03_SupplSignType01 127;
BA_ "GenSigSendType" SG_ 849 TrafficSign03_SupplSign02Conf 1;
BA_ "GenSigStartValue" SG_ 849 TrafficSign03_SupplSign02Conf 127;
BA_ "GenSigSendType" SG_ 849 TrafficSign03_RestSection 1;
BA_ "GenSigStartValue" SG_ 849 TrafficSign03_RestSection 131071;
BA_ "GenSigSendType" SG_ 849 TrafficSign03_SupplSignValue02 1;
BA_ "GenSigStartValue" SG_ 849 TrafficSign03_SupplSignValue02 255;
BA_ "GenSigSendType" SG_ 849 TrafficSign03_MainSignType 1;
BA_ "GenSigStartValue" SG_ 849 TrafficSign03_MainSignType 127;
BA_ "GenSigSendType" SG_ 849 TrafficSign03_SignStability 1;
BA_ "GenSigSendType" SG_ 849 TrafficSign03_SupplSignValue01 1;
BA_ "GenSigStartValue" SG_ 849 TrafficSign03_SupplSignValue01 255;
BA_ "GenSigSendType" SG_ 848 TrafficSign02_RestTime1 1;
BA_ "GenSigStartValue" SG_ 848 TrafficSign02_RestTime1 2047;
BA_ "GenSigSendType" SG_ 848 TrafficSign02_RestHeight 1;
BA_ "GenSigStartValue" SG_ 848 TrafficSign02_RestHeight 127;
BA_ "GenSigSendType" SG_ 848 TrafficSign02_Height 1;
BA_ "GenSigStartValue" SG_ 848 TrafficSign02_Height 31;
BA_ "GenSigSendType" SG_ 848 TrafficSign02_SignStability 1;
BA_ "GenSigSendType" SG_ 848 TrafficSign02_SupplSignType00 1;
BA_ "GenSigStartValue" SG_ 848 TrafficSign02_SupplSignType00 127;
BA_ "GenSigSendType" SG_ 848 TrafficSign02_ID 1;
BA_ "GenSigStartValue" SG_ 848 TrafficSign02_ID 255;
BA_ "GenSigSendType" SG_ 848 TrafficSign02_LatDist 1;
BA_ "GenSigStartValue" SG_ 848 TrafficSign02_LatDist 127;
BA_ "GenSigSendType" SG_ 848 TrafficSign02_MainSignType 1;
BA_ "GenSigStartValue" SG_ 848 TrafficSign02_MainSignType 127;
BA_ "GenSigSendType" SG_ 848 TrafficSign02_SupplSignValue01 1;
BA_ "GenSigStartValue" SG_ 848 TrafficSign02_SupplSignValue01 255;
BA_ "GenSigSendType" SG_ 848 TrafficSign02_SupplSign00Conf 1;
BA_ "GenSigStartValue" SG_ 848 TrafficSign02_SupplSign00Conf 127;
BA_ "GenSigSendType" SG_ 848 TrafficSign02_SupplSignType01 1;
BA_ "GenSigStartValue" SG_ 848 TrafficSign02_SupplSignType01 127;
BA_ "GenSigSendType" SG_ 848 TrafficSign02_RestTime2 1;
BA_ "GenSigStartValue" SG_ 848 TrafficSign02_RestTime2 2047;
BA_ "GenSigSendType" SG_ 848 TrafficSign02_MainSignConfidence 1;
BA_ "GenSigStartValue" SG_ 848 TrafficSign02_MainSignConfidence 127;
BA_ "GenSigSendType" SG_ 848 TrafficSign02_SupplSignValue02 1;
BA_ "GenSigStartValue" SG_ 848 TrafficSign02_SupplSignValue02 255;
BA_ "GenSigSendType" SG_ 848 TrafficSign02_TimeStamp 1;
BA_ "GenSigStartValue" SG_ 848 TrafficSign02_TimeStamp 65535;
BA_ "GenSigSendType" SG_ 848 TrafficSign02_RestSection 1;
BA_ "GenSigStartValue" SG_ 848 TrafficSign02_RestSection 131071;
BA_ "GenSigSendType" SG_ 848 TrafficSign02_RestDist 1;
BA_ "GenSigStartValue" SG_ 848 TrafficSign02_RestDist 32767;
BA_ "GenSigSendType" SG_ 848 TrafficSign02_RestDay 1;
BA_ "GenSigStartValue" SG_ 848 TrafficSign02_RestDay 127;
BA_ "GenSigSendType" SG_ 848 TrafficSign02_SupplSign02Conf 1;
BA_ "GenSigStartValue" SG_ 848 TrafficSign02_SupplSign02Conf 127;
BA_ "GenSigSendType" SG_ 848 TrafficSign02_SupplSign01Conf 1;
BA_ "GenSigStartValue" SG_ 848 TrafficSign02_SupplSign01Conf 127;
BA_ "GenSigSendType" SG_ 848 TrafficSign02_LongDist 1;
BA_ "GenSigStartValue" SG_ 848 TrafficSign02_LongDist 255;
BA_ "GenSigSendType" SG_ 848 TrafficSign02_MainSignValue 1;
BA_ "GenSigStartValue" SG_ 848 TrafficSign02_MainSignValue 255;
BA_ "GenSigSendType" SG_ 848 TrafficSign02_TrackStatus 1;
BA_ "GenSigStartValue" SG_ 848 TrafficSign02_TrackStatus 7;
BA_ "GenSigSendType" SG_ 848 TrafficSign02_SupplSignType02 1;
BA_ "GenSigStartValue" SG_ 848 TrafficSign02_SupplSignType02 127;
BA_ "GenSigSendType" SG_ 848 TrafficSign02_RestWeight 1;
BA_ "GenSigStartValue" SG_ 848 TrafficSign02_RestWeight 1023;
BA_ "GenSigSendType" SG_ 848 TrafficSign02_RestTime0 1;
BA_ "GenSigStartValue" SG_ 848 TrafficSign02_RestTime0 2047;
BA_ "GenSigSendType" SG_ 848 TrafficSign02_SupplSignValue00 1;
BA_ "GenSigStartValue" SG_ 848 TrafficSign02_SupplSignValue00 255;
BA_ "GenSigSendType" SG_ 848 TrafficSign02_RestWidth 1;
BA_ "GenSigStartValue" SG_ 848 TrafficSign02_RestWidth 127;
BA_ "GenSigSendType" SG_ 848 TrafficSign02_RestTime3 1;
BA_ "GenSigStartValue" SG_ 848 TrafficSign02_RestTime3 2047;
BA_ "GenSigSendType" SG_ 841 TrafficSign01_SupplSign02Conf 1;
BA_ "GenSigStartValue" SG_ 841 TrafficSign01_SupplSign02Conf 127;
BA_ "GenSigSendType" SG_ 841 TrafficSign01_RestTime0 1;
BA_ "GenSigStartValue" SG_ 841 TrafficSign01_RestTime0 2047;
BA_ "GenSigSendType" SG_ 841 TrafficSign01_RestTime1 1;
BA_ "GenSigStartValue" SG_ 841 TrafficSign01_RestTime1 2047;
BA_ "GenSigSendType" SG_ 841 TrafficSign01_RestTime3 1;
BA_ "GenSigStartValue" SG_ 841 TrafficSign01_RestTime3 2047;
BA_ "GenSigSendType" SG_ 841 TrafficSign01_RestDay 1;
BA_ "GenSigStartValue" SG_ 841 TrafficSign01_RestDay 127;
BA_ "GenSigSendType" SG_ 841 TrafficSign01_ID 1;
BA_ "GenSigStartValue" SG_ 841 TrafficSign01_ID 255;
BA_ "GenSigSendType" SG_ 841 TrafficSign01_MainSignValue 1;
BA_ "GenSigStartValue" SG_ 841 TrafficSign01_MainSignValue 255;
BA_ "GenSigSendType" SG_ 841 TrafficSign01_MainSignType 1;
BA_ "GenSigStartValue" SG_ 841 TrafficSign01_MainSignType 127;
BA_ "GenSigSendType" SG_ 841 TrafficSign01_LatDist 1;
BA_ "GenSigStartValue" SG_ 841 TrafficSign01_LatDist 127;
BA_ "GenSigSendType" SG_ 841 TrafficSign01_RestWidth 1;
BA_ "GenSigStartValue" SG_ 841 TrafficSign01_RestWidth 127;
BA_ "GenSigSendType" SG_ 841 TrafficSign01_RestWeight 1;
BA_ "GenSigStartValue" SG_ 841 TrafficSign01_RestWeight 1023;
BA_ "GenSigSendType" SG_ 841 TrafficSign01_SupplSignType01 1;
BA_ "GenSigStartValue" SG_ 841 TrafficSign01_SupplSignType01 127;
BA_ "GenSigSendType" SG_ 841 TrafficSign01_SupplSignValue02 1;
BA_ "GenSigStartValue" SG_ 841 TrafficSign01_SupplSignValue02 255;
BA_ "GenSigSendType" SG_ 841 TrafficSign01_SupplSignValue00 1;
BA_ "GenSigStartValue" SG_ 841 TrafficSign01_SupplSignValue00 255;
BA_ "GenSigSendType" SG_ 841 TrafficSign01_TimeStamp 1;
BA_ "GenSigStartValue" SG_ 841 TrafficSign01_TimeStamp 65535;
BA_ "GenSigSendType" SG_ 841 TrafficSign01_SignStability 1;
BA_ "GenSigSendType" SG_ 841 TrafficSign01_RestTime2 1;
BA_ "GenSigStartValue" SG_ 841 TrafficSign01_RestTime2 2047;
BA_ "GenSigSendType" SG_ 841 TrafficSign01_SupplSign00Conf 1;
BA_ "GenSigStartValue" SG_ 841 TrafficSign01_SupplSign00Conf 127;
BA_ "GenSigSendType" SG_ 841 TrafficSign01_SupplSignType02 1;
BA_ "GenSigStartValue" SG_ 841 TrafficSign01_SupplSignType02 127;
BA_ "GenSigSendType" SG_ 841 TrafficSign01_TrackStatus 1;
BA_ "GenSigStartValue" SG_ 841 TrafficSign01_TrackStatus 7;
BA_ "GenSigSendType" SG_ 841 TrafficSign01_SupplSign01Conf 1;
BA_ "GenSigStartValue" SG_ 841 TrafficSign01_SupplSign01Conf 127;
BA_ "GenSigSendType" SG_ 841 TrafficSign01_LongDist 1;
BA_ "GenSigStartValue" SG_ 841 TrafficSign01_LongDist 255;
BA_ "GenSigSendType" SG_ 841 TrafficSign01_Height 1;
BA_ "GenSigStartValue" SG_ 841 TrafficSign01_Height 31;
BA_ "GenSigSendType" SG_ 841 TrafficSign01_SupplSignType00 1;
BA_ "GenSigStartValue" SG_ 841 TrafficSign01_SupplSignType00 127;
BA_ "GenSigSendType" SG_ 841 TrafficSign01_RestSection 1;
BA_ "GenSigStartValue" SG_ 841 TrafficSign01_RestSection 131071;
BA_ "GenSigSendType" SG_ 841 TrafficSign01_MainSignConfidence 1;
BA_ "GenSigStartValue" SG_ 841 TrafficSign01_MainSignConfidence 127;
BA_ "GenSigSendType" SG_ 841 TrafficSign01_RestDist 1;
BA_ "GenSigStartValue" SG_ 841 TrafficSign01_RestDist 32767;
BA_ "GenSigSendType" SG_ 841 TrafficSign01_RestHeight 1;
BA_ "GenSigStartValue" SG_ 841 TrafficSign01_RestHeight 127;
BA_ "GenSigSendType" SG_ 841 TrafficSign01_SupplSignValue01 1;
BA_ "GenSigStartValue" SG_ 841 TrafficSign01_SupplSignValue01 255;
BA_ "GenSigSendType" SG_ 840 TrafficSign00_RestWidth 1;
BA_ "GenSigStartValue" SG_ 840 TrafficSign00_RestWidth 127;
BA_ "GenSigSendType" SG_ 840 TrafficSign00_RestTime3 1;
BA_ "GenSigStartValue" SG_ 840 TrafficSign00_RestTime3 2047;
BA_ "GenSigSendType" SG_ 840 TrafficSign00_RestSection 1;
BA_ "GenSigStartValue" SG_ 840 TrafficSign00_RestSection 131071;
BA_ "GenSigSendType" SG_ 840 TrafficSign00_SupplSignValue01 1;
BA_ "GenSigStartValue" SG_ 840 TrafficSign00_SupplSignValue01 255;
BA_ "GenSigSendType" SG_ 840 TrafficSign00_SupplSignValue00 1;
BA_ "GenSigStartValue" SG_ 840 TrafficSign00_SupplSignValue00 255;
BA_ "GenSigSendType" SG_ 840 TrafficSign00_SupplSign02Conf 1;
BA_ "GenSigStartValue" SG_ 840 TrafficSign00_SupplSign02Conf 127;
BA_ "GenSigSendType" SG_ 840 TrafficSign00_ID 1;
BA_ "GenSigStartValue" SG_ 840 TrafficSign00_ID 255;
BA_ "GenSigSendType" SG_ 840 TrafficSign00_SupplSign01Conf 1;
BA_ "GenSigStartValue" SG_ 840 TrafficSign00_SupplSign01Conf 127;
BA_ "GenSigSendType" SG_ 840 TrafficSign00_SupplSignType01 1;
BA_ "GenSigStartValue" SG_ 840 TrafficSign00_SupplSignType01 127;
BA_ "GenSigSendType" SG_ 840 TrafficSign00_SupplSignType00 1;
BA_ "GenSigStartValue" SG_ 840 TrafficSign00_SupplSignType00 127;
BA_ "GenSigSendType" SG_ 840 TrafficSign00_LongDist 1;
BA_ "GenSigStartValue" SG_ 840 TrafficSign00_LongDist 255;
BA_ "GenSigSendType" SG_ 840 TrafficSign00_RestDay 1;
BA_ "GenSigStartValue" SG_ 840 TrafficSign00_RestDay 127;
BA_ "GenSigSendType" SG_ 840 TrafficSign00_MainSignConfidence 1;
BA_ "GenSigStartValue" SG_ 840 TrafficSign00_MainSignConfidence 127;
BA_ "GenSigSendType" SG_ 840 TrafficSign00_MainSignValue 1;
BA_ "GenSigStartValue" SG_ 840 TrafficSign00_MainSignValue 255;
BA_ "GenSigSendType" SG_ 840 TrafficSign00_Height 1;
BA_ "GenSigStartValue" SG_ 840 TrafficSign00_Height 31;
BA_ "GenSigSendType" SG_ 840 TrafficSign00_SupplSignType02 1;
BA_ "GenSigStartValue" SG_ 840 TrafficSign00_SupplSignType02 127;
BA_ "GenSigSendType" SG_ 840 TrafficSign00_RestTime1 1;
BA_ "GenSigStartValue" SG_ 840 TrafficSign00_RestTime1 2047;
BA_ "GenSigSendType" SG_ 840 TrafficSign00_RestHeight 1;
BA_ "GenSigStartValue" SG_ 840 TrafficSign00_RestHeight 127;
BA_ "GenSigSendType" SG_ 840 TrafficSign00_RestTime2 1;
BA_ "GenSigStartValue" SG_ 840 TrafficSign00_RestTime2 2047;
BA_ "GenSigSendType" SG_ 840 TrafficSign00_RestTime0 1;
BA_ "GenSigStartValue" SG_ 840 TrafficSign00_RestTime0 2047;
BA_ "GenSigSendType" SG_ 840 TrafficSign00_TrackStatus 1;
BA_ "GenSigStartValue" SG_ 840 TrafficSign00_TrackStatus 7;
BA_ "GenSigSendType" SG_ 840 TrafficSign00_RestDist 1;
BA_ "GenSigStartValue" SG_ 840 TrafficSign00_RestDist 32767;
BA_ "GenSigSendType" SG_ 840 TrafficSign00_MainSignType 1;
BA_ "GenSigStartValue" SG_ 840 TrafficSign00_MainSignType 127;
BA_ "GenSigSendType" SG_ 840 TrafficSign00_SignStability 1;
BA_ "GenSigSendType" SG_ 840 TrafficSign00_SupplSignValue02 1;
BA_ "GenSigStartValue" SG_ 840 TrafficSign00_SupplSignValue02 255;
BA_ "GenSigSendType" SG_ 840 TrafficSign00_LatDist 1;
BA_ "GenSigStartValue" SG_ 840 TrafficSign00_LatDist 127;
BA_ "GenSigSendType" SG_ 840 TrafficSign00_TimeStamp 1;
BA_ "GenSigStartValue" SG_ 840 TrafficSign00_TimeStamp 65535;
BA_ "GenSigSendType" SG_ 840 TrafficSign00_SupplSign00Conf 1;
BA_ "GenSigStartValue" SG_ 840 TrafficSign00_SupplSign00Conf 127;
BA_ "GenSigSendType" SG_ 840 TrafficSign00_RestWeight 1;
BA_ "GenSigStartValue" SG_ 840 TrafficSign00_RestWeight 1023;
BA_ "GenSigSendType" SG_ 858 FLCEgoAssumption_DynRoll 1;
BA_ "GenSigStartValue" SG_ 858 FLCEgoAssumption_DynRoll 255;
BA_ "GenSigSendType" SG_ 858 FLCEgoAssumption_EgoLongAcc 1;
BA_ "GenSigStartValue" SG_ 858 FLCEgoAssumption_EgoLongAcc 65535;
BA_ "GenSigSendType" SG_ 858 FLCEgoAssumption_CalibPitch 1;
BA_ "GenSigStartValue" SG_ 858 FLCEgoAssumption_CalibPitch 255;
BA_ "GenSigSendType" SG_ 858 FLCEgoAssumption_EgoLongVel 1;
BA_ "GenSigStartValue" SG_ 858 FLCEgoAssumption_EgoLongVel 65535;
BA_ "GenSigSendType" SG_ 858 FLCEgoAssumption_CalibRoll 1;
BA_ "GenSigStartValue" SG_ 858 FLCEgoAssumption_CalibRoll 255;
BA_ "GenSigSendType" SG_ 858 FLCEgoAssumption_TimeStamp 1;
BA_ "GenSigStartValue" SG_ 858 FLCEgoAssumption_TimeStamp 65535;
BA_ "GenSigSendType" SG_ 858 FLCEgoAssumption_CalibYaw 1;
BA_ "GenSigStartValue" SG_ 858 FLCEgoAssumption_CalibYaw 255;
BA_ "GenSigSendType" SG_ 858 FLCEgoAssumption_DynPitch 1;
BA_ "GenSigStartValue" SG_ 858 FLCEgoAssumption_DynPitch 255;
BA_REL_ "GenSigFirstTimeoutTime" BU_SG_REL_ DACU SG_ 850 VisionProperties_LaneChange 3000;
BA_REL_ "GenSigTimeoutTime" BU_SG_REL_ DACU SG_ 850 VisionProperties_LaneChange 120;
BA_REL_ "GenSigFirstTimeoutTime" BU_SG_REL_ DACU SG_ 850 VisionProperties_AmbientLight 3000;
BA_REL_ "GenSigTimeoutTime" BU_SG_REL_ DACU SG_ 850 VisionProperties_AmbientLight 120;
BA_REL_ "GenSigFirstTimeoutTime" BU_SG_REL_ DACU SG_ 850 VisionProperties_StreetLight 3000;
BA_REL_ "GenSigTimeoutTime" BU_SG_REL_ DACU SG_ 850 VisionProperties_StreetLight 120;
BA_REL_ "GenSigFirstTimeoutTime" BU_SG_REL_ DACU SG_ 850 FLCVideoOutStatus 3000;
BA_REL_ "GenSigTimeoutTime" BU_SG_REL_ DACU SG_ 850 FLCVideoOutStatus 600;
BA_REL_ "GenSigFirstTimeoutTime" BU_SG_REL_ DACU SG_ 850 VisionProperties_NightDay 3000;
BA_REL_ "GenSigTimeoutTime" BU_SG_REL_ DACU SG_ 850 VisionProperties_NightDay 120;
BA_REL_ "GenSigFirstTimeoutTime" BU_SG_REL_ DACU SG_ 850 VisionProperties_BlockConf 3000;
BA_REL_ "GenSigTimeoutTime" BU_SG_REL_ DACU SG_ 850 VisionProperties_BlockConf 120;
BA_REL_ "GenSigFirstTimeoutTime" BU_SG_REL_ DACU SG_ 850 VisionProperties_Weather 3000;
BA_REL_ "GenSigTimeoutTime" BU_SG_REL_ DACU SG_ 850 VisionProperties_Weather 120;
BA_REL_ "GenSigFirstTimeoutTime" BU_SG_REL_ DACU SG_ 872 TrafficSign11_SupplSignValue01 3000;
BA_REL_ "GenSigTimeoutTime" BU_SG_REL_ DACU SG_ 872 TrafficSign11_SupplSignValue01 120;
BA_REL_ "GenSigFirstTimeoutTime" BU_SG_REL_ DACU SG_ 872 TrafficSign11_SupplSignType02 3000;
BA_REL_ "GenSigTimeoutTime" BU_SG_REL_ DACU SG_ 872 TrafficSign11_SupplSignType02 120;
BA_REL_ "GenSigFirstTimeoutTime" BU_SG_REL_ DACU SG_ 872 TrafficSign11_TrackStatus 3000;
BA_REL_ "GenSigTimeoutTime" BU_SG_REL_ DACU SG_ 872 TrafficSign11_TrackStatus 120;
BA_REL_ "GenSigFirstTimeoutTime" BU_SG_REL_ DACU SG_ 872 TrafficSign11_SupplSignValue02 3000;
BA_REL_ "GenSigTimeoutTime" BU_SG_REL_ DACU SG_ 872 TrafficSign11_SupplSignValue02 120;
BA_REL_ "GenSigFirstTimeoutTime" BU_SG_REL_ DACU SG_ 872 TrafficSign11_RestDist 3000;
BA_REL_ "GenSigTimeoutTime" BU_SG_REL_ DACU SG_ 872 TrafficSign11_RestDist 120;
BA_REL_ "GenSigFirstTimeoutTime" BU_SG_REL_ DACU SG_ 872 TrafficSign11_MainSignValue 3000;
BA_REL_ "GenSigTimeoutTime" BU_SG_REL_ DACU SG_ 872 TrafficSign11_MainSignValue 120;
BA_REL_ "GenSigFirstTimeoutTime" BU_SG_REL_ DACU SG_ 872 TrafficSign11_SupplSignType01 3000;
BA_REL_ "GenSigTimeoutTime" BU_SG_REL_ DACU SG_ 872 TrafficSign11_SupplSignType01 120;
BA_REL_ "GenSigFirstTimeoutTime" BU_SG_REL_ DACU SG_ 872 TrafficSign11_RestHeight 3000;
BA_REL_ "GenSigTimeoutTime" BU_SG_REL_ DACU SG_ 872 TrafficSign11_RestHeight 120;
BA_REL_ "GenSigFirstTimeoutTime" BU_SG_REL_ DACU SG_ 872 TrafficSign11_SupplSign02Conf 3000;
BA_REL_ "GenSigTimeoutTime" BU_SG_REL_ DACU SG_ 872 TrafficSign11_SupplSign02Conf 120;
BA_REL_ "GenSigFirstTimeoutTime" BU_SG_REL_ DACU SG_ 872 TrafficSign11_MainSignConfidence 3000;
BA_REL_ "GenSigTimeoutTime" BU_SG_REL_ DACU SG_ 872 TrafficSign11_MainSignConfidence 120;
BA_REL_ "GenSigFirstTimeoutTime" BU_SG_REL_ DACU SG_ 872 TrafficSign11_RestSection 3000;
BA_REL_ "GenSigTimeoutTime" BU_SG_REL_ DACU SG_ 872 TrafficSign11_RestSection 120;
BA_REL_ "GenSigFirstTimeoutTime" BU_SG_REL_ DACU SG_ 872 TrafficSign11_RestTime1 3000;
BA_REL_ "GenSigTimeoutTime" BU_SG_REL_ DACU SG_ 872 TrafficSign11_RestTime1 120;
BA_REL_ "GenSigFirstTimeoutTime" BU_SG_REL_ DACU SG_ 872 TrafficSign11_TimeStamp 3000;
BA_REL_ "GenSigTimeoutTime" BU_SG_REL_ DACU SG_ 872 TrafficSign11_TimeStamp 120;
BA_REL_ "GenSigFirstTimeoutTime" BU_SG_REL_ DACU SG_ 872 TrafficSign11_RestWeight 3000;
BA_REL_ "GenSigTimeoutTime" BU_SG_REL_ DACU SG_ 872 TrafficSign11_RestWeight 120;
BA_REL_ "GenSigFirstTimeoutTime" BU_SG_REL_ DACU SG_ 872 TrafficSign11_RestWidth 3000;
BA_REL_ "GenSigTimeoutTime" BU_SG_REL_ DACU SG_ 872 TrafficSign11_RestWidth 120;
BA_REL_ "GenSigFirstTimeoutTime" BU_SG_REL_ DACU SG_ 872 TrafficSign11_Height 3000;
BA_REL_ "GenSigTimeoutTime" BU_SG_REL_ DACU SG_ 872 TrafficSign11_Height 120;
BA_REL_ "GenSigFirstTimeoutTime" BU_SG_REL_ DACU SG_ 872 TrafficSign11_MainSignType 3000;
BA_REL_ "GenSigTimeoutTime" BU_SG_REL_ DACU SG_ 872 TrafficSign11_MainSignType 120;
BA_REL_ "GenSigFirstTimeoutTime" BU_SG_REL_ DACU SG_ 872 TrafficSign11_ID 3000;
BA_REL_ "GenSigTimeoutTime" BU_SG_REL_ DACU SG_ 872 TrafficSign11_ID 120;
BA_REL_ "GenSigFirstTimeoutTime" BU_SG_REL_ DACU SG_ 872 TrafficSign11_RestTime3 3000;
BA_REL_ "GenSigTimeoutTime" BU_SG_REL_ DACU SG_ 872 TrafficSign11_RestTime3 120;
BA_REL_ "GenSigFirstTimeoutTime" BU_SG_REL_ DACU SG_ 872 TrafficSign11_SupplSignValue00 3000;
BA_REL_ "GenSigTimeoutTime" BU_SG_REL_ DACU SG_ 872 TrafficSign11_SupplSignValue00 120;
BA_REL_ "GenSigFirstTimeoutTime" BU_SG_REL_ DACU SG_ 872 TrafficSign11_RestDay 3000;
BA_REL_ "GenSigTimeoutTime" BU_SG_REL_ DACU SG_ 872 TrafficSign11_RestDay 120;
BA_REL_ "GenSigFirstTimeoutTime" BU_SG_REL_ DACU SG_ 872 TrafficSign11_LongDist 3000;
BA_REL_ "GenSigTimeoutTime" BU_SG_REL_ DACU SG_ 872 TrafficSign11_LongDist 120;
BA_REL_ "GenSigFirstTimeoutTime" BU_SG_REL_ DACU SG_ 872 TrafficSign11_RestTime2 3000;
BA_REL_ "GenSigTimeoutTime" BU_SG_REL_ DACU SG_ 872 TrafficSign11_RestTime2 120;
BA_REL_ "GenSigFirstTimeoutTime" BU_SG_REL_ DACU SG_ 872 TrafficSign11_SupplSignType00 3000;
BA_REL_ "GenSigTimeoutTime" BU_SG_REL_ DACU SG_ 872 TrafficSign11_SupplSignType00 120;
BA_REL_ "GenSigFirstTimeoutTime" BU_SG_REL_ DACU SG_ 872 TrafficSign11_SupplSign00Conf 3000;
BA_REL_ "GenSigTimeoutTime" BU_SG_REL_ DACU SG_ 872 TrafficSign11_SupplSign00Conf 120;
BA_REL_ "GenSigFirstTimeoutTime" BU_SG_REL_ DACU SG_ 872 TrafficSign11_SupplSign01Conf 3000;
BA_REL_ "GenSigTimeoutTime" BU_SG_REL_ DACU SG_ 872 TrafficSign11_SupplSign01Conf 120;
BA_REL_ "GenSigFirstTimeoutTime" BU_SG_REL_ DACU SG_ 872 TrafficSign11_LatDist 3000;
BA_REL_ "GenSigTimeoutTime" BU_SG_REL_ DACU SG_ 872 TrafficSign11_LatDist 120;
BA_REL_ "GenSigFirstTimeoutTime" BU_SG_REL_ DACU SG_ 872 TrafficSign11_RestTime0 3000;
BA_REL_ "GenSigTimeoutTime" BU_SG_REL_ DACU SG_ 872 TrafficSign11_RestTime0 120;
BA_REL_ "GenSigFirstTimeoutTime" BU_SG_REL_ DACU SG_ 872 TrafficSign11_SignStability 3000;
BA_REL_ "GenSigTimeoutTime" BU_SG_REL_ DACU SG_ 872 TrafficSign11_SignStability 120;
BA_REL_ "GenSigFirstTimeoutTime" BU_SG_REL_ DACU SG_ 871 TrafficSign10_SupplSignType02 3000;
BA_REL_ "GenSigTimeoutTime" BU_SG_REL_ DACU SG_ 871 TrafficSign10_SupplSignType02 120;
BA_REL_ "GenSigFirstTimeoutTime" BU_SG_REL_ DACU SG_ 871 TrafficSign10_SignStability 3000;
BA_REL_ "GenSigTimeoutTime" BU_SG_REL_ DACU SG_ 871 TrafficSign10_SignStability 120;
BA_REL_ "GenSigFirstTimeoutTime" BU_SG_REL_ DACU SG_ 871 TrafficSign10_ID 3000;
BA_REL_ "GenSigTimeoutTime" BU_SG_REL_ DACU SG_ 871 TrafficSign10_ID 120;
BA_REL_ "GenSigFirstTimeoutTime" BU_SG_REL_ DACU SG_ 871 TrafficSign10_SupplSignValue00 3000;
BA_REL_ "GenSigTimeoutTime" BU_SG_REL_ DACU SG_ 871 TrafficSign10_SupplSignValue00 120;
BA_REL_ "GenSigFirstTimeoutTime" BU_SG_REL_ DACU SG_ 871 TrafficSign10_RestTime2 3000;
BA_REL_ "GenSigTimeoutTime" BU_SG_REL_ DACU SG_ 871 TrafficSign10_RestTime2 120;
BA_REL_ "GenSigFirstTimeoutTime" BU_SG_REL_ DACU SG_ 871 TrafficSign10_RestSection 3000;
BA_REL_ "GenSigTimeoutTime" BU_SG_REL_ DACU SG_ 871 TrafficSign10_RestSection 120;
BA_REL_ "GenSigFirstTimeoutTime" BU_SG_REL_ DACU SG_ 871 TrafficSign10_SupplSign00Conf 3000;
BA_REL_ "GenSigTimeoutTime" BU_SG_REL_ DACU SG_ 871 TrafficSign10_SupplSign00Conf 120;
BA_REL_ "GenSigFirstTimeoutTime" BU_SG_REL_ DACU SG_ 871 TrafficSign10_MainSignType 3000;
BA_REL_ "GenSigTimeoutTime" BU_SG_REL_ DACU SG_ 871 TrafficSign10_MainSignType 120;
BA_REL_ "GenSigFirstTimeoutTime" BU_SG_REL_ DACU SG_ 871 TrafficSign10_RestTime3 3000;
BA_REL_ "GenSigTimeoutTime" BU_SG_REL_ DACU SG_ 871 TrafficSign10_RestTime3 120;
BA_REL_ "GenSigFirstTimeoutTime" BU_SG_REL_ DACU SG_ 871 TrafficSign10_RestHeight 3000;
BA_REL_ "GenSigTimeoutTime" BU_SG_REL_ DACU SG_ 871 TrafficSign10_RestHeight 120;
BA_REL_ "GenSigFirstTimeoutTime" BU_SG_REL_ DACU SG_ 871 TrafficSign10_RestTime1 3000;
BA_REL_ "GenSigTimeoutTime" BU_SG_REL_ DACU SG_ 871 TrafficSign10_RestTime1 120;
BA_REL_ "GenSigFirstTimeoutTime" BU_SG_REL_ DACU SG_ 871 TrafficSign10_SupplSignType01 3000;
BA_REL_ "GenSigTimeoutTime" BU_SG_REL_ DACU SG_ 871 TrafficSign10_SupplSignType01 120;
BA_REL_ "GenSigFirstTimeoutTime" BU_SG_REL_ DACU SG_ 871 TrafficSign10_RestWidth 3000;
BA_REL_ "GenSigTimeoutTime" BU_SG_REL_ DACU SG_ 871 TrafficSign10_RestWidth 120;
BA_REL_ "GenSigFirstTimeoutTime" BU_SG_REL_ DACU SG_ 871 TrafficSign10_SupplSign02Conf 3000;
BA_REL_ "GenSigTimeoutTime" BU_SG_REL_ DACU SG_ 871 TrafficSign10_SupplSign02Conf 120;
BA_REL_ "GenSigFirstTimeoutTime" BU_SG_REL_ DACU SG_ 871 TrafficSign10_SupplSignValue01 3000;
BA_REL_ "GenSigTimeoutTime" BU_SG_REL_ DACU SG_ 871 TrafficSign10_SupplSignValue01 120;
BA_REL_ "GenSigFirstTimeoutTime" BU_SG_REL_ DACU SG_ 871 TrafficSign10_TimeStamp 3000;
BA_REL_ "GenSigTimeoutTime" BU_SG_REL_ DACU SG_ 871 TrafficSign10_TimeStamp 120;
BA_REL_ "GenSigFirstTimeoutTime" BU_SG_REL_ DACU SG_ 871 TrafficSign10_LongDist 3000;
BA_REL_ "GenSigTimeoutTime" BU_SG_REL_ DACU SG_ 871 TrafficSign10_LongDist 120;
BA_REL_ "GenSigFirstTimeoutTime" BU_SG_REL_ DACU SG_ 871 TrafficSign10_SupplSignValue02 3000;
BA_REL_ "GenSigTimeoutTime" BU_SG_REL_ DACU SG_ 871 TrafficSign10_SupplSignValue02 120;
BA_REL_ "GenSigFirstTimeoutTime" BU_SG_REL_ DACU SG_ 871 TrafficSign10_SupplSign01Conf 3000;
BA_REL_ "GenSigTimeoutTime" BU_SG_REL_ DACU SG_ 871 TrafficSign10_SupplSign01Conf 120;
BA_REL_ "GenSigFirstTimeoutTime" BU_SG_REL_ DACU SG_ 871 TrafficSign10_SupplSignType00 3000;
BA_REL_ "GenSigTimeoutTime" BU_SG_REL_ DACU SG_ 871 TrafficSign10_SupplSignType00 120;
BA_REL_ "GenSigFirstTimeoutTime" BU_SG_REL_ DACU SG_ 871 TrafficSign10_Height 3000;
BA_REL_ "GenSigTimeoutTime" BU_SG_REL_ DACU SG_ 871 TrafficSign10_Height 120;
BA_REL_ "GenSigFirstTimeoutTime" BU_SG_REL_ DACU SG_ 871 TrafficSign10_TrackStatus 3000;
BA_REL_ "GenSigTimeoutTime" BU_SG_REL_ DACU SG_ 871 TrafficSign10_TrackStatus 120;
BA_REL_ "GenSigFirstTimeoutTime" BU_SG_REL_ DACU SG_ 871 TrafficSign10_RestWeight 3000;
BA_REL_ "GenSigTimeoutTime" BU_SG_REL_ DACU SG_ 871 TrafficSign10_RestWeight 120;
BA_REL_ "GenSigFirstTimeoutTime" BU_SG_REL_ DACU SG_ 871 TrafficSign10_RestDay 3000;
BA_REL_ "GenSigTimeoutTime" BU_SG_REL_ DACU SG_ 871 TrafficSign10_RestDay 120;
BA_REL_ "GenSigFirstTimeoutTime" BU_SG_REL_ DACU SG_ 871 TrafficSign10_MainSignConfidence 3000;
BA_REL_ "GenSigTimeoutTime" BU_SG_REL_ DACU SG_ 871 TrafficSign10_MainSignConfidence 120;
BA_REL_ "GenSigFirstTimeoutTime" BU_SG_REL_ DACU SG_ 871 TrafficSign10_RestDist 3000;
BA_REL_ "GenSigTimeoutTime" BU_SG_REL_ DACU SG_ 871 TrafficSign10_RestDist 120;
BA_REL_ "GenSigFirstTimeoutTime" BU_SG_REL_ DACU SG_ 871 TrafficSign10_RestTime0 3000;
BA_REL_ "GenSigTimeoutTime" BU_SG_REL_ DACU SG_ 871 TrafficSign10_RestTime0 120;
BA_REL_ "GenSigFirstTimeoutTime" BU_SG_REL_ DACU SG_ 871 TrafficSign10_MainSignValue 3000;
BA_REL_ "GenSigTimeoutTime" BU_SG_REL_ DACU SG_ 871 TrafficSign10_MainSignValue 120;
BA_REL_ "GenSigFirstTimeoutTime" BU_SG_REL_ DACU SG_ 871 TrafficSign10_LatDist 3000;
BA_REL_ "GenSigTimeoutTime" BU_SG_REL_ DACU SG_ 871 TrafficSign10_LatDist 120;
BA_REL_ "GenSigFirstTimeoutTime" BU_SG_REL_ DACU SG_ 870 TrafficSign09_MainSignValue 3000;
BA_REL_ "GenSigTimeoutTime" BU_SG_REL_ DACU SG_ 870 TrafficSign09_MainSignValue 120;
BA_REL_ "GenSigFirstTimeoutTime" BU_SG_REL_ DACU SG_ 870 TrafficSign09_RestTime0 3000;
BA_REL_ "GenSigTimeoutTime" BU_SG_REL_ DACU SG_ 870 TrafficSign09_RestTime0 120;
BA_REL_ "GenSigFirstTimeoutTime" BU_SG_REL_ DACU SG_ 870 TrafficSign09_LongDist 3000;
BA_REL_ "GenSigTimeoutTime" BU_SG_REL_ DACU SG_ 870 TrafficSign09_LongDist 120;
BA_REL_ "GenSigFirstTimeoutTime" BU_SG_REL_ DACU SG_ 870 TrafficSign09_SupplSign00Conf 3000;
BA_REL_ "GenSigTimeoutTime" BU_SG_REL_ DACU SG_ 870 TrafficSign09_SupplSign00Conf 120;
BA_REL_ "GenSigFirstTimeoutTime" BU_SG_REL_ DACU SG_ 870 TrafficSign09_MainSignConfidence 3000;
BA_REL_ "GenSigTimeoutTime" BU_SG_REL_ DACU SG_ 870 TrafficSign09_MainSignConfidence 120;
BA_REL_ "GenSigFirstTimeoutTime" BU_SG_REL_ DACU SG_ 870 TrafficSign09_Height 3000;
BA_REL_ "GenSigTimeoutTime" BU_SG_REL_ DACU SG_ 870 TrafficSign09_Height 120;
BA_REL_ "GenSigFirstTimeoutTime" BU_SG_REL_ DACU SG_ 870 TrafficSign09_RestTime2 3000;
BA_REL_ "GenSigTimeoutTime" BU_SG_REL_ DACU SG_ 870 TrafficSign09_RestTime2 120;
BA_REL_ "GenSigFirstTimeoutTime" BU_SG_REL_ DACU SG_ 870 TrafficSign09_MainSignType 3000;
BA_REL_ "GenSigTimeoutTime" BU_SG_REL_ DACU SG_ 870 TrafficSign09_MainSignType 120;
BA_REL_ "GenSigFirstTimeoutTime" BU_SG_REL_ DACU SG_ 870 TrafficSign09_SupplSignType02 3000;
BA_REL_ "GenSigTimeoutTime" BU_SG_REL_ DACU SG_ 870 TrafficSign09_SupplSignType02 120;
BA_REL_ "GenSigFirstTimeoutTime" BU_SG_REL_ DACU SG_ 870 TrafficSign09_SupplSign01Conf 3000;
BA_REL_ "GenSigTimeoutTime" BU_SG_REL_ DACU SG_ 870 TrafficSign09_SupplSign01Conf 120;
BA_REL_ "GenSigFirstTimeoutTime" BU_SG_REL_ DACU SG_ 870 TrafficSign09_RestSection 3000;
BA_REL_ "GenSigTimeoutTime" BU_SG_REL_ DACU SG_ 870 TrafficSign09_RestSection 120;
BA_REL_ "GenSigFirstTimeoutTime" BU_SG_REL_ DACU SG_ 870 TrafficSign09_SupplSign02Conf 3000;
BA_REL_ "GenSigTimeoutTime" BU_SG_REL_ DACU SG_ 870 TrafficSign09_SupplSign02Conf 120;
BA_REL_ "GenSigFirstTimeoutTime" BU_SG_REL_ DACU SG_ 870 TrafficSign09_SupplSignValue01 3000;
BA_REL_ "GenSigTimeoutTime" BU_SG_REL_ DACU SG_ 870 TrafficSign09_SupplSignValue01 120;
BA_REL_ "GenSigFirstTimeoutTime" BU_SG_REL_ DACU SG_ 870 TrafficSign09_RestWeight 3000;
BA_REL_ "GenSigTimeoutTime" BU_SG_REL_ DACU SG_ 870 TrafficSign09_RestWeight 120;
BA_REL_ "GenSigFirstTimeoutTime" BU_SG_REL_ DACU SG_ 870 TrafficSign09_LatDist 3000;
BA_REL_ "GenSigTimeoutTime" BU_SG_REL_ DACU SG_ 870 TrafficSign09_LatDist 120;
BA_REL_ "GenSigFirstTimeoutTime" BU_SG_REL_ DACU SG_ 870 TrafficSign09_SignStability 3000;
BA_REL_ "GenSigTimeoutTime" BU_SG_REL_ DACU SG_ 870 TrafficSign09_SignStability 120;
BA_REL_ "GenSigFirstTimeoutTime" BU_SG_REL_ DACU SG_ 870 TrafficSign09_RestTime1 3000;
BA_REL_ "GenSigTimeoutTime" BU_SG_REL_ DACU SG_ 870 TrafficSign09_RestTime1 120;
BA_REL_ "GenSigFirstTimeoutTime" BU_SG_REL_ DACU SG_ 870 TrafficSign09_SupplSignType00 3000;
BA_REL_ "GenSigTimeoutTime" BU_SG_REL_ DACU SG_ 870 TrafficSign09_SupplSignType00 120;
BA_REL_ "GenSigFirstTimeoutTime" BU_SG_REL_ DACU SG_ 870 TrafficSign09_RestHeight 3000;
BA_REL_ "GenSigTimeoutTime" BU_SG_REL_ DACU SG_ 870 TrafficSign09_RestHeight 120;
BA_REL_ "GenSigFirstTimeoutTime" BU_SG_REL_ DACU SG_ 870 TrafficSign09_RestDay 3000;
BA_REL_ "GenSigTimeoutTime" BU_SG_REL_ DACU SG_ 870 TrafficSign09_RestDay 120;
BA_REL_ "GenSigFirstTimeoutTime" BU_SG_REL_ DACU SG_ 870 TrafficSign09_RestDist 3000;
BA_REL_ "GenSigTimeoutTime" BU_SG_REL_ DACU SG_ 870 TrafficSign09_RestDist 120;
BA_REL_ "GenSigFirstTimeoutTime" BU_SG_REL_ DACU SG_ 870 TrafficSign09_SupplSignValue00 3000;
BA_REL_ "GenSigTimeoutTime" BU_SG_REL_ DACU SG_ 870 TrafficSign09_SupplSignValue00 120;
BA_REL_ "GenSigFirstTimeoutTime" BU_SG_REL_ DACU SG_ 870 TrafficSign09_TrackStatus 3000;
BA_REL_ "GenSigTimeoutTime" BU_SG_REL_ DACU SG_ 870 TrafficSign09_TrackStatus 120;
BA_REL_ "GenSigFirstTimeoutTime" BU_SG_REL_ DACU SG_ 870 TrafficSign09_RestTime3 3000;
BA_REL_ "GenSigTimeoutTime" BU_SG_REL_ DACU SG_ 870 TrafficSign09_RestTime3 120;
BA_REL_ "GenSigFirstTimeoutTime" BU_SG_REL_ DACU SG_ 870 TrafficSign09_SupplSignType01 3000;
BA_REL_ "GenSigTimeoutTime" BU_SG_REL_ DACU SG_ 870 TrafficSign09_SupplSignType01 120;
BA_REL_ "GenSigFirstTimeoutTime" BU_SG_REL_ DACU SG_ 870 TrafficSign09_ID 3000;
BA_REL_ "GenSigTimeoutTime" BU_SG_REL_ DACU SG_ 870 TrafficSign09_ID 120;
BA_REL_ "GenSigFirstTimeoutTime" BU_SG_REL_ DACU SG_ 870 TrafficSign09_RestWidth 3000;
BA_REL_ "GenSigTimeoutTime" BU_SG_REL_ DACU SG_ 870 TrafficSign09_RestWidth 120;
BA_REL_ "GenSigFirstTimeoutTime" BU_SG_REL_ DACU SG_ 870 TrafficSign09_SupplSignValue02 3000;
BA_REL_ "GenSigTimeoutTime" BU_SG_REL_ DACU SG_ 870 TrafficSign09_SupplSignValue02 120;
BA_REL_ "GenSigFirstTimeoutTime" BU_SG_REL_ DACU SG_ 870 TrafficSign09_TimeStamp 3000;
BA_REL_ "GenSigTimeoutTime" BU_SG_REL_ DACU SG_ 870 TrafficSign09_TimeStamp 120;
BA_REL_ "GenSigFirstTimeoutTime" BU_SG_REL_ DACU SG_ 869 TrafficSign08_SupplSign00Conf 3000;
BA_REL_ "GenSigTimeoutTime" BU_SG_REL_ DACU SG_ 869 TrafficSign08_SupplSign00Conf 120;
BA_REL_ "GenSigFirstTimeoutTime" BU_SG_REL_ DACU SG_ 869 TrafficSign08_SignStability 3000;
BA_REL_ "GenSigTimeoutTime" BU_SG_REL_ DACU SG_ 869 TrafficSign08_SignStability 120;
BA_REL_ "GenSigFirstTimeoutTime" BU_SG_REL_ DACU SG_ 869 TrafficSign08_MainSignType 3000;
BA_REL_ "GenSigTimeoutTime" BU_SG_REL_ DACU SG_ 869 TrafficSign08_MainSignType 120;
BA_REL_ "GenSigFirstTimeoutTime" BU_SG_REL_ DACU SG_ 869 TrafficSign08_SupplSign02Conf 3000;
BA_REL_ "GenSigTimeoutTime" BU_SG_REL_ DACU SG_ 869 TrafficSign08_SupplSign02Conf 120;
BA_REL_ "GenSigFirstTimeoutTime" BU_SG_REL_ DACU SG_ 869 TrafficSign08_RestHeight 3000;
BA_REL_ "GenSigTimeoutTime" BU_SG_REL_ DACU SG_ 869 TrafficSign08_RestHeight 120;
BA_REL_ "GenSigFirstTimeoutTime" BU_SG_REL_ DACU SG_ 869 TrafficSign08_LatDist 3000;
BA_REL_ "GenSigTimeoutTime" BU_SG_REL_ DACU SG_ 869 TrafficSign08_LatDist 120;
BA_REL_ "GenSigFirstTimeoutTime" BU_SG_REL_ DACU SG_ 869 TrafficSign08_SupplSignType02 3000;
BA_REL_ "GenSigTimeoutTime" BU_SG_REL_ DACU SG_ 869 TrafficSign08_SupplSignType02 120;
BA_REL_ "GenSigFirstTimeoutTime" BU_SG_REL_ DACU SG_ 869 TrafficSign08_SupplSignType01 3000;
BA_REL_ "GenSigTimeoutTime" BU_SG_REL_ DACU SG_ 869 TrafficSign08_SupplSignType01 120;
BA_REL_ "GenSigFirstTimeoutTime" BU_SG_REL_ DACU SG_ 869 TrafficSign08_SupplSign01Conf 3000;
BA_REL_ "GenSigTimeoutTime" BU_SG_REL_ DACU SG_ 869 TrafficSign08_SupplSign01Conf 120;
BA_REL_ "GenSigFirstTimeoutTime" BU_SG_REL_ DACU SG_ 869 TrafficSign08_MainSignConfidence 3000;
BA_REL_ "GenSigTimeoutTime" BU_SG_REL_ DACU SG_ 869 TrafficSign08_MainSignConfidence 120;
BA_REL_ "GenSigFirstTimeoutTime" BU_SG_REL_ DACU SG_ 869 TrafficSign08_RestSection 3000;
BA_REL_ "GenSigTimeoutTime" BU_SG_REL_ DACU SG_ 869 TrafficSign08_RestSection 120;
BA_REL_ "GenSigFirstTimeoutTime" BU_SG_REL_ DACU SG_ 869 TrafficSign08_RestTime3 3000;
BA_REL_ "GenSigTimeoutTime" BU_SG_REL_ DACU SG_ 869 TrafficSign08_RestTime3 120;
BA_REL_ "GenSigFirstTimeoutTime" BU_SG_REL_ DACU SG_ 869 TrafficSign08_TimeStamp 3000;
BA_REL_ "GenSigTimeoutTime" BU_SG_REL_ DACU SG_ 869 TrafficSign08_TimeStamp 120;
BA_REL_ "GenSigFirstTimeoutTime" BU_SG_REL_ DACU SG_ 869 TrafficSign08_RestDist 3000;
BA_REL_ "GenSigTimeoutTime" BU_SG_REL_ DACU SG_ 869 TrafficSign08_RestDist 120;
BA_REL_ "GenSigFirstTimeoutTime" BU_SG_REL_ DACU SG_ 869 TrafficSign08_SupplSignType00 3000;
BA_REL_ "GenSigTimeoutTime" BU_SG_REL_ DACU SG_ 869 TrafficSign08_SupplSignType00 120;
BA_REL_ "GenSigFirstTimeoutTime" BU_SG_REL_ DACU SG_ 869 TrafficSign08_RestTime2 3000;
BA_REL_ "GenSigTimeoutTime" BU_SG_REL_ DACU SG_ 869 TrafficSign08_RestTime2 120;
BA_REL_ "GenSigFirstTimeoutTime" BU_SG_REL_ DACU SG_ 869 TrafficSign08_SupplSignValue02 3000;
BA_REL_ "GenSigTimeoutTime" BU_SG_REL_ DACU SG_ 869 TrafficSign08_SupplSignValue02 120;
BA_REL_ "GenSigFirstTimeoutTime" BU_SG_REL_ DACU SG_ 869 TrafficSign08_TrackStatus 3000;
BA_REL_ "GenSigTimeoutTime" BU_SG_REL_ DACU SG_ 869 TrafficSign08_TrackStatus 120;
BA_REL_ "GenSigFirstTimeoutTime" BU_SG_REL_ DACU SG_ 869 TrafficSign08_RestWeight 3000;
BA_REL_ "GenSigTimeoutTime" BU_SG_REL_ DACU SG_ 869 TrafficSign08_RestWeight 120;
BA_REL_ "GenSigFirstTimeoutTime" BU_SG_REL_ DACU SG_ 869 TrafficSign08_SupplSignValue01 3000;
BA_REL_ "GenSigTimeoutTime" BU_SG_REL_ DACU SG_ 869 TrafficSign08_SupplSignValue01 120;
BA_REL_ "GenSigFirstTimeoutTime" BU_SG_REL_ DACU SG_ 869 TrafficSign08_RestTime0 3000;
BA_REL_ "GenSigTimeoutTime" BU_SG_REL_ DACU SG_ 869 TrafficSign08_RestTime0 120;
BA_REL_ "GenSigFirstTimeoutTime" BU_SG_REL_ DACU SG_ 869 TrafficSign08_LongDist 3000;
BA_REL_ "GenSigTimeoutTime" BU_SG_REL_ DACU SG_ 869 TrafficSign08_LongDist 120;
BA_REL_ "GenSigFirstTimeoutTime" BU_SG_REL_ DACU SG_ 869 TrafficSign08_MainSignValue 3000;
BA_REL_ "GenSigTimeoutTime" BU_SG_REL_ DACU SG_ 869 TrafficSign08_MainSignValue 120;
BA_REL_ "GenSigFirstTimeoutTime" BU_SG_REL_ DACU SG_ 869 TrafficSign08_RestWidth 3000;
BA_REL_ "GenSigTimeoutTime" BU_SG_REL_ DACU SG_ 869 TrafficSign08_RestWidth 120;
BA_REL_ "GenSigFirstTimeoutTime" BU_SG_REL_ DACU SG_ 869 TrafficSign08_RestDay 3000;
BA_REL_ "GenSigTimeoutTime" BU_SG_REL_ DACU SG_ 869 TrafficSign08_RestDay 120;
BA_REL_ "GenSigFirstTimeoutTime" BU_SG_REL_ DACU SG_ 869 TrafficSign08_ID 3000;
BA_REL_ "GenSigTimeoutTime" BU_SG_REL_ DACU SG_ 869 TrafficSign08_ID 120;
BA_REL_ "GenSigFirstTimeoutTime" BU_SG_REL_ DACU SG_ 869 TrafficSign08_Height 3000;
BA_REL_ "GenSigTimeoutTime" BU_SG_REL_ DACU SG_ 869 TrafficSign08_Height 120;
BA_REL_ "GenSigFirstTimeoutTime" BU_SG_REL_ DACU SG_ 869 TrafficSign08_SupplSignValue00 3000;
BA_REL_ "GenSigTimeoutTime" BU_SG_REL_ DACU SG_ 869 TrafficSign08_SupplSignValue00 120;
BA_REL_ "GenSigFirstTimeoutTime" BU_SG_REL_ DACU SG_ 869 TrafficSign08_RestTime1 3000;
BA_REL_ "GenSigTimeoutTime" BU_SG_REL_ DACU SG_ 869 TrafficSign08_RestTime1 120;
BA_REL_ "GenSigFirstTimeoutTime" BU_SG_REL_ DACU SG_ 868 TrafficSign07_MainSignConfidence 3000;
BA_REL_ "GenSigTimeoutTime" BU_SG_REL_ DACU SG_ 868 TrafficSign07_MainSignConfidence 120;
BA_REL_ "GenSigFirstTimeoutTime" BU_SG_REL_ DACU SG_ 868 TrafficSign07_SupplSign00Conf 3000;
BA_REL_ "GenSigTimeoutTime" BU_SG_REL_ DACU SG_ 868 TrafficSign07_SupplSign00Conf 120;
BA_REL_ "GenSigFirstTimeoutTime" BU_SG_REL_ DACU SG_ 868 TrafficSign07_SupplSign01Conf 3000;
BA_REL_ "GenSigTimeoutTime" BU_SG_REL_ DACU SG_ 868 TrafficSign07_SupplSign01Conf 120;
BA_REL_ "GenSigFirstTimeoutTime" BU_SG_REL_ DACU SG_ 868 TrafficSign07_SupplSignValue00 3000;
BA_REL_ "GenSigTimeoutTime" BU_SG_REL_ DACU SG_ 868 TrafficSign07_SupplSignValue00 120;
BA_REL_ "GenSigFirstTimeoutTime" BU_SG_REL_ DACU SG_ 868 TrafficSign07_RestTime3 3000;
BA_REL_ "GenSigTimeoutTime" BU_SG_REL_ DACU SG_ 868 TrafficSign07_RestTime3 120;
BA_REL_ "GenSigFirstTimeoutTime" BU_SG_REL_ DACU SG_ 868 TrafficSign07_SupplSign02Conf 3000;
BA_REL_ "GenSigTimeoutTime" BU_SG_REL_ DACU SG_ 868 TrafficSign07_SupplSign02Conf 120;
BA_REL_ "GenSigFirstTimeoutTime" BU_SG_REL_ DACU SG_ 868 TrafficSign07_ID 3000;
BA_REL_ "GenSigTimeoutTime" BU_SG_REL_ DACU SG_ 868 TrafficSign07_ID 120;
BA_REL_ "GenSigFirstTimeoutTime" BU_SG_REL_ DACU SG_ 868 TrafficSign07_SupplSignType01 3000;
BA_REL_ "GenSigTimeoutTime" BU_SG_REL_ DACU SG_ 868 TrafficSign07_SupplSignType01 120;
BA_REL_ "GenSigFirstTimeoutTime" BU_SG_REL_ DACU SG_ 868 TrafficSign07_TrackStatus 3000;
BA_REL_ "GenSigTimeoutTime" BU_SG_REL_ DACU SG_ 868 TrafficSign07_TrackStatus 120;
BA_REL_ "GenSigFirstTimeoutTime" BU_SG_REL_ DACU SG_ 868 TrafficSign07_RestSection 3000;
BA_REL_ "GenSigTimeoutTime" BU_SG_REL_ DACU SG_ 868 TrafficSign07_RestSection 120;
BA_REL_ "GenSigFirstTimeoutTime" BU_SG_REL_ DACU SG_ 868 TrafficSign07_SupplSignValue02 3000;
BA_REL_ "GenSigTimeoutTime" BU_SG_REL_ DACU SG_ 868 TrafficSign07_SupplSignValue02 120;
BA_REL_ "GenSigFirstTimeoutTime" BU_SG_REL_ DACU SG_ 868 TrafficSign07_SupplSignType00 3000;
BA_REL_ "GenSigTimeoutTime" BU_SG_REL_ DACU SG_ 868 TrafficSign07_SupplSignType00 120;
BA_REL_ "GenSigFirstTimeoutTime" BU_SG_REL_ DACU SG_ 868 TrafficSign07_RestTime2 3000;
BA_REL_ "GenSigTimeoutTime" BU_SG_REL_ DACU SG_ 868 TrafficSign07_RestTime2 120;
BA_REL_ "GenSigFirstTimeoutTime" BU_SG_REL_ DACU SG_ 868 TrafficSign07_Height 3000;
BA_REL_ "GenSigTimeoutTime" BU_SG_REL_ DACU SG_ 868 TrafficSign07_Height 120;
BA_REL_ "GenSigFirstTimeoutTime" BU_SG_REL_ DACU SG_ 868 TrafficSign07_LatDist 3000;
BA_REL_ "GenSigTimeoutTime" BU_SG_REL_ DACU SG_ 868 TrafficSign07_LatDist 120;
BA_REL_ "GenSigFirstTimeoutTime" BU_SG_REL_ DACU SG_ 868 TrafficSign07_SupplSignType02 3000;
BA_REL_ "GenSigTimeoutTime" BU_SG_REL_ DACU SG_ 868 TrafficSign07_SupplSignType02 120;
BA_REL_ "GenSigFirstTimeoutTime" BU_SG_REL_ DACU SG_ 868 TrafficSign07_SignStability 3000;
BA_REL_ "GenSigTimeoutTime" BU_SG_REL_ DACU SG_ 868 TrafficSign07_SignStability 120;
BA_REL_ "GenSigFirstTimeoutTime" BU_SG_REL_ DACU SG_ 868 TrafficSign07_RestDist 3000;
BA_REL_ "GenSigTimeoutTime" BU_SG_REL_ DACU SG_ 868 TrafficSign07_RestDist 120;
BA_REL_ "GenSigFirstTimeoutTime" BU_SG_REL_ DACU SG_ 868 TrafficSign07_RestDay 3000;
BA_REL_ "GenSigTimeoutTime" BU_SG_REL_ DACU SG_ 868 TrafficSign07_RestDay 120;
BA_REL_ "GenSigFirstTimeoutTime" BU_SG_REL_ DACU SG_ 868 TrafficSign07_RestWidth 3000;
BA_REL_ "GenSigTimeoutTime" BU_SG_REL_ DACU SG_ 868 TrafficSign07_RestWidth 120;
BA_REL_ "GenSigFirstTimeoutTime" BU_SG_REL_ DACU SG_ 868 TrafficSign07_TimeStamp 3000;
BA_REL_ "GenSigTimeoutTime" BU_SG_REL_ DACU SG_ 868 TrafficSign07_TimeStamp 120;
BA_REL_ "GenSigFirstTimeoutTime" BU_SG_REL_ DACU SG_ 868 TrafficSign07_RestTime1 3000;
BA_REL_ "GenSigTimeoutTime" BU_SG_REL_ DACU SG_ 868 TrafficSign07_RestTime1 120;
BA_REL_ "GenSigFirstTimeoutTime" BU_SG_REL_ DACU SG_ 868 TrafficSign07_RestTime0 3000;
BA_REL_ "GenSigTimeoutTime" BU_SG_REL_ DACU SG_ 868 TrafficSign07_RestTime0 120;
BA_REL_ "GenSigFirstTimeoutTime" BU_SG_REL_ DACU SG_ 868 TrafficSign07_SupplSignValue01 3000;
BA_REL_ "GenSigTimeoutTime" BU_SG_REL_ DACU SG_ 868 TrafficSign07_SupplSignValue01 120;
BA_REL_ "GenSigFirstTimeoutTime" BU_SG_REL_ DACU SG_ 868 TrafficSign07_LongDist 3000;
BA_REL_ "GenSigTimeoutTime" BU_SG_REL_ DACU SG_ 868 TrafficSign07_LongDist 120;
BA_REL_ "GenSigFirstTimeoutTime" BU_SG_REL_ DACU SG_ 868 TrafficSign07_MainSignType 3000;
BA_REL_ "GenSigTimeoutTime" BU_SG_REL_ DACU SG_ 868 TrafficSign07_MainSignType 120;
BA_REL_ "GenSigFirstTimeoutTime" BU_SG_REL_ DACU SG_ 868 TrafficSign07_MainSignValue 3000;
BA_REL_ "GenSigTimeoutTime" BU_SG_REL_ DACU SG_ 868 TrafficSign07_MainSignValue 120;
BA_REL_ "GenSigFirstTimeoutTime" BU_SG_REL_ DACU SG_ 868 TrafficSign07_RestWeight 3000;
BA_REL_ "GenSigTimeoutTime" BU_SG_REL_ DACU SG_ 868 TrafficSign07_RestWeight 120;
BA_REL_ "GenSigFirstTimeoutTime" BU_SG_REL_ DACU SG_ 868 TrafficSign07_RestHeight 3000;
BA_REL_ "GenSigTimeoutTime" BU_SG_REL_ DACU SG_ 868 TrafficSign07_RestHeight 120;
BA_REL_ "GenSigFirstTimeoutTime" BU_SG_REL_ DACU SG_ 867 TrafficSign06_RestWeight 3000;
BA_REL_ "GenSigTimeoutTime" BU_SG_REL_ DACU SG_ 867 TrafficSign06_RestWeight 120;
BA_REL_ "GenSigFirstTimeoutTime" BU_SG_REL_ DACU SG_ 867 TrafficSign06_SupplSign01Conf 3000;
BA_REL_ "GenSigTimeoutTime" BU_SG_REL_ DACU SG_ 867 TrafficSign06_SupplSign01Conf 120;
BA_REL_ "GenSigFirstTimeoutTime" BU_SG_REL_ DACU SG_ 867 TrafficSign06_SupplSignValue02 3000;
BA_REL_ "GenSigTimeoutTime" BU_SG_REL_ DACU SG_ 867 TrafficSign06_SupplSignValue02 120;
BA_REL_ "GenSigFirstTimeoutTime" BU_SG_REL_ DACU SG_ 867 TrafficSign06_RestTime1 3000;
BA_REL_ "GenSigTimeoutTime" BU_SG_REL_ DACU SG_ 867 TrafficSign06_RestTime1 120;
BA_REL_ "GenSigFirstTimeoutTime" BU_SG_REL_ DACU SG_ 867 TrafficSign06_SupplSignType02 3000;
BA_REL_ "GenSigTimeoutTime" BU_SG_REL_ DACU SG_ 867 TrafficSign06_SupplSignType02 120;
BA_REL_ "GenSigFirstTimeoutTime" BU_SG_REL_ DACU SG_ 867 TrafficSign06_SignStability 3000;
BA_REL_ "GenSigTimeoutTime" BU_SG_REL_ DACU SG_ 867 TrafficSign06_SignStability 120;
BA_REL_ "GenSigFirstTimeoutTime" BU_SG_REL_ DACU SG_ 867 TrafficSign06_SupplSign00Conf 3000;
BA_REL_ "GenSigTimeoutTime" BU_SG_REL_ DACU SG_ 867 TrafficSign06_SupplSign00Conf 120;
BA_REL_ "GenSigFirstTimeoutTime" BU_SG_REL_ DACU SG_ 867 TrafficSign06_MainSignValue 3000;
BA_REL_ "GenSigTimeoutTime" BU_SG_REL_ DACU SG_ 867 TrafficSign06_MainSignValue 120;
BA_REL_ "GenSigFirstTimeoutTime" BU_SG_REL_ DACU SG_ 867 TrafficSign06_SupplSign02Conf 3000;
BA_REL_ "GenSigTimeoutTime" BU_SG_REL_ DACU SG_ 867 TrafficSign06_SupplSign02Conf 120;
BA_REL_ "GenSigFirstTimeoutTime" BU_SG_REL_ DACU SG_ 867 TrafficSign06_SupplSignValue01 3000;
BA_REL_ "GenSigTimeoutTime" BU_SG_REL_ DACU SG_ 867 TrafficSign06_SupplSignValue01 120;
BA_REL_ "GenSigFirstTimeoutTime" BU_SG_REL_ DACU SG_ 867 TrafficSign06_RestTime2 3000;
BA_REL_ "GenSigTimeoutTime" BU_SG_REL_ DACU SG_ 867 TrafficSign06_RestTime2 120;
BA_REL_ "GenSigFirstTimeoutTime" BU_SG_REL_ DACU SG_ 867 TrafficSign06_Height 3000;
BA_REL_ "GenSigTimeoutTime" BU_SG_REL_ DACU SG_ 867 TrafficSign06_Height 120;
BA_REL_ "GenSigFirstTimeoutTime" BU_SG_REL_ DACU SG_ 867 TrafficSign06_LatDist 3000;
BA_REL_ "GenSigTimeoutTime" BU_SG_REL_ DACU SG_ 867 TrafficSign06_LatDist 120;
BA_REL_ "GenSigFirstTimeoutTime" BU_SG_REL_ DACU SG_ 867 TrafficSign06_MainSignType 3000;
BA_REL_ "GenSigTimeoutTime" BU_SG_REL_ DACU SG_ 867 TrafficSign06_MainSignType 120;
BA_REL_ "GenSigFirstTimeoutTime" BU_SG_REL_ DACU SG_ 867 TrafficSign06_LongDist 3000;
BA_REL_ "GenSigTimeoutTime" BU_SG_REL_ DACU SG_ 867 TrafficSign06_LongDist 120;
BA_REL_ "GenSigFirstTimeoutTime" BU_SG_REL_ DACU SG_ 867 TrafficSign06_TimeStamp 3000;
BA_REL_ "GenSigTimeoutTime" BU_SG_REL_ DACU SG_ 867 TrafficSign06_TimeStamp 120;
BA_REL_ "GenSigFirstTimeoutTime" BU_SG_REL_ DACU SG_ 867 TrafficSign06_RestDist 3000;
BA_REL_ "GenSigTimeoutTime" BU_SG_REL_ DACU SG_ 867 TrafficSign06_RestDist 120;
BA_REL_ "GenSigFirstTimeoutTime" BU_SG_REL_ DACU SG_ 867 TrafficSign06_RestTime0 3000;
BA_REL_ "GenSigTimeoutTime" BU_SG_REL_ DACU SG_ 867 TrafficSign06_RestTime0 120;
BA_REL_ "GenSigFirstTimeoutTime" BU_SG_REL_ DACU SG_ 867 TrafficSign06_SupplSignType01 3000;
BA_REL_ "GenSigTimeoutTime" BU_SG_REL_ DACU SG_ 867 TrafficSign06_SupplSignType01 120;
BA_REL_ "GenSigFirstTimeoutTime" BU_SG_REL_ DACU SG_ 867 TrafficSign06_TrackStatus 3000;
BA_REL_ "GenSigTimeoutTime" BU_SG_REL_ DACU SG_ 867 TrafficSign06_TrackStatus 120;
BA_REL_ "GenSigFirstTimeoutTime" BU_SG_REL_ DACU SG_ 867 TrafficSign06_MainSignConfidence 3000;
BA_REL_ "GenSigTimeoutTime" BU_SG_REL_ DACU SG_ 867 TrafficSign06_MainSignConfidence 120;
BA_REL_ "GenSigFirstTimeoutTime" BU_SG_REL_ DACU SG_ 867 TrafficSign06_RestHeight 3000;
BA_REL_ "GenSigTimeoutTime" BU_SG_REL_ DACU SG_ 867 TrafficSign06_RestHeight 120;
BA_REL_ "GenSigFirstTimeoutTime" BU_SG_REL_ DACU SG_ 867 TrafficSign06_RestSection 3000;
BA_REL_ "GenSigTimeoutTime" BU_SG_REL_ DACU SG_ 867 TrafficSign06_RestSection 120;
BA_REL_ "GenSigFirstTimeoutTime" BU_SG_REL_ DACU SG_ 867 TrafficSign06_RestDay 3000;
BA_REL_ "GenSigTimeoutTime" BU_SG_REL_ DACU SG_ 867 TrafficSign06_RestDay 120;
BA_REL_ "GenSigFirstTimeoutTime" BU_SG_REL_ DACU SG_ 867 TrafficSign06_SupplSignValue00 3000;
BA_REL_ "GenSigTimeoutTime" BU_SG_REL_ DACU SG_ 867 TrafficSign06_SupplSignValue00 120;
BA_REL_ "GenSigFirstTimeoutTime" BU_SG_REL_ DACU SG_ 867 TrafficSign06_ID 3000;
BA_REL_ "GenSigTimeoutTime" BU_SG_REL_ DACU SG_ 867 TrafficSign06_ID 120;
BA_REL_ "GenSigFirstTimeoutTime" BU_SG_REL_ DACU SG_ 867 TrafficSign06_RestWidth 3000;
BA_REL_ "GenSigTimeoutTime" BU_SG_REL_ DACU SG_ 867 TrafficSign06_RestWidth 120;
BA_REL_ "GenSigFirstTimeoutTime" BU_SG_REL_ DACU SG_ 867 TrafficSign06_RestTime3 3000;
BA_REL_ "GenSigTimeoutTime" BU_SG_REL_ DACU SG_ 867 TrafficSign06_RestTime3 120;
BA_REL_ "GenSigFirstTimeoutTime" BU_SG_REL_ DACU SG_ 867 TrafficSign06_SupplSignType00 3000;
BA_REL_ "GenSigTimeoutTime" BU_SG_REL_ DACU SG_ 867 TrafficSign06_SupplSignType00 120;
BA_REL_ "GenSigFirstTimeoutTime" BU_SG_REL_ DACU SG_ 866 TrafficSign05_SupplSignType00 3000;
BA_REL_ "GenSigTimeoutTime" BU_SG_REL_ DACU SG_ 866 TrafficSign05_SupplSignType00 120;
BA_REL_ "GenSigFirstTimeoutTime" BU_SG_REL_ DACU SG_ 866 TrafficSign05_ID 3000;
BA_REL_ "GenSigTimeoutTime" BU_SG_REL_ DACU SG_ 866 TrafficSign05_ID 120;
BA_REL_ "GenSigFirstTimeoutTime" BU_SG_REL_ DACU SG_ 866 TrafficSign05_SupplSignValue00 3000;
BA_REL_ "GenSigTimeoutTime" BU_SG_REL_ DACU SG_ 866 TrafficSign05_SupplSignValue00 120;
BA_REL_ "GenSigFirstTimeoutTime" BU_SG_REL_ DACU SG_ 866 TrafficSign05_MainSignConfidence 3000;
BA_REL_ "GenSigTimeoutTime" BU_SG_REL_ DACU SG_ 866 TrafficSign05_MainSignConfidence 120;
BA_REL_ "GenSigFirstTimeoutTime" BU_SG_REL_ DACU SG_ 866 TrafficSign05_RestDay 3000;
BA_REL_ "GenSigTimeoutTime" BU_SG_REL_ DACU SG_ 866 TrafficSign05_RestDay 120;
BA_REL_ "GenSigFirstTimeoutTime" BU_SG_REL_ DACU SG_ 866 TrafficSign05_MainSignType 3000;
BA_REL_ "GenSigTimeoutTime" BU_SG_REL_ DACU SG_ 866 TrafficSign05_MainSignType 120;
BA_REL_ "GenSigFirstTimeoutTime" BU_SG_REL_ DACU SG_ 866 TrafficSign05_SupplSignType01 3000;
BA_REL_ "GenSigTimeoutTime" BU_SG_REL_ DACU SG_ 866 TrafficSign05_SupplSignType01 120;
BA_REL_ "GenSigFirstTimeoutTime" BU_SG_REL_ DACU SG_ 866 TrafficSign05_LongDist 3000;
BA_REL_ "GenSigTimeoutTime" BU_SG_REL_ DACU SG_ 866 TrafficSign05_LongDist 120;
BA_REL_ "GenSigFirstTimeoutTime" BU_SG_REL_ DACU SG_ 866 TrafficSign05_RestSection 3000;
BA_REL_ "GenSigTimeoutTime" BU_SG_REL_ DACU SG_ 866 TrafficSign05_RestSection 120;
BA_REL_ "GenSigFirstTimeoutTime" BU_SG_REL_ DACU SG_ 866 TrafficSign05_MainSignValue 3000;
BA_REL_ "GenSigTimeoutTime" BU_SG_REL_ DACU SG_ 866 TrafficSign05_MainSignValue 120;
BA_REL_ "GenSigFirstTimeoutTime" BU_SG_REL_ DACU SG_ 866 TrafficSign05_SupplSignValue01 3000;
BA_REL_ "GenSigTimeoutTime" BU_SG_REL_ DACU SG_ 866 TrafficSign05_SupplSignValue01 120;
BA_REL_ "GenSigFirstTimeoutTime" BU_SG_REL_ DACU SG_ 866 TrafficSign05_TimeStamp 3000;
BA_REL_ "GenSigTimeoutTime" BU_SG_REL_ DACU SG_ 866 TrafficSign05_TimeStamp 120;
BA_REL_ "GenSigFirstTimeoutTime" BU_SG_REL_ DACU SG_ 866 TrafficSign05_Height 3000;
BA_REL_ "GenSigTimeoutTime" BU_SG_REL_ DACU SG_ 866 TrafficSign05_Height 120;
BA_REL_ "GenSigFirstTimeoutTime" BU_SG_REL_ DACU SG_ 866 TrafficSign05_SupplSign02Conf 3000;
BA_REL_ "GenSigTimeoutTime" BU_SG_REL_ DACU SG_ 866 TrafficSign05_SupplSign02Conf 120;
BA_REL_ "GenSigFirstTimeoutTime" BU_SG_REL_ DACU SG_ 866 TrafficSign05_SignStability 3000;
BA_REL_ "GenSigTimeoutTime" BU_SG_REL_ DACU SG_ 866 TrafficSign05_SignStability 120;
BA_REL_ "GenSigFirstTimeoutTime" BU_SG_REL_ DACU SG_ 866 TrafficSign05_SupplSignValue02 3000;
BA_REL_ "GenSigTimeoutTime" BU_SG_REL_ DACU SG_ 866 TrafficSign05_SupplSignValue02 120;
BA_REL_ "GenSigFirstTimeoutTime" BU_SG_REL_ DACU SG_ 866 TrafficSign05_TrackStatus 3000;
BA_REL_ "GenSigTimeoutTime" BU_SG_REL_ DACU SG_ 866 TrafficSign05_TrackStatus 120;
BA_REL_ "GenSigFirstTimeoutTime" BU_SG_REL_ DACU SG_ 866 TrafficSign05_LatDist 3000;
BA_REL_ "GenSigTimeoutTime" BU_SG_REL_ DACU SG_ 866 TrafficSign05_LatDist 120;
BA_REL_ "GenSigFirstTimeoutTime" BU_SG_REL_ DACU SG_ 866 TrafficSign05_RestHeight 3000;
BA_REL_ "GenSigTimeoutTime" BU_SG_REL_ DACU SG_ 866 TrafficSign05_RestHeight 120;
BA_REL_ "GenSigFirstTimeoutTime" BU_SG_REL_ DACU SG_ 866 TrafficSign05_RestTime1 3000;
BA_REL_ "GenSigTimeoutTime" BU_SG_REL_ DACU SG_ 866 TrafficSign05_RestTime1 120;
BA_REL_ "GenSigFirstTimeoutTime" BU_SG_REL_ DACU SG_ 866 TrafficSign05_RestWidth 3000;
BA_REL_ "GenSigTimeoutTime" BU_SG_REL_ DACU SG_ 866 TrafficSign05_RestWidth 120;
BA_REL_ "GenSigFirstTimeoutTime" BU_SG_REL_ DACU SG_ 866 TrafficSign05_RestTime3 3000;
BA_REL_ "GenSigTimeoutTime" BU_SG_REL_ DACU SG_ 866 TrafficSign05_RestTime3 120;
BA_REL_ "GenSigFirstTimeoutTime" BU_SG_REL_ DACU SG_ 866 TrafficSign05_RestDist 3000;
BA_REL_ "GenSigTimeoutTime" BU_SG_REL_ DACU SG_ 866 TrafficSign05_RestDist 120;
BA_REL_ "GenSigFirstTimeoutTime" BU_SG_REL_ DACU SG_ 866 TrafficSign05_RestTime2 3000;
BA_REL_ "GenSigTimeoutTime" BU_SG_REL_ DACU SG_ 866 TrafficSign05_RestTime2 120;
BA_REL_ "GenSigFirstTimeoutTime" BU_SG_REL_ DACU SG_ 866 TrafficSign05_RestTime0 3000;
BA_REL_ "GenSigTimeoutTime" BU_SG_REL_ DACU SG_ 866 TrafficSign05_RestTime0 120;
BA_REL_ "GenSigFirstTimeoutTime" BU_SG_REL_ DACU SG_ 866 TrafficSign05_SupplSign00Conf 3000;
BA_REL_ "GenSigTimeoutTime" BU_SG_REL_ DACU SG_ 866 TrafficSign05_SupplSign00Conf 120;
BA_REL_ "GenSigFirstTimeoutTime" BU_SG_REL_ DACU SG_ 866 TrafficSign05_SupplSignType02 3000;
BA_REL_ "GenSigTimeoutTime" BU_SG_REL_ DACU SG_ 866 TrafficSign05_SupplSignType02 120;
BA_REL_ "GenSigFirstTimeoutTime" BU_SG_REL_ DACU SG_ 866 TrafficSign05_SupplSign01Conf 3000;
BA_REL_ "GenSigTimeoutTime" BU_SG_REL_ DACU SG_ 866 TrafficSign05_SupplSign01Conf 120;
BA_REL_ "GenSigFirstTimeoutTime" BU_SG_REL_ DACU SG_ 866 TrafficSign05_RestWeight 3000;
BA_REL_ "GenSigTimeoutTime" BU_SG_REL_ DACU SG_ 866 TrafficSign05_RestWeight 120;
BA_REL_ "GenSigFirstTimeoutTime" BU_SG_REL_ DACU SG_ 865 TrafficSign04_TrackStatus 3000;
BA_REL_ "GenSigTimeoutTime" BU_SG_REL_ DACU SG_ 865 TrafficSign04_TrackStatus 120;
BA_REL_ "GenSigFirstTimeoutTime" BU_SG_REL_ DACU SG_ 865 TrafficSign04_MainSignType 3000;
BA_REL_ "GenSigTimeoutTime" BU_SG_REL_ DACU SG_ 865 TrafficSign04_MainSignType 120;
BA_REL_ "GenSigFirstTimeoutTime" BU_SG_REL_ DACU SG_ 865 TrafficSign04_SupplSignValue00 3000;
BA_REL_ "GenSigTimeoutTime" BU_SG_REL_ DACU SG_ 865 TrafficSign04_SupplSignValue00 120;
BA_REL_ "GenSigFirstTimeoutTime" BU_SG_REL_ DACU SG_ 865 TrafficSign04_RestTime1 3000;
BA_REL_ "GenSigTimeoutTime" BU_SG_REL_ DACU SG_ 865 TrafficSign04_RestTime1 120;
BA_REL_ "GenSigFirstTimeoutTime" BU_SG_REL_ DACU SG_ 865 TrafficSign04_SupplSignValue01 3000;
BA_REL_ "GenSigTimeoutTime" BU_SG_REL_ DACU SG_ 865 TrafficSign04_SupplSignValue01 120;
BA_REL_ "GenSigFirstTimeoutTime" BU_SG_REL_ DACU SG_ 865 TrafficSign04_RestTime2 3000;
BA_REL_ "GenSigTimeoutTime" BU_SG_REL_ DACU SG_ 865 TrafficSign04_RestTime2 120;
BA_REL_ "GenSigFirstTimeoutTime" BU_SG_REL_ DACU SG_ 865 TrafficSign04_Height 3000;
BA_REL_ "GenSigTimeoutTime" BU_SG_REL_ DACU SG_ 865 TrafficSign04_Height 120;
BA_REL_ "GenSigFirstTimeoutTime" BU_SG_REL_ DACU SG_ 865 TrafficSign04_SupplSign00Conf 3000;
BA_REL_ "GenSigTimeoutTime" BU_SG_REL_ DACU SG_ 865 TrafficSign04_SupplSign00Conf 120;
BA_REL_ "GenSigFirstTimeoutTime" BU_SG_REL_ DACU SG_ 865 TrafficSign04_SupplSign01Conf 3000;
BA_REL_ "GenSigTimeoutTime" BU_SG_REL_ DACU SG_ 865 TrafficSign04_SupplSign01Conf 120;
BA_REL_ "GenSigFirstTimeoutTime" BU_SG_REL_ DACU SG_ 865 TrafficSign04_SupplSign02Conf 3000;
BA_REL_ "GenSigTimeoutTime" BU_SG_REL_ DACU SG_ 865 TrafficSign04_SupplSign02Conf 120;
BA_REL_ "GenSigFirstTimeoutTime" BU_SG_REL_ DACU SG_ 865 TrafficSign04_SupplSignType02 3000;
BA_REL_ "GenSigTimeoutTime" BU_SG_REL_ DACU SG_ 865 TrafficSign04_SupplSignType02 120;
BA_REL_ "GenSigFirstTimeoutTime" BU_SG_REL_ DACU SG_ 865 TrafficSign04_LongDist 3000;
BA_REL_ "GenSigTimeoutTime" BU_SG_REL_ DACU SG_ 865 TrafficSign04_LongDist 120;
BA_REL_ "GenSigFirstTimeoutTime" BU_SG_REL_ DACU SG_ 865 TrafficSign04_RestTime0 3000;
BA_REL_ "GenSigTimeoutTime" BU_SG_REL_ DACU SG_ 865 TrafficSign04_RestTime0 120;
BA_REL_ "GenSigFirstTimeoutTime" BU_SG_REL_ DACU SG_ 865 TrafficSign04_RestWidth 3000;
BA_REL_ "GenSigTimeoutTime" BU_SG_REL_ DACU SG_ 865 TrafficSign04_RestWidth 120;
BA_REL_ "GenSigFirstTimeoutTime" BU_SG_REL_ DACU SG_ 865 TrafficSign04_SupplSignType00 3000;
BA_REL_ "GenSigTimeoutTime" BU_SG_REL_ DACU SG_ 865 TrafficSign04_SupplSignType00 120;
BA_REL_ "GenSigFirstTimeoutTime" BU_SG_REL_ DACU SG_ 865 TrafficSign04_RestDay 3000;
BA_REL_ "GenSigTimeoutTime" BU_SG_REL_ DACU SG_ 865 TrafficSign04_RestDay 120;
BA_REL_ "GenSigFirstTimeoutTime" BU_SG_REL_ DACU SG_ 865 TrafficSign04_SupplSignType01 3000;
BA_REL_ "GenSigTimeoutTime" BU_SG_REL_ DACU SG_ 865 TrafficSign04_SupplSignType01 120;
BA_REL_ "GenSigFirstTimeoutTime" BU_SG_REL_ DACU SG_ 865 TrafficSign04_MainSignConfidence 3000;
BA_REL_ "GenSigTimeoutTime" BU_SG_REL_ DACU SG_ 865 TrafficSign04_MainSignConfidence 120;
BA_REL_ "GenSigFirstTimeoutTime" BU_SG_REL_ DACU SG_ 865 TrafficSign04_RestHeight 3000;
BA_REL_ "GenSigTimeoutTime" BU_SG_REL_ DACU SG_ 865 TrafficSign04_RestHeight 120;
BA_REL_ "GenSigFirstTimeoutTime" BU_SG_REL_ DACU SG_ 865 TrafficSign04_MainSignValue 3000;
BA_REL_ "GenSigTimeoutTime" BU_SG_REL_ DACU SG_ 865 TrafficSign04_MainSignValue 120;
BA_REL_ "GenSigFirstTimeoutTime" BU_SG_REL_ DACU SG_ 865 TrafficSign04_RestSection 3000;
BA_REL_ "GenSigTimeoutTime" BU_SG_REL_ DACU SG_ 865 TrafficSign04_RestSection 120;
BA_REL_ "GenSigFirstTimeoutTime" BU_SG_REL_ DACU SG_ 865 TrafficSign04_RestDist 3000;
BA_REL_ "GenSigTimeoutTime" BU_SG_REL_ DACU SG_ 865 TrafficSign04_RestDist 120;
BA_REL_ "GenSigFirstTimeoutTime" BU_SG_REL_ DACU SG_ 865 TrafficSign04_ID 3000;
BA_REL_ "GenSigTimeoutTime" BU_SG_REL_ DACU SG_ 865 TrafficSign04_ID 120;
BA_REL_ "GenSigFirstTimeoutTime" BU_SG_REL_ DACU SG_ 865 TrafficSign04_RestTime3 3000;
BA_REL_ "GenSigTimeoutTime" BU_SG_REL_ DACU SG_ 865 TrafficSign04_RestTime3 120;
BA_REL_ "GenSigFirstTimeoutTime" BU_SG_REL_ DACU SG_ 865 TrafficSign04_SignStability 3000;
BA_REL_ "GenSigTimeoutTime" BU_SG_REL_ DACU SG_ 865 TrafficSign04_SignStability 120;
BA_REL_ "GenSigFirstTimeoutTime" BU_SG_REL_ DACU SG_ 865 TrafficSign04_LatDist 3000;
BA_REL_ "GenSigTimeoutTime" BU_SG_REL_ DACU SG_ 865 TrafficSign04_LatDist 120;
BA_REL_ "GenSigFirstTimeoutTime" BU_SG_REL_ DACU SG_ 865 TrafficSign04_TimeStamp 3000;
BA_REL_ "GenSigTimeoutTime" BU_SG_REL_ DACU SG_ 865 TrafficSign04_TimeStamp 120;
BA_REL_ "GenSigFirstTimeoutTime" BU_SG_REL_ DACU SG_ 865 TrafficSign04_SupplSignValue02 3000;
BA_REL_ "GenSigTimeoutTime" BU_SG_REL_ DACU SG_ 865 TrafficSign04_SupplSignValue02 120;
BA_REL_ "GenSigFirstTimeoutTime" BU_SG_REL_ DACU SG_ 865 TrafficSign04_RestWeight 3000;
BA_REL_ "GenSigTimeoutTime" BU_SG_REL_ DACU SG_ 865 TrafficSign04_RestWeight 120;
BA_REL_ "GenSigFirstTimeoutTime" BU_SG_REL_ DACU SG_ 849 TrafficSign03_Height 3000;
BA_REL_ "GenSigTimeoutTime" BU_SG_REL_ DACU SG_ 849 TrafficSign03_Height 120;
BA_REL_ "GenSigFirstTimeoutTime" BU_SG_REL_ DACU SG_ 849 TrafficSign03_ID 3000;
BA_REL_ "GenSigTimeoutTime" BU_SG_REL_ DACU SG_ 849 TrafficSign03_ID 120;
BA_REL_ "GenSigFirstTimeoutTime" BU_SG_REL_ DACU SG_ 849 TrafficSign03_TrackStatus 3000;
BA_REL_ "GenSigTimeoutTime" BU_SG_REL_ DACU SG_ 849 TrafficSign03_TrackStatus 120;
BA_REL_ "GenSigFirstTimeoutTime" BU_SG_REL_ DACU SG_ 849 TrafficSign03_RestHeight 3000;
BA_REL_ "GenSigTimeoutTime" BU_SG_REL_ DACU SG_ 849 TrafficSign03_RestHeight 120;
BA_REL_ "GenSigFirstTimeoutTime" BU_SG_REL_ DACU SG_ 849 TrafficSign03_MainSignConfidence 3000;
BA_REL_ "GenSigTimeoutTime" BU_SG_REL_ DACU SG_ 849 TrafficSign03_MainSignConfidence 120;
BA_REL_ "GenSigFirstTimeoutTime" BU_SG_REL_ DACU SG_ 849 TrafficSign03_RestDay 3000;
BA_REL_ "GenSigTimeoutTime" BU_SG_REL_ DACU SG_ 849 TrafficSign03_RestDay 120;
BA_REL_ "GenSigFirstTimeoutTime" BU_SG_REL_ DACU SG_ 849 TrafficSign03_LongDist 3000;
BA_REL_ "GenSigTimeoutTime" BU_SG_REL_ DACU SG_ 849 TrafficSign03_LongDist 120;
BA_REL_ "GenSigFirstTimeoutTime" BU_SG_REL_ DACU SG_ 849 TrafficSign03_RestTime3 3000;
BA_REL_ "GenSigTimeoutTime" BU_SG_REL_ DACU SG_ 849 TrafficSign03_RestTime3 120;
BA_REL_ "GenSigFirstTimeoutTime" BU_SG_REL_ DACU SG_ 849 TrafficSign03_SupplSignType00 3000;
BA_REL_ "GenSigTimeoutTime" BU_SG_REL_ DACU SG_ 849 TrafficSign03_SupplSignType00 120;
BA_REL_ "GenSigFirstTimeoutTime" BU_SG_REL_ DACU SG_ 849 TrafficSign03_RestTime1 3000;
BA_REL_ "GenSigTimeoutTime" BU_SG_REL_ DACU SG_ 849 TrafficSign03_RestTime1 120;
BA_REL_ "GenSigFirstTimeoutTime" BU_SG_REL_ DACU SG_ 849 TrafficSign03_SupplSignValue00 3000;
BA_REL_ "GenSigTimeoutTime" BU_SG_REL_ DACU SG_ 849 TrafficSign03_SupplSignValue00 120;
BA_REL_ "GenSigFirstTimeoutTime" BU_SG_REL_ DACU SG_ 849 TrafficSign03_RestTime0 3000;
BA_REL_ "GenSigTimeoutTime" BU_SG_REL_ DACU SG_ 849 TrafficSign03_RestTime0 120;
BA_REL_ "GenSigFirstTimeoutTime" BU_SG_REL_ DACU SG_ 849 TrafficSign03_SupplSignType02 3000;
BA_REL_ "GenSigTimeoutTime" BU_SG_REL_ DACU SG_ 849 TrafficSign03_SupplSignType02 120;
BA_REL_ "GenSigFirstTimeoutTime" BU_SG_REL_ DACU SG_ 849 TrafficSign03_RestWidth 3000;
BA_REL_ "GenSigTimeoutTime" BU_SG_REL_ DACU SG_ 849 TrafficSign03_RestWidth 120;
BA_REL_ "GenSigFirstTimeoutTime" BU_SG_REL_ DACU SG_ 849 TrafficSign03_MainSignValue 3000;
BA_REL_ "GenSigTimeoutTime" BU_SG_REL_ DACU SG_ 849 TrafficSign03_MainSignValue 120;
BA_REL_ "GenSigFirstTimeoutTime" BU_SG_REL_ DACU SG_ 849 TrafficSign03_RestTime2 3000;
BA_REL_ "GenSigTimeoutTime" BU_SG_REL_ DACU SG_ 849 TrafficSign03_RestTime2 120;
BA_REL_ "GenSigFirstTimeoutTime" BU_SG_REL_ DACU SG_ 849 TrafficSign03_SupplSign01Conf 3000;
BA_REL_ "GenSigTimeoutTime" BU_SG_REL_ DACU SG_ 849 TrafficSign03_SupplSign01Conf 120;
BA_REL_ "GenSigFirstTimeoutTime" BU_SG_REL_ DACU SG_ 849 TrafficSign03_LatDist 3000;
BA_REL_ "GenSigTimeoutTime" BU_SG_REL_ DACU SG_ 849 TrafficSign03_LatDist 120;
BA_REL_ "GenSigFirstTimeoutTime" BU_SG_REL_ DACU SG_ 849 TrafficSign03_RestWeight 3000;
BA_REL_ "GenSigTimeoutTime" BU_SG_REL_ DACU SG_ 849 TrafficSign03_RestWeight 120;
BA_REL_ "GenSigFirstTimeoutTime" BU_SG_REL_ DACU SG_ 849 TrafficSign03_TimeStamp 3000;
BA_REL_ "GenSigTimeoutTime" BU_SG_REL_ DACU SG_ 849 TrafficSign03_TimeStamp 120;
BA_REL_ "GenSigFirstTimeoutTime" BU_SG_REL_ DACU SG_ 849 TrafficSign03_RestDist 3000;
BA_REL_ "GenSigTimeoutTime" BU_SG_REL_ DACU SG_ 849 TrafficSign03_RestDist 120;
BA_REL_ "GenSigFirstTimeoutTime" BU_SG_REL_ DACU SG_ 849 TrafficSign03_SupplSign00Conf 3000;
BA_REL_ "GenSigTimeoutTime" BU_SG_REL_ DACU SG_ 849 TrafficSign03_SupplSign00Conf 120;
BA_REL_ "GenSigFirstTimeoutTime" BU_SG_REL_ DACU SG_ 849 TrafficSign03_SupplSignType01 3000;
BA_REL_ "GenSigTimeoutTime" BU_SG_REL_ DACU SG_ 849 TrafficSign03_SupplSignType01 120;
BA_REL_ "GenSigFirstTimeoutTime" BU_SG_REL_ DACU SG_ 849 TrafficSign03_SupplSign02Conf 3000;
BA_REL_ "GenSigTimeoutTime" BU_SG_REL_ DACU SG_ 849 TrafficSign03_SupplSign02Conf 120;
BA_REL_ "GenSigFirstTimeoutTime" BU_SG_REL_ DACU SG_ 849 TrafficSign03_RestSection 3000;
BA_REL_ "GenSigTimeoutTime" BU_SG_REL_ DACU SG_ 849 TrafficSign03_RestSection 120;
BA_REL_ "GenSigFirstTimeoutTime" BU_SG_REL_ DACU SG_ 849 TrafficSign03_SupplSignValue02 3000;
BA_REL_ "GenSigTimeoutTime" BU_SG_REL_ DACU SG_ 849 TrafficSign03_SupplSignValue02 120;
BA_REL_ "GenSigFirstTimeoutTime" BU_SG_REL_ DACU SG_ 849 TrafficSign03_MainSignType 3000;
BA_REL_ "GenSigTimeoutTime" BU_SG_REL_ DACU SG_ 849 TrafficSign03_MainSignType 120;
BA_REL_ "GenSigFirstTimeoutTime" BU_SG_REL_ DACU SG_ 849 TrafficSign03_SignStability 3000;
BA_REL_ "GenSigTimeoutTime" BU_SG_REL_ DACU SG_ 849 TrafficSign03_SignStability 120;
BA_REL_ "GenSigFirstTimeoutTime" BU_SG_REL_ DACU SG_ 849 TrafficSign03_SupplSignValue01 3000;
BA_REL_ "GenSigTimeoutTime" BU_SG_REL_ DACU SG_ 849 TrafficSign03_SupplSignValue01 120;
BA_REL_ "GenSigFirstTimeoutTime" BU_SG_REL_ DACU SG_ 848 TrafficSign02_RestTime1 3000;
BA_REL_ "GenSigTimeoutTime" BU_SG_REL_ DACU SG_ 848 TrafficSign02_RestTime1 120;
BA_REL_ "GenSigFirstTimeoutTime" BU_SG_REL_ DACU SG_ 848 TrafficSign02_RestHeight 3000;
BA_REL_ "GenSigTimeoutTime" BU_SG_REL_ DACU SG_ 848 TrafficSign02_RestHeight 120;
BA_REL_ "GenSigFirstTimeoutTime" BU_SG_REL_ DACU SG_ 848 TrafficSign02_Height 3000;
BA_REL_ "GenSigTimeoutTime" BU_SG_REL_ DACU SG_ 848 TrafficSign02_Height 120;
BA_REL_ "GenSigFirstTimeoutTime" BU_SG_REL_ DACU SG_ 848 TrafficSign02_SignStability 3000;
BA_REL_ "GenSigTimeoutTime" BU_SG_REL_ DACU SG_ 848 TrafficSign02_SignStability 120;
BA_REL_ "GenSigFirstTimeoutTime" BU_SG_REL_ DACU SG_ 848 TrafficSign02_SupplSignType00 3000;
BA_REL_ "GenSigTimeoutTime" BU_SG_REL_ DACU SG_ 848 TrafficSign02_SupplSignType00 120;
BA_REL_ "GenSigFirstTimeoutTime" BU_SG_REL_ DACU SG_ 848 TrafficSign02_ID 3000;
BA_REL_ "GenSigTimeoutTime" BU_SG_REL_ DACU SG_ 848 TrafficSign02_ID 120;
BA_REL_ "GenSigFirstTimeoutTime" BU_SG_REL_ DACU SG_ 848 TrafficSign02_LatDist 3000;
BA_REL_ "GenSigTimeoutTime" BU_SG_REL_ DACU SG_ 848 TrafficSign02_LatDist 120;
BA_REL_ "GenSigFirstTimeoutTime" BU_SG_REL_ DACU SG_ 848 TrafficSign02_MainSignType 3000;
BA_REL_ "GenSigTimeoutTime" BU_SG_REL_ DACU SG_ 848 TrafficSign02_MainSignType 120;
BA_REL_ "GenSigFirstTimeoutTime" BU_SG_REL_ DACU SG_ 848 TrafficSign02_SupplSignValue01 3000;
BA_REL_ "GenSigTimeoutTime" BU_SG_REL_ DACU SG_ 848 TrafficSign02_SupplSignValue01 120;
BA_REL_ "GenSigFirstTimeoutTime" BU_SG_REL_ DACU SG_ 848 TrafficSign02_SupplSign00Conf 3000;
BA_REL_ "GenSigTimeoutTime" BU_SG_REL_ DACU SG_ 848 TrafficSign02_SupplSign00Conf 120;
BA_REL_ "GenSigFirstTimeoutTime" BU_SG_REL_ DACU SG_ 848 TrafficSign02_SupplSignType01 3000;
BA_REL_ "GenSigTimeoutTime" BU_SG_REL_ DACU SG_ 848 TrafficSign02_SupplSignType01 120;
BA_REL_ "GenSigFirstTimeoutTime" BU_SG_REL_ DACU SG_ 848 TrafficSign02_RestTime2 3000;
BA_REL_ "GenSigTimeoutTime" BU_SG_REL_ DACU SG_ 848 TrafficSign02_RestTime2 120;
BA_REL_ "GenSigFirstTimeoutTime" BU_SG_REL_ DACU SG_ 848 TrafficSign02_MainSignConfidence 3000;
BA_REL_ "GenSigTimeoutTime" BU_SG_REL_ DACU SG_ 848 TrafficSign02_MainSignConfidence 120;
BA_REL_ "GenSigFirstTimeoutTime" BU_SG_REL_ DACU SG_ 848 TrafficSign02_SupplSignValue02 3000;
BA_REL_ "GenSigTimeoutTime" BU_SG_REL_ DACU SG_ 848 TrafficSign02_SupplSignValue02 120;
BA_REL_ "GenSigFirstTimeoutTime" BU_SG_REL_ DACU SG_ 848 TrafficSign02_TimeStamp 3000;
BA_REL_ "GenSigTimeoutTime" BU_SG_REL_ DACU SG_ 848 TrafficSign02_TimeStamp 120;
BA_REL_ "GenSigFirstTimeoutTime" BU_SG_REL_ DACU SG_ 848 TrafficSign02_RestSection 3000;
BA_REL_ "GenSigTimeoutTime" BU_SG_REL_ DACU SG_ 848 TrafficSign02_RestSection 120;
BA_REL_ "GenSigFirstTimeoutTime" BU_SG_REL_ DACU SG_ 848 TrafficSign02_RestDist 3000;
BA_REL_ "GenSigTimeoutTime" BU_SG_REL_ DACU SG_ 848 TrafficSign02_RestDist 120;
BA_REL_ "GenSigFirstTimeoutTime" BU_SG_REL_ DACU SG_ 848 TrafficSign02_RestDay 3000;
BA_REL_ "GenSigTimeoutTime" BU_SG_REL_ DACU SG_ 848 TrafficSign02_RestDay 120;
BA_REL_ "GenSigFirstTimeoutTime" BU_SG_REL_ DACU SG_ 848 TrafficSign02_SupplSign02Conf 3000;
BA_REL_ "GenSigTimeoutTime" BU_SG_REL_ DACU SG_ 848 TrafficSign02_SupplSign02Conf 120;
BA_REL_ "GenSigFirstTimeoutTime" BU_SG_REL_ DACU SG_ 848 TrafficSign02_SupplSign01Conf 3000;
BA_REL_ "GenSigTimeoutTime" BU_SG_REL_ DACU SG_ 848 TrafficSign02_SupplSign01Conf 120;
BA_REL_ "GenSigFirstTimeoutTime" BU_SG_REL_ DACU SG_ 848 TrafficSign02_LongDist 3000;
BA_REL_ "GenSigTimeoutTime" BU_SG_REL_ DACU SG_ 848 TrafficSign02_LongDist 120;
BA_REL_ "GenSigFirstTimeoutTime" BU_SG_REL_ DACU SG_ 848 TrafficSign02_MainSignValue 3000;
BA_REL_ "GenSigTimeoutTime" BU_SG_REL_ DACU SG_ 848 TrafficSign02_MainSignValue 120;
BA_REL_ "GenSigFirstTimeoutTime" BU_SG_REL_ DACU SG_ 848 TrafficSign02_TrackStatus 3000;
BA_REL_ "GenSigTimeoutTime" BU_SG_REL_ DACU SG_ 848 TrafficSign02_TrackStatus 120;
BA_REL_ "GenSigFirstTimeoutTime" BU_SG_REL_ DACU SG_ 848 TrafficSign02_SupplSignType02 3000;
BA_REL_ "GenSigTimeoutTime" BU_SG_REL_ DACU SG_ 848 TrafficSign02_SupplSignType02 120;
BA_REL_ "GenSigFirstTimeoutTime" BU_SG_REL_ DACU SG_ 848 TrafficSign02_RestWeight 3000;
BA_REL_ "GenSigTimeoutTime" BU_SG_REL_ DACU SG_ 848 TrafficSign02_RestWeight 120;
BA_REL_ "GenSigFirstTimeoutTime" BU_SG_REL_ DACU SG_ 848 TrafficSign02_RestTime0 3000;
BA_REL_ "GenSigTimeoutTime" BU_SG_REL_ DACU SG_ 848 TrafficSign02_RestTime0 120;
BA_REL_ "GenSigFirstTimeoutTime" BU_SG_REL_ DACU SG_ 848 TrafficSign02_SupplSignValue00 3000;
BA_REL_ "GenSigTimeoutTime" BU_SG_REL_ DACU SG_ 848 TrafficSign02_SupplSignValue00 120;
BA_REL_ "GenSigFirstTimeoutTime" BU_SG_REL_ DACU SG_ 848 TrafficSign02_RestWidth 3000;
BA_REL_ "GenSigTimeoutTime" BU_SG_REL_ DACU SG_ 848 TrafficSign02_RestWidth 120;
BA_REL_ "GenSigFirstTimeoutTime" BU_SG_REL_ DACU SG_ 848 TrafficSign02_RestTime3 3000;
BA_REL_ "GenSigTimeoutTime" BU_SG_REL_ DACU SG_ 848 TrafficSign02_RestTime3 120;
BA_REL_ "GenSigFirstTimeoutTime" BU_SG_REL_ DACU SG_ 841 TrafficSign01_SupplSign02Conf 3000;
BA_REL_ "GenSigTimeoutTime" BU_SG_REL_ DACU SG_ 841 TrafficSign01_SupplSign02Conf 120;
BA_REL_ "GenSigFirstTimeoutTime" BU_SG_REL_ DACU SG_ 841 TrafficSign01_RestTime0 3000;
BA_REL_ "GenSigTimeoutTime" BU_SG_REL_ DACU SG_ 841 TrafficSign01_RestTime0 120;
BA_REL_ "GenSigFirstTimeoutTime" BU_SG_REL_ DACU SG_ 841 TrafficSign01_RestTime1 3000;
BA_REL_ "GenSigTimeoutTime" BU_SG_REL_ DACU SG_ 841 TrafficSign01_RestTime1 120;
BA_REL_ "GenSigFirstTimeoutTime" BU_SG_REL_ DACU SG_ 841 TrafficSign01_RestTime3 3000;
BA_REL_ "GenSigTimeoutTime" BU_SG_REL_ DACU SG_ 841 TrafficSign01_RestTime3 120;
BA_REL_ "GenSigFirstTimeoutTime" BU_SG_REL_ DACU SG_ 841 TrafficSign01_RestDay 3000;
BA_REL_ "GenSigTimeoutTime" BU_SG_REL_ DACU SG_ 841 TrafficSign01_RestDay 120;
BA_REL_ "GenSigFirstTimeoutTime" BU_SG_REL_ DACU SG_ 841 TrafficSign01_ID 3000;
BA_REL_ "GenSigTimeoutTime" BU_SG_REL_ DACU SG_ 841 TrafficSign01_ID 120;
BA_REL_ "GenSigFirstTimeoutTime" BU_SG_REL_ DACU SG_ 841 TrafficSign01_MainSignValue 3000;
BA_REL_ "GenSigTimeoutTime" BU_SG_REL_ DACU SG_ 841 TrafficSign01_MainSignValue 120;
BA_REL_ "GenSigFirstTimeoutTime" BU_SG_REL_ DACU SG_ 841 TrafficSign01_MainSignType 3000;
BA_REL_ "GenSigTimeoutTime" BU_SG_REL_ DACU SG_ 841 TrafficSign01_MainSignType 120;
BA_REL_ "GenSigFirstTimeoutTime" BU_SG_REL_ DACU SG_ 841 TrafficSign01_LatDist 3000;
BA_REL_ "GenSigTimeoutTime" BU_SG_REL_ DACU SG_ 841 TrafficSign01_LatDist 120;
BA_REL_ "GenSigFirstTimeoutTime" BU_SG_REL_ DACU SG_ 841 TrafficSign01_RestWidth 3000;
BA_REL_ "GenSigTimeoutTime" BU_SG_REL_ DACU SG_ 841 TrafficSign01_RestWidth 120;
BA_REL_ "GenSigFirstTimeoutTime" BU_SG_REL_ DACU SG_ 841 TrafficSign01_RestWeight 3000;
BA_REL_ "GenSigTimeoutTime" BU_SG_REL_ DACU SG_ 841 TrafficSign01_RestWeight 120;
BA_REL_ "GenSigFirstTimeoutTime" BU_SG_REL_ DACU SG_ 841 TrafficSign01_SupplSignType01 3000;
BA_REL_ "GenSigTimeoutTime" BU_SG_REL_ DACU SG_ 841 TrafficSign01_SupplSignType01 120;
BA_REL_ "GenSigFirstTimeoutTime" BU_SG_REL_ DACU SG_ 841 TrafficSign01_SupplSignValue02 3000;
BA_REL_ "GenSigTimeoutTime" BU_SG_REL_ DACU SG_ 841 TrafficSign01_SupplSignValue02 120;
BA_REL_ "GenSigFirstTimeoutTime" BU_SG_REL_ DACU SG_ 841 TrafficSign01_SupplSignValue00 3000;
BA_REL_ "GenSigTimeoutTime" BU_SG_REL_ DACU SG_ 841 TrafficSign01_SupplSignValue00 120;
BA_REL_ "GenSigFirstTimeoutTime" BU_SG_REL_ DACU SG_ 841 TrafficSign01_TimeStamp 3000;
BA_REL_ "GenSigTimeoutTime" BU_SG_REL_ DACU SG_ 841 TrafficSign01_TimeStamp 120;
BA_REL_ "GenSigFirstTimeoutTime" BU_SG_REL_ DACU SG_ 841 TrafficSign01_SignStability 3000;
BA_REL_ "GenSigTimeoutTime" BU_SG_REL_ DACU SG_ 841 TrafficSign01_SignStability 120;
BA_REL_ "GenSigFirstTimeoutTime" BU_SG_REL_ DACU SG_ 841 TrafficSign01_RestTime2 3000;
BA_REL_ "GenSigTimeoutTime" BU_SG_REL_ DACU SG_ 841 TrafficSign01_RestTime2 120;
BA_REL_ "GenSigFirstTimeoutTime" BU_SG_REL_ DACU SG_ 841 TrafficSign01_SupplSign00Conf 3000;
BA_REL_ "GenSigTimeoutTime" BU_SG_REL_ DACU SG_ 841 TrafficSign01_SupplSign00Conf 120;
BA_REL_ "GenSigFirstTimeoutTime" BU_SG_REL_ DACU SG_ 841 TrafficSign01_SupplSignType02 3000;
BA_REL_ "GenSigTimeoutTime" BU_SG_REL_ DACU SG_ 841 TrafficSign01_SupplSignType02 120;
BA_REL_ "GenSigFirstTimeoutTime" BU_SG_REL_ DACU SG_ 841 TrafficSign01_TrackStatus 3000;
BA_REL_ "GenSigTimeoutTime" BU_SG_REL_ DACU SG_ 841 TrafficSign01_TrackStatus 120;
BA_REL_ "GenSigFirstTimeoutTime" BU_SG_REL_ DACU SG_ 841 TrafficSign01_SupplSign01Conf 3000;
BA_REL_ "GenSigTimeoutTime" BU_SG_REL_ DACU SG_ 841 TrafficSign01_SupplSign01Conf 120;
BA_REL_ "GenSigFirstTimeoutTime" BU_SG_REL_ DACU SG_ 841 TrafficSign01_LongDist 3000;
BA_REL_ "GenSigTimeoutTime" BU_SG_REL_ DACU SG_ 841 TrafficSign01_LongDist 120;
BA_REL_ "GenSigFirstTimeoutTime" BU_SG_REL_ DACU SG_ 841 TrafficSign01_Height 3000;
BA_REL_ "GenSigTimeoutTime" BU_SG_REL_ DACU SG_ 841 TrafficSign01_Height 120;
BA_REL_ "GenSigFirstTimeoutTime" BU_SG_REL_ DACU SG_ 841 TrafficSign01_SupplSignType00 3000;
BA_REL_ "GenSigTimeoutTime" BU_SG_REL_ DACU SG_ 841 TrafficSign01_SupplSignType00 120;
BA_REL_ "GenSigFirstTimeoutTime" BU_SG_REL_ DACU SG_ 841 TrafficSign01_RestSection 3000;
BA_REL_ "GenSigTimeoutTime" BU_SG_REL_ DACU SG_ 841 TrafficSign01_RestSection 120;
BA_REL_ "GenSigFirstTimeoutTime" BU_SG_REL_ DACU SG_ 841 TrafficSign01_MainSignConfidence 3000;
BA_REL_ "GenSigTimeoutTime" BU_SG_REL_ DACU SG_ 841 TrafficSign01_MainSignConfidence 120;
BA_REL_ "GenSigFirstTimeoutTime" BU_SG_REL_ DACU SG_ 841 TrafficSign01_RestDist 3000;
BA_REL_ "GenSigTimeoutTime" BU_SG_REL_ DACU SG_ 841 TrafficSign01_RestDist 120;
BA_REL_ "GenSigFirstTimeoutTime" BU_SG_REL_ DACU SG_ 841 TrafficSign01_RestHeight 3000;
BA_REL_ "GenSigTimeoutTime" BU_SG_REL_ DACU SG_ 841 TrafficSign01_RestHeight 120;
BA_REL_ "GenSigFirstTimeoutTime" BU_SG_REL_ DACU SG_ 841 TrafficSign01_SupplSignValue01 3000;
BA_REL_ "GenSigTimeoutTime" BU_SG_REL_ DACU SG_ 841 TrafficSign01_SupplSignValue01 120;
BA_REL_ "GenSigFirstTimeoutTime" BU_SG_REL_ DACU SG_ 840 TrafficSign00_RestWidth 3000;
BA_REL_ "GenSigTimeoutTime" BU_SG_REL_ DACU SG_ 840 TrafficSign00_RestWidth 120;
BA_REL_ "GenSigFirstTimeoutTime" BU_SG_REL_ DACU SG_ 840 TrafficSign00_RestTime3 3000;
BA_REL_ "GenSigTimeoutTime" BU_SG_REL_ DACU SG_ 840 TrafficSign00_RestTime3 120;
BA_REL_ "GenSigFirstTimeoutTime" BU_SG_REL_ DACU SG_ 840 TrafficSign00_RestSection 3000;
BA_REL_ "GenSigTimeoutTime" BU_SG_REL_ DACU SG_ 840 TrafficSign00_RestSection 120;
BA_REL_ "GenSigFirstTimeoutTime" BU_SG_REL_ DACU SG_ 840 TrafficSign00_SupplSignValue01 3000;
BA_REL_ "GenSigTimeoutTime" BU_SG_REL_ DACU SG_ 840 TrafficSign00_SupplSignValue01 120;
BA_REL_ "GenSigFirstTimeoutTime" BU_SG_REL_ DACU SG_ 840 TrafficSign00_SupplSignValue00 3000;
BA_REL_ "GenSigTimeoutTime" BU_SG_REL_ DACU SG_ 840 TrafficSign00_SupplSignValue00 120;
BA_REL_ "GenSigFirstTimeoutTime" BU_SG_REL_ DACU SG_ 840 TrafficSign00_SupplSign02Conf 3000;
BA_REL_ "GenSigTimeoutTime" BU_SG_REL_ DACU SG_ 840 TrafficSign00_SupplSign02Conf 120;
BA_REL_ "GenSigFirstTimeoutTime" BU_SG_REL_ DACU SG_ 840 TrafficSign00_ID 3000;
BA_REL_ "GenSigTimeoutTime" BU_SG_REL_ DACU SG_ 840 TrafficSign00_ID 120;
BA_REL_ "GenSigFirstTimeoutTime" BU_SG_REL_ DACU SG_ 840 TrafficSign00_SupplSign01Conf 3000;
BA_REL_ "GenSigTimeoutTime" BU_SG_REL_ DACU SG_ 840 TrafficSign00_SupplSign01Conf 120;
BA_REL_ "GenSigFirstTimeoutTime" BU_SG_REL_ DACU SG_ 840 TrafficSign00_SupplSignType01 3000;
BA_REL_ "GenSigTimeoutTime" BU_SG_REL_ DACU SG_ 840 TrafficSign00_SupplSignType01 120;
BA_REL_ "GenSigFirstTimeoutTime" BU_SG_REL_ DACU SG_ 840 TrafficSign00_SupplSignType00 3000;
BA_REL_ "GenSigTimeoutTime" BU_SG_REL_ DACU SG_ 840 TrafficSign00_SupplSignType00 120;
BA_REL_ "GenSigFirstTimeoutTime" BU_SG_REL_ DACU SG_ 840 TrafficSign00_LongDist 3000;
BA_REL_ "GenSigTimeoutTime" BU_SG_REL_ DACU SG_ 840 TrafficSign00_LongDist 120;
BA_REL_ "GenSigFirstTimeoutTime" BU_SG_REL_ DACU SG_ 840 TrafficSign00_RestDay 3000;
BA_REL_ "GenSigTimeoutTime" BU_SG_REL_ DACU SG_ 840 TrafficSign00_RestDay 120;
BA_REL_ "GenSigFirstTimeoutTime" BU_SG_REL_ DACU SG_ 840 TrafficSign00_MainSignConfidence 3000;
BA_REL_ "GenSigTimeoutTime" BU_SG_REL_ DACU SG_ 840 TrafficSign00_MainSignConfidence 120;
BA_REL_ "GenSigFirstTimeoutTime" BU_SG_REL_ DACU SG_ 840 TrafficSign00_MainSignValue 3000;
BA_REL_ "GenSigTimeoutTime" BU_SG_REL_ DACU SG_ 840 TrafficSign00_MainSignValue 120;
BA_REL_ "GenSigFirstTimeoutTime" BU_SG_REL_ DACU SG_ 840 TrafficSign00_Height 3000;
BA_REL_ "GenSigTimeoutTime" BU_SG_REL_ DACU SG_ 840 TrafficSign00_Height 120;
BA_REL_ "GenSigFirstTimeoutTime" BU_SG_REL_ DACU SG_ 840 TrafficSign00_SupplSignType02 3000;
BA_REL_ "GenSigTimeoutTime" BU_SG_REL_ DACU SG_ 840 TrafficSign00_SupplSignType02 120;
BA_REL_ "GenSigFirstTimeoutTime" BU_SG_REL_ DACU SG_ 840 TrafficSign00_RestTime1 3000;
BA_REL_ "GenSigTimeoutTime" BU_SG_REL_ DACU SG_ 840 TrafficSign00_RestTime1 120;
BA_REL_ "GenSigFirstTimeoutTime" BU_SG_REL_ DACU SG_ 840 TrafficSign00_RestHeight 3000;
BA_REL_ "GenSigTimeoutTime" BU_SG_REL_ DACU SG_ 840 TrafficSign00_RestHeight 120;
BA_REL_ "GenSigFirstTimeoutTime" BU_SG_REL_ DACU SG_ 840 TrafficSign00_RestTime2 3000;
BA_REL_ "GenSigTimeoutTime" BU_SG_REL_ DACU SG_ 840 TrafficSign00_RestTime2 120;
BA_REL_ "GenSigFirstTimeoutTime" BU_SG_REL_ DACU SG_ 840 TrafficSign00_RestTime0 3000;
BA_REL_ "GenSigTimeoutTime" BU_SG_REL_ DACU SG_ 840 TrafficSign00_RestTime0 120;
BA_REL_ "GenSigFirstTimeoutTime" BU_SG_REL_ DACU SG_ 840 TrafficSign00_TrackStatus 3000;
BA_REL_ "GenSigTimeoutTime" BU_SG_REL_ DACU SG_ 840 TrafficSign00_TrackStatus 120;
BA_REL_ "GenSigFirstTimeoutTime" BU_SG_REL_ DACU SG_ 840 TrafficSign00_RestDist 3000;
BA_REL_ "GenSigTimeoutTime" BU_SG_REL_ DACU SG_ 840 TrafficSign00_RestDist 120;
BA_REL_ "GenSigFirstTimeoutTime" BU_SG_REL_ DACU SG_ 840 TrafficSign00_MainSignType 3000;
BA_REL_ "GenSigTimeoutTime" BU_SG_REL_ DACU SG_ 840 TrafficSign00_MainSignType 120;
BA_REL_ "GenSigFirstTimeoutTime" BU_SG_REL_ DACU SG_ 840 TrafficSign00_SignStability 3000;
BA_REL_ "GenSigTimeoutTime" BU_SG_REL_ DACU SG_ 840 TrafficSign00_SignStability 120;
BA_REL_ "GenSigFirstTimeoutTime" BU_SG_REL_ DACU SG_ 840 TrafficSign00_SupplSignValue02 3000;
BA_REL_ "GenSigTimeoutTime" BU_SG_REL_ DACU SG_ 840 TrafficSign00_SupplSignValue02 120;
BA_REL_ "GenSigFirstTimeoutTime" BU_SG_REL_ DACU SG_ 840 TrafficSign00_LatDist 3000;
BA_REL_ "GenSigTimeoutTime" BU_SG_REL_ DACU SG_ 840 TrafficSign00_LatDist 120;
BA_REL_ "GenSigFirstTimeoutTime" BU_SG_REL_ DACU SG_ 840 TrafficSign00_TimeStamp 3000;
BA_REL_ "GenSigTimeoutTime" BU_SG_REL_ DACU SG_ 840 TrafficSign00_TimeStamp 120;
BA_REL_ "GenSigFirstTimeoutTime" BU_SG_REL_ DACU SG_ 840 TrafficSign00_SupplSign00Conf 3000;
BA_REL_ "GenSigTimeoutTime" BU_SG_REL_ DACU SG_ 840 TrafficSign00_SupplSign00Conf 120;
BA_REL_ "GenSigFirstTimeoutTime" BU_SG_REL_ DACU SG_ 840 TrafficSign00_RestWeight 3000;
BA_REL_ "GenSigTimeoutTime" BU_SG_REL_ DACU SG_ 840 TrafficSign00_RestWeight 120;
VAL_ 850 VisionProperties_LaneChange 3 "LaneChange2_NotAvailable" 2 "LaneChange2_LeftLaneChange" 1 "LaneChange2_RightLaneChange" 0 "LaneChange2_NoLaneChange" ;
VAL_ 850 VisionProperties_StreetLight 7 "StreetLight_NotAvailable" 6 "StreetLight_Error" 5 "StreetLight_Spare2" 4 "StreetLight_Spare1" 3 "StreetLight_NotInThePath" 2 "StreetLight_InThePath" 1 "StreetLight_FarAhead" 0 "StreetLight_NoStreetLight" ;
VAL_ 850 FLCVideoOutStatus 15 "FLCVideoOutStatus_NotAvailable" 14 "FLCVideoOutStatus_Error" 13 "FLCVideoOutStatus_Spare10" 12 "FLCVideoOutStatus_Spare9" 11 "FLCVideoOutStatus_Spare8" 10 "FLCVideoOutStatus_Spare7" 9 "FLCVideoOutStatus_Spare6" 8 "FLCVideoOutStatus_Spare5" 7 "FLCVideoOutStatus_Spare4" 6 "FLCVideoOutStatus_Spare3" 5 "FLCVideoOutStatus_ReadyForStream" 4 "FLCVideoOutStatus_Off" 3 "FLCVideoOutStatus_StreamActiveWith1Fps" 2 "FLCVideoOutStatus_StreamActiveWith5Fps" 1 "FLCVideoOutStatus_StreamActiveWith7P5Fps" 0 "FLCVideoOutStatus_StreamActiveWith15Fps" ;
VAL_ 850 VisionProperties_Weather 15 "Weather_NotAvailable" 14 "Weather_Error" 13 "Weather_spare8" 12 "Weather_spare7" 11 "Weather_spare6" 10 "Weather_spare5" 9 "Weather_spare4" 8 "Weather_spare3" 7 "Weather_spare2" 6 "Weather_spare1" 5 "Weather_Unknown" 4 "Weather_Hail" 3 "Weather_Snow" 2 "Weather_Rain" 1 "Weather_Fog" 0 "Weather_Clear" ;
VAL_ 872 TrafficSign11_TrackStatus 7 "TrackStatus_NotAvailable" 6 "TrackStatus_Error" 5 "TrackStatus_Spare3" 4 "TrackStatus_Spare2" 3 "TrackStatus_Spare1" 2 "TrackStatus_Invalid" 1 "TrackStatus_Predicted" 0 "TrackStatus_Tracked" ;
VAL_ 872 TrafficSign11_SignStability 1 "FalseTrue1bit_True" 0 "FalseTrue1bit_False" ;
VAL_ 871 TrafficSign10_SignStability 1 "FalseTrue1bit_True" 0 "FalseTrue1bit_False" ;
VAL_ 871 TrafficSign10_TrackStatus 7 "TrackStatus_NotAvailable" 6 "TrackStatus_Error" 5 "TrackStatus_Spare3" 4 "TrackStatus_Spare2" 3 "TrackStatus_Spare1" 2 "TrackStatus_Invalid" 1 "TrackStatus_Predicted" 0 "TrackStatus_Tracked" ;
VAL_ 870 TrafficSign09_SignStability 1 "FalseTrue1bit_True" 0 "FalseTrue1bit_False" ;
VAL_ 870 TrafficSign09_TrackStatus 7 "TrackStatus_NotAvailable" 6 "TrackStatus_Error" 5 "TrackStatus_Spare3" 4 "TrackStatus_Spare2" 3 "TrackStatus_Spare1" 2 "TrackStatus_Invalid" 1 "TrackStatus_Predicted" 0 "TrackStatus_Tracked" ;
VAL_ 869 TrafficSign08_SignStability 1 "FalseTrue1bit_True" 0 "FalseTrue1bit_False" ;
VAL_ 869 TrafficSign08_TrackStatus 7 "TrackStatus_NotAvailable" 6 "TrackStatus_Error" 5 "TrackStatus_Spare3" 4 "TrackStatus_Spare2" 3 "TrackStatus_Spare1" 2 "TrackStatus_Invalid" 1 "TrackStatus_Predicted" 0 "TrackStatus_Tracked" ;
VAL_ 868 TrafficSign07_TrackStatus 7 "TrackStatus_NotAvailable" 6 "TrackStatus_Error" 5 "TrackStatus_Spare3" 4 "TrackStatus_Spare2" 3 "TrackStatus_Spare1" 2 "TrackStatus_Invalid" 1 "TrackStatus_Predicted" 0 "TrackStatus_Tracked" ;
VAL_ 868 TrafficSign07_SignStability 1 "FalseTrue1bit_True" 0 "FalseTrue1bit_False" ;
VAL_ 867 TrafficSign06_SignStability 1 "FalseTrue1bit_True" 0 "FalseTrue1bit_False" ;
VAL_ 867 TrafficSign06_TrackStatus 7 "TrackStatus_NotAvailable" 6 "TrackStatus_Error" 5 "TrackStatus_Spare3" 4 "TrackStatus_Spare2" 3 "TrackStatus_Spare1" 2 "TrackStatus_Invalid" 1 "TrackStatus_Predicted" 0 "TrackStatus_Tracked" ;
VAL_ 866 TrafficSign05_SignStability 1 "FalseTrue1bit_True" 0 "FalseTrue1bit_False" ;
VAL_ 866 TrafficSign05_TrackStatus 7 "TrackStatus_NotAvailable" 6 "TrackStatus_Error" 5 "TrackStatus_Spare3" 4 "TrackStatus_Spare2" 3 "TrackStatus_Spare1" 2 "TrackStatus_Invalid" 1 "TrackStatus_Predicted" 0 "TrackStatus_Tracked" ;
VAL_ 865 TrafficSign04_TrackStatus 7 "TrackStatus_NotAvailable" 6 "TrackStatus_Error" 5 "TrackStatus_Spare3" 4 "TrackStatus_Spare2" 3 "TrackStatus_Spare1" 2 "TrackStatus_Invalid" 1 "TrackStatus_Predicted" 0 "TrackStatus_Tracked" ;
VAL_ 865 TrafficSign04_SignStability 1 "FalseTrue1bit_True" 0 "FalseTrue1bit_False" ;
VAL_ 849 TrafficSign03_TrackStatus 7 "TrackStatus_NotAvailable" 6 "TrackStatus_Error" 5 "TrackStatus_Spare3" 4 "TrackStatus_Spare2" 3 "TrackStatus_Spare1" 2 "TrackStatus_Invalid" 1 "TrackStatus_Predicted" 0 "TrackStatus_Tracked" ;
VAL_ 849 TrafficSign03_SignStability 1 "FalseTrue1bit_True" 0 "FalseTrue1bit_False" ;
VAL_ 848 TrafficSign02_SignStability 1 "FalseTrue1bit_True" 0 "FalseTrue1bit_False" ;
VAL_ 848 TrafficSign02_TrackStatus 7 "TrackStatus_NotAvailable" 6 "TrackStatus_Error" 5 "TrackStatus_Spare3" 4 "TrackStatus_Spare2" 3 "TrackStatus_Spare1" 2 "TrackStatus_Invalid" 1 "TrackStatus_Predicted" 0 "TrackStatus_Tracked" ;
VAL_ 841 TrafficSign01_SignStability 1 "FalseTrue1bit_True" 0 "FalseTrue1bit_False" ;
VAL_ 841 TrafficSign01_TrackStatus 7 "TrackStatus_NotAvailable" 6 "TrackStatus_Error" 5 "TrackStatus_Spare3" 4 "TrackStatus_Spare2" 3 "TrackStatus_Spare1" 2 "TrackStatus_Invalid" 1 "TrackStatus_Predicted" 0 "TrackStatus_Tracked" ;
VAL_ 840 TrafficSign00_TrackStatus 7 "TrackStatus_NotAvailable" 6 "TrackStatus_Error" 5 "TrackStatus_Spare3" 4 "TrackStatus_Spare2" 3 "TrackStatus_Spare1" 2 "TrackStatus_Invalid" 1 "TrackStatus_Predicted" 0 "TrackStatus_Tracked" ;
VAL_ 840 TrafficSign00_SignStability 1 "FalseTrue1bit_True" 0 "FalseTrue1bit_False" ;
SIG_GROUP_ 850 VisionProperties_sg 1 : VisionProperties_LaneChange VisionProperties_AmbientLight VisionProperties_StreetLight VisionProperties_NightDay VisionProperties_BlockConf VisionProperties_Weather;
SIG_GROUP_ 872 TrafficSign11_sg 1 : TrafficSign11_SupplSignValue01 TrafficSign11_SupplSignType02 TrafficSign11_TrackStatus TrafficSign11_SupplSignValue02 TrafficSign11_RestDist TrafficSign11_MainSignValue TrafficSign11_SupplSignType01 TrafficSign11_RestHeight TrafficSign11_SupplSign02Conf TrafficSign11_MainSignConfidence TrafficSign11_RestSection TrafficSign11_RestTime1 TrafficSign11_TimeStamp TrafficSign11_RestWeight TrafficSign11_RestWidth TrafficSign11_Height TrafficSign11_MainSignType TrafficSign11_ID TrafficSign11_RestTime3 TrafficSign11_SupplSignValue00 TrafficSign11_RestDay TrafficSign11_LongDist TrafficSign11_RestTime2 TrafficSign11_SupplSignType00 TrafficSign11_SupplSign00Conf TrafficSign11_SupplSign01Conf TrafficSign11_LatDist TrafficSign11_RestTime0 TrafficSign11_SignStability;
SIG_GROUP_ 871 TrafficSign10_sg 1 : TrafficSign10_SupplSignType02 TrafficSign10_SignStability TrafficSign10_ID TrafficSign10_SupplSignValue00 TrafficSign10_RestTime2 TrafficSign10_RestSection TrafficSign10_SupplSign00Conf TrafficSign10_MainSignType TrafficSign10_RestTime3 TrafficSign10_RestHeight TrafficSign10_RestTime1 TrafficSign10_SupplSignType01 TrafficSign10_RestWidth TrafficSign10_SupplSign02Conf TrafficSign10_SupplSignValue01 TrafficSign10_TimeStamp TrafficSign10_LongDist TrafficSign10_SupplSignValue02 TrafficSign10_SupplSign01Conf TrafficSign10_SupplSignType00 TrafficSign10_Height TrafficSign10_TrackStatus TrafficSign10_RestWeight TrafficSign10_RestDay TrafficSign10_MainSignConfidence TrafficSign10_RestDist TrafficSign10_RestTime0 TrafficSign10_MainSignValue TrafficSign10_LatDist;
SIG_GROUP_ 870 TrafficSign09_sg 1 : TrafficSign09_MainSignValue TrafficSign09_RestTime0 TrafficSign09_LongDist TrafficSign09_SupplSign00Conf TrafficSign09_MainSignConfidence TrafficSign09_Height TrafficSign09_RestTime2 TrafficSign09_MainSignType TrafficSign09_SupplSignType02 TrafficSign09_SupplSign01Conf TrafficSign09_RestSection TrafficSign09_SupplSign02Conf TrafficSign09_SupplSignValue01 TrafficSign09_RestWeight TrafficSign09_LatDist TrafficSign09_SignStability TrafficSign09_RestTime1 TrafficSign09_SupplSignType00 TrafficSign09_RestHeight TrafficSign09_RestDay TrafficSign09_RestDist TrafficSign09_SupplSignValue00 TrafficSign09_TrackStatus TrafficSign09_RestTime3 TrafficSign09_SupplSignType01 TrafficSign09_ID TrafficSign09_RestWidth TrafficSign09_SupplSignValue02 TrafficSign09_TimeStamp;
SIG_GROUP_ 869 TrafficSign08_sg 1 : TrafficSign08_SupplSign00Conf TrafficSign08_SignStability TrafficSign08_MainSignType TrafficSign08_SupplSign02Conf TrafficSign08_RestHeight TrafficSign08_LatDist TrafficSign08_SupplSignType02 TrafficSign08_SupplSignType01 TrafficSign08_SupplSign01Conf TrafficSign08_MainSignConfidence TrafficSign08_RestSection TrafficSign08_RestTime3 TrafficSign08_TimeStamp TrafficSign08_RestDist TrafficSign08_SupplSignType00 TrafficSign08_RestTime2 TrafficSign08_SupplSignValue02 TrafficSign08_TrackStatus TrafficSign08_RestWeight TrafficSign08_SupplSignValue01 TrafficSign08_RestTime0 TrafficSign08_LongDist TrafficSign08_MainSignValue TrafficSign08_RestWidth TrafficSign08_RestDay TrafficSign08_ID TrafficSign08_Height TrafficSign08_SupplSignValue00 TrafficSign08_RestTime1;
SIG_GROUP_ 868 TrafficSign07_sg 1 : TrafficSign07_MainSignConfidence TrafficSign07_SupplSign00Conf TrafficSign07_SupplSign01Conf TrafficSign07_SupplSignValue00 TrafficSign07_RestTime3 TrafficSign07_SupplSign02Conf TrafficSign07_ID TrafficSign07_SupplSignType01 TrafficSign07_TrackStatus TrafficSign07_RestSection TrafficSign07_SupplSignValue02 TrafficSign07_SupplSignType00 TrafficSign07_RestTime2 TrafficSign07_Height TrafficSign07_LatDist TrafficSign07_SupplSignType02 TrafficSign07_SignStability TrafficSign07_RestDist TrafficSign07_RestDay TrafficSign07_RestWidth TrafficSign07_TimeStamp TrafficSign07_RestTime1 TrafficSign07_RestTime0 TrafficSign07_SupplSignValue01 TrafficSign07_LongDist TrafficSign07_MainSignType TrafficSign07_MainSignValue TrafficSign07_RestWeight TrafficSign07_RestHeight;
SIG_GROUP_ 867 TrafficSign06_sg 1 : TrafficSign06_RestWeight TrafficSign06_SupplSign01Conf TrafficSign06_SupplSignValue02 TrafficSign06_RestTime1 TrafficSign06_SupplSignType02 TrafficSign06_SignStability TrafficSign06_SupplSign00Conf TrafficSign06_MainSignValue TrafficSign06_SupplSign02Conf TrafficSign06_SupplSignValue01 TrafficSign06_RestTime2 TrafficSign06_Height TrafficSign06_LatDist TrafficSign06_MainSignType TrafficSign06_LongDist TrafficSign06_TimeStamp TrafficSign06_RestDist TrafficSign06_RestTime0 TrafficSign06_SupplSignType01 TrafficSign06_TrackStatus TrafficSign06_MainSignConfidence TrafficSign06_RestHeight TrafficSign06_RestSection TrafficSign06_RestDay TrafficSign06_SupplSignValue00 TrafficSign06_ID TrafficSign06_RestWidth TrafficSign06_RestTime3 TrafficSign06_SupplSignType00;
SIG_GROUP_ 866 TrafficSign05_sg 1 : TrafficSign05_SupplSignType00 TrafficSign05_ID TrafficSign05_SupplSignValue00 TrafficSign05_MainSignConfidence TrafficSign05_RestDay TrafficSign05_MainSignType TrafficSign05_SupplSignType01 TrafficSign05_LongDist TrafficSign05_RestSection TrafficSign05_MainSignValue TrafficSign05_SupplSignValue01 TrafficSign05_TimeStamp TrafficSign05_Height TrafficSign05_SupplSign02Conf TrafficSign05_SignStability TrafficSign05_SupplSignValue02 TrafficSign05_TrackStatus TrafficSign05_LatDist TrafficSign05_RestHeight TrafficSign05_RestTime1 TrafficSign05_RestWidth TrafficSign05_RestTime3 TrafficSign05_RestDist TrafficSign05_RestTime2 TrafficSign05_RestTime0 TrafficSign05_SupplSign00Conf TrafficSign05_SupplSignType02 TrafficSign05_SupplSign01Conf TrafficSign05_RestWeight;
SIG_GROUP_ 865 TrafficSign04_sg 1 : TrafficSign04_TrackStatus TrafficSign04_MainSignType TrafficSign04_SupplSignValue00 TrafficSign04_RestTime1 TrafficSign04_SupplSignValue01 TrafficSign04_RestTime2 TrafficSign04_Height TrafficSign04_SupplSign00Conf TrafficSign04_SupplSign01Conf TrafficSign04_SupplSign02Conf TrafficSign04_SupplSignType02 TrafficSign04_LongDist TrafficSign04_RestTime0 TrafficSign04_RestWidth TrafficSign04_SupplSignType00 TrafficSign04_RestDay TrafficSign04_SupplSignType01 TrafficSign04_MainSignConfidence TrafficSign04_RestHeight TrafficSign04_MainSignValue TrafficSign04_RestSection TrafficSign04_RestDist TrafficSign04_ID TrafficSign04_RestTime3 TrafficSign04_SignStability TrafficSign04_LatDist TrafficSign04_TimeStamp TrafficSign04_SupplSignValue02 TrafficSign04_RestWeight;
SIG_GROUP_ 849 TrafficSign03_sg 1 : TrafficSign03_Height TrafficSign03_ID TrafficSign03_TrackStatus TrafficSign03_RestHeight TrafficSign03_MainSignConfidence TrafficSign03_RestDay TrafficSign03_LongDist TrafficSign03_RestTime3 TrafficSign03_SupplSignType00 TrafficSign03_RestTime1 TrafficSign03_SupplSignValue00 TrafficSign03_RestTime0 TrafficSign03_SupplSignType02 TrafficSign03_RestWidth TrafficSign03_MainSignValue TrafficSign03_RestTime2 TrafficSign03_SupplSign01Conf TrafficSign03_LatDist TrafficSign03_RestWeight TrafficSign03_TimeStamp TrafficSign03_RestDist TrafficSign03_SupplSign00Conf TrafficSign03_SupplSignType01 TrafficSign03_SupplSign02Conf TrafficSign03_RestSection TrafficSign03_SupplSignValue02 TrafficSign03_MainSignType TrafficSign03_SignStability TrafficSign03_SupplSignValue01;
SIG_GROUP_ 848 TrafficSign02_sg 1 : TrafficSign02_RestTime1 TrafficSign02_RestHeight TrafficSign02_Height TrafficSign02_SignStability TrafficSign02_SupplSignType00 TrafficSign02_ID TrafficSign02_LatDist TrafficSign02_MainSignType TrafficSign02_SupplSignValue01 TrafficSign02_SupplSign00Conf TrafficSign02_SupplSignType01 TrafficSign02_RestTime2 TrafficSign02_MainSignConfidence TrafficSign02_SupplSignValue02 TrafficSign02_TimeStamp TrafficSign02_RestSection TrafficSign02_RestDist TrafficSign02_RestDay TrafficSign02_SupplSign02Conf TrafficSign02_SupplSign01Conf TrafficSign02_LongDist TrafficSign02_MainSignValue TrafficSign02_TrackStatus TrafficSign02_SupplSignType02 TrafficSign02_RestWeight TrafficSign02_RestTime0 TrafficSign02_SupplSignValue00 TrafficSign02_RestWidth TrafficSign02_RestTime3;
SIG_GROUP_ 841 TrafficSign01_sg 1 : TrafficSign01_SupplSign02Conf TrafficSign01_RestTime0 TrafficSign01_RestTime1 TrafficSign01_RestTime3 TrafficSign01_RestDay TrafficSign01_ID TrafficSign01_MainSignValue TrafficSign01_MainSignType TrafficSign01_LatDist TrafficSign01_RestWidth TrafficSign01_RestWeight TrafficSign01_SupplSignType01 TrafficSign01_SupplSignValue02 TrafficSign01_SupplSignValue00 TrafficSign01_TimeStamp TrafficSign01_SignStability TrafficSign01_RestTime2 TrafficSign01_SupplSign00Conf TrafficSign01_SupplSignType02 TrafficSign01_TrackStatus TrafficSign01_SupplSign01Conf TrafficSign01_LongDist TrafficSign01_Height TrafficSign01_SupplSignType00 TrafficSign01_RestSection TrafficSign01_MainSignConfidence TrafficSign01_RestDist TrafficSign01_RestHeight TrafficSign01_SupplSignValue01;
SIG_GROUP_ 840 TrafficSign00_sg 1 : TrafficSign00_RestWidth TrafficSign00_RestTime3 TrafficSign00_RestSection TrafficSign00_SupplSignValue01 TrafficSign00_SupplSignValue00 TrafficSign00_SupplSign02Conf TrafficSign00_ID TrafficSign00_SupplSign01Conf TrafficSign00_SupplSignType01 TrafficSign00_SupplSignType00 TrafficSign00_LongDist TrafficSign00_RestDay TrafficSign00_MainSignConfidence TrafficSign00_MainSignValue TrafficSign00_Height TrafficSign00_SupplSignType02 TrafficSign00_RestTime1 TrafficSign00_RestHeight TrafficSign00_RestTime2 TrafficSign00_RestTime0 TrafficSign00_TrackStatus TrafficSign00_RestDist TrafficSign00_MainSignType TrafficSign00_SignStability TrafficSign00_SupplSignValue02 TrafficSign00_LatDist TrafficSign00_TimeStamp TrafficSign00_SupplSign00Conf TrafficSign00_RestWeight;
SIG_GROUP_ 858 FLCEgoAssumption_sg 1 : FLCEgoAssumption_DynRoll FLCEgoAssumption_EgoLongAcc FLCEgoAssumption_CalibPitch FLCEgoAssumption_EgoLongVel FLCEgoAssumption_CalibRoll FLCEgoAssumption_TimeStamp FLCEgoAssumption_CalibYaw FLCEgoAssumption_DynPitch;
